VERSION ""

NS_ :

BS_:

BU_: FUSION ZONE_FR ZONE_DR DKC

BO_ 596 GW_ZoneFR3: 32 ZONE_FR
 SG_ EXV_Rsp_Pos : 7|16@0+ (1,0) [0|576] "" FUSION
 SG_ EXV_Rsp_Fault_Stat : 23|4@0+ (1,0) [0|1] "" FUSION
 SG_ EXV_Rsp_CurInit_Stat : 19|2@0+ (1,0) [0|1] "" FUSION
 SG_ EXV_Rsp_OvrTemp_Warn : 17|2@0+ (1,0) [0|1] "" FUSION
 SG_ EXV_Rsp_Volt_Stat : 31|2@0+ (1,0) [0|1] "" FUSION
 SG_ EXV_RsErr_EXV : 29|1@0+ (1,0) [0|1] "" FUSION
 SG_ EXV_Rsp_Run_Stat : 28|1@0+ (1,0) [0|1] "" FUSION
 SG_ EWP1_RsErr_EWP : 26|1@0+ (1,0) [0|1] "" FUSION
 SG_ EWP1_SupVolt_Error : 25|2@0+ (1,0) [0|2] "" FUSION
 SG_ EWP1_RPM_Target_Stat : 39|8@0+ (1,0) [0|254] "" FUSION
 SG_ EWP1_RPM_ActlVal_Stat : 47|8@0+ (1,0) [0|254] "" FUSION
 SG_ EWP1_Curr_Stat : 55|8@0+ (0.1,0) [0|25.4] "A" FUSION
 SG_ EWP1_Block_Error : 63|2@0+ (1,0) [0|2] "" FUSION
 SG_ EWP1_DryRun_Error : 61|2@0+ (1,0) [0|2] "" FUSION
 SG_ EWP1_OverCurr_Error : 59|2@0+ (1,0) [0|2] "" FUSION
 SG_ EWP1_OverTemp_Error : 57|2@0+ (1,0) [0|2] "" FUSION
 SG_ EWP1_Temp_Stat : 71|8@0+ (1,-50) [-50|205] "Deg" FUSION
 SG_ EWP1_Volt_Stat : 79|8@0+ (0.1,0) [0|25.5] "V" FUSION
 SG_ EWP2_Volt_Stat : 87|8@0+ (0.1,0) [0|25.4] "V" FUSION
 SG_ EWP2_Temp_Stat : 95|8@0+ (1,-50) [-50|205] "Deg" FUSION
 SG_ EWP2_RPM_Target_Stat : 103|8@0+ (1,0) [0|254] "" FUSION
 SG_ EWP2_RPM_ActlVal_Stat : 111|8@0+ (1,0) [0|254] "" FUSION
 SG_ EWP2_Curr_Stat : 119|8@0+ (0.1,0) [0|25.4] "A" FUSION
 SG_ EWP2_Block_Error : 127|2@0+ (1,0) [0|2] "" FUSION
 SG_ EWP2_DryRun_Error : 125|2@0+ (1,0) [0|2] "" FUSION
 SG_ EWP2_OverCurr_Error : 123|2@0+ (1,0) [0|2] "" FUSION
 SG_ EWP2_OverTemp_Error : 121|2@0+ (1,0) [0|2] "" FUSION
 SG_ EWP2_SupVolt_Error : 135|2@0+ (1,0) [0|2] "" FUSION
 SG_ EWP2_RsErr_EWP : 133|1@0+ (1,0) [0|1] "" FUSION
 SG_ EWP3_Block_Error : 131|2@0+ (1,0) [0|2] "" FUSION
 SG_ EWP3_DryRun_Error : 129|2@0+ (1,0) [0|2] "" FUSION
 SG_ EWP3_RPM_Target_Stat : 143|8@0+ (1,0) [0|254] "" FUSION
 SG_ EWP3_RPM_ActlVal_Stat : 151|8@0+ (1,0) [0|254] "" FUSION
 SG_ EWP3_Curr_Stat : 159|8@0+ (0.1,0) [0|25.4] "A" FUSION
 SG_ EWP3_OverCurr_Error : 167|2@0+ (1,0) [0|2] "" FUSION
 SG_ EWP3_OverTemp_Error : 165|2@0+ (1,0) [0|2] "" FUSION
 SG_ EWP3_SupVolt_Error : 163|2@0+ (1,0) [0|2] "" FUSION
 SG_ EWP3_RsErr_EWP : 161|1@0+ (1,0) [0|1] "" FUSION
 SG_ EWP3_Temp_Stat : 175|8@0+ (1,-50) [-50|205] "Deg" FUSION
 SG_ EWP3_Volt_Stat : 183|8@0+ (0.1,0) [0|25.4] "V" FUSION
 SG_ EXV2_Rsp_Pos : 191|16@0+ (1,0) [0|576] "" FUSION
 SG_ EXV2_Rsp_Fault_Stat : 207|4@0+ (1,0) [0|1] "" FUSION
 SG_ EXV2_Rsp_CurInit_Stat : 203|2@0+ (1,0) [0|1] "" FUSION
 SG_ EXV2_Rsp_OvrTemp_Warn : 201|2@0+ (1,0) [0|1] "" FUSION
 SG_ EXV2_Rsp_Volt_Stat : 215|2@0+ (1,0) [0|1] "" FUSION
 SG_ EXV2_RsErr_EXV : 213|1@0+ (1,0) [0|1] "" FUSION
 SG_ EXV2_Rsp_Run_Stat : 212|1@0+ (1,0) [0|1] "" FUSION
 SG_ CCV4_Fault_Signal : 211|4@0+ (1,0) [0|1] "" FUSION
 SG_ BDC_1_Rsp_Comm_Err : 223|1@0+ (1,0) [0|1] "" FUSION
 SG_ CCV4_TempWarn : 222|1@0+ (1,0) [0|1] "" FUSION
 SG_ CCV4_Rsp_Comm_Err : 221|1@0+ (1,0) [0|1] "" FUSION
 SG_ CCV4_MotorStatus : 220|1@0+ (1,0) [0|1] "" FUSION
 SG_ CCV4_RespPos : 219|2@0+ (1,0) [0|1] "" FUSION
 SG_ CCV4_voltageErr : 217|2@0+ (1,0) [0|1] "" FUSION
 SG_ BDC_1_Fault_Signal : 231|4@0+ (1,0) [0|1] "" FUSION
 SG_ BDC_1_voltageErr : 227|2@0+ (1,0) [0|1] "" FUSION
 SG_ BDC_1_TempWarn : 225|1@0+ (1,0) [0|1] "" FUSION
 SG_ BDC_1_MotorStatus : 224|1@0+ (1,0) [0|1] "" FUSION
 SG_ BDC_1_RespPos : 239|8@0+ (0.392,0) [0|99.96] "" FUSION

BO_ 602 GW_METER1: 24 FUSION
 SG_ METER_KPH_Calcu : 15|8@0+ (1,0) [0|254] "km/h" ZONE_DR
 SG_ METER_MPH_Calcu : 23|8@0+ (1,0) [0|160] "mph" Vector__XXX
 SG_ METER_KPH_Real : 31|12@0+ (0.125,0) [0|255.875] "km/h" Vector__XXX
 SG_ METER_MPH_Real : 35|12@0+ (0.077675,0) [0|160.0105] "mph" Vector__XXX
 SG_ Averaged_vehspeed : 49|10@0+ (1,0) [0|300] "km/h" Vector__XXX
 SG_ AVGPwrConsumption : 71|16@0+ (0.1,-999.9) [-999.9|999.9] "Wh/km" Vector__XXX
 SG_ APCforDTE : 87|16@0+ (0.1,-999.9) [-999.9|999.9] "Wh/km" Vector__XXX
 SG_ AvailableTrip : 103|16@0+ (0.1,0) [0|999.9] "KM" Vector__XXX
 SG_ Spd_Crl_Mode : 118|3@0+ (1,0) [0|7] "" Vector__XXX
 SG_ Spd_Crl_Sta : 115|1@0+ (1,0) [0|1] "" Vector__XXX
 SG_ LEDlitWarnReq : 114|1@0+ (1,0) [0|1] "" Vector__XXX
 SG_ Charge : 113|1@0+ (1,0) [0|1] "" Vector__XXX
 SG_ ParkBrake : 112|1@0+ (1,0) [0|1] "" Vector__XXX
 SG_ Trip_B : 127|24@0+ (0.1,0) [0|99999.9] "KM" Vector__XXX
 SG_ Trip_A : 151|24@0+ (0.1,0) [0|99999.9] "KM" Vector__XXX
 SG_ ODOMETER : 175|24@0+ (0.1,0) [0|999999.9] "KM" Vector__XXX

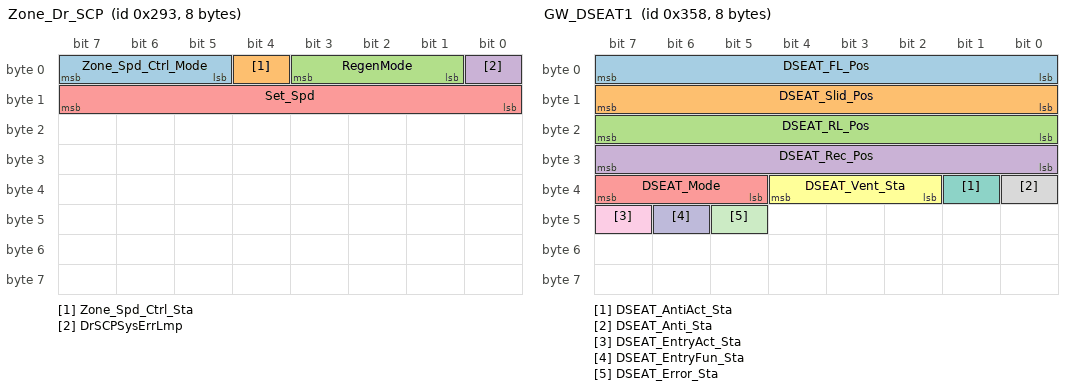
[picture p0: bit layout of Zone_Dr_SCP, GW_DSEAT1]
BO_ 659 Zone_Dr_SCP: 8 ZONE_DR
 SG_ Zone_Spd_Ctrl_Mode : 7|3@0+ (1,0) [0|7] "" FUSION
 SG_ Zone_Spd_Ctrl_Sta : 4|1@0+ (1,0) [0|1] "" FUSION
 SG_ RegenMode : 3|3@0+ (1,0) [0|7] "" FUSION
 SG_ DrSCPSysErrLmp : 0|1@0+ (1,0) [0|1] "" FUSION
 SG_ Set_Spd : 15|8@0+ (1,0) [0|255] "km/h" FUSION

BO_ 778 GW_ZoneFR2: 32 ZONE_FR
 SG_ PTCActuPWMDutyHSC6 : 7|8@0+ (0.5,0) [0|100] "" FUSION
 SG_ PTCIGBTTemHSC6 : 15|9@0+ (0.5,-40) [-40|200] "" FUSION
 SG_ CCM_SpdCmd : 22|15@0+ (0.5,0) [0|8300] "RPM" FUSION
 SG_ EAC_Temp : 39|8@0+ (1,-40) [0|210] "Deg^C" FUSION
 SG_ PTCNTCStsHSC6 : 47|3@0+ (1,0) [0|7] "" FUSION
 SG_ EAC_DrvVoltFalt : 63|1@0+ (1,0) [0|1] "" FUSION
 SG_ EAC_MotorLackFalt : 62|1@0+ (1,0) [0|1] "" FUSION
 SG_ EAC_OvLoadFalt : 61|1@0+ (1,0) [0|1] "" FUSION
 SG_ EAC_TempSnsrFalt : 60|1@0+ (1,0) [0|1] "" FUSION
 SG_ CompProEN : 59|1@0+ (1,0) [0|1] "" FUSION
 SG_ COMP_ComLost : 58|1@0+ (1,0) [0|1] "" FUSION
 SG_ COMP_IPM_HWFLt : 57|1@0+ (1,0) [0|1] "" FUSION
 SG_ COMP_IPM_TempOverFlt : 56|1@0+ (1,0) [0|1] "" FUSION
 SG_ COMP_CurOverProtect : 71|1@0+ (1,0) [0|1] "" FUSION
 SG_ COMP_VoltOverErr : 70|1@0+ (1,0) [0|1] "" FUSION
 SG_ COMP_VoltLessErr : 69|1@0+ (1,0) [0|1] "" FUSION
 SG_ COMP_CtrlCircFlt : 68|1@0+ (1,0) [0|1] "" FUSION
 SG_ COMP_Sta : 67|2@0+ (1,0) [0|3] "" FUSION
 SG_ COMP_Init : 65|1@0+ (1,0) [0|1] "" FUSION
 SG_ COMP_SpdVaild : 64|1@0+ (1,0) [0|1] "" FUSION
 SG_ EAC_MotCrt : 79|8@0+ (0.2,0) [0|51] "A" FUSION
 SG_ COMP_CurVaild : 87|1@0+ (1,0) [0|1] "" FUSION
 SG_ COMP_VoltVaild : 86|1@0+ (1,0) [0|1] "" FUSION
 SG_ COMP_StatorSpd : 85|14@0+ (1,0) [0|8500] "RPM" FUSION
 SG_ COMP_ConCur : 103|16@0+ (0.02,0) [0|1310.7] "A" FUSION
 SG_ COMP_ConVolt : 119|16@0+ (0.02,0) [0|1310.7] "V" FUSION
 SG_ PTCSecRlngCtrHSC6 : 135|4@0+ (1,0) [0|15] "" FUSION
 SG_ PTCOtptTemHSC6 : 128|9@0+ (0.5,-40) [-40|200] "" FUSION
 SG_ PTCRlngCtrHSC6 : 151|4@0+ (1,0) [0|15] "" FUSION
 SG_ PTCOverVolHSC6 : 131|1@0+ (1,0) [0|1] "" FUSION
 SG_ PTCOverCrntHSC6 : 130|1@0+ (1,0) [0|1] "" FUSION
 SG_ PTCOverHeatHSC6 : 129|1@0+ (1,0) [0|1] "" FUSION
 SG_ PTCPCBTemHSC6 : 144|9@0+ (0.5,-40) [-40|200] "" FUSION
 SG_ PTCActuCrntHSC6 : 161|10@0+ (0.1,-20) [-20|82] "" FUSION
 SG_ PTCStsHSC6 : 166|2@0+ (1,0) [0|3] "" FUSION
 SG_ PTCIGBTOverHeatHSC6 : 145|1@0+ (1,0) [0|1] "" FUSION
 SG_ PTCHVLckStsHSC6 : 146|1@0+ (1,0) [0|1] "" FUSION
 SG_ PTCIGBTStsHSC6 : 147|1@0+ (1,0) [0|1] "" FUSION
 SG_ PTCUnderVolHSC6 : 167|1@0+ (1,0) [0|1] "" FUSION
 SG_ PTCFltLvlHSC6 : 199|4@0+ (1,0) [0|15] "" FUSION
 SG_ PTCChksmHSC6 : 183|8@0+ (1,0) [0|255] "" FUSION
 SG_ PTCSecChksmHSC6 : 191|8@0+ (1,0) [0|255] "" FUSION
 SG_ PTCActuVolHSC6 : 193|10@0+ (0.5,100) [100|500] "" FUSION
 SG_ BMSPackVol_h6HSC6 : 211|12@0+ (0.25,0) [0|1023.75] "V" FUSION

BO_ 796 GW_ZoneFR4: 12 ZONE_FR
 SG_ BMSReqRlngCtrHSC6 : 7|4@0+ (1,0) [0|15] "" FUSION
 SG_ BMSReqTapPosHSC6 : 3|4@0+ (1,0) [0|15] "" FUSION
 SG_ BMSReqPwrHSC6 : 15|16@0+ (1,0) [0|65535] "" FUSION
 SG_ BMSReqPWMHSC6 : 31|7@0+ (1,0) [0|100] "" FUSION
 SG_ BMSInptClntTemHSC6 : 24|9@0+ (0.5,-40) [-40|200] "" FUSION
 SG_ BMSReqMdHSC6 : 71|2@0+ (1,0) [0|3] "" FUSION
 SG_ BMSEnbPTCHSC6 : 69|1@0+ (1,0) [0|1] "" FUSION
 SG_ BMSChksmHSC6 : 47|8@0+ (1,0) [0|255] "" FUSION
 SG_ PTCActuPwrHSC6 : 55|16@0+ (1,0) [0|65535] "" FUSION
 SG_ COMP_ActualPwr : 68|13@0+ (1,0) [0|6000] "W" FUSION

BO_ 804 GW_ZoneDR7: 48 ZONE_DR
 SG_ ACT5_Stop_mode_status : 71|2@0+ (1,0) [0|0] "" FUSION
 SG_ ACT5_Rotation_direction_status : 69|2@0+ (1,0) [0|0] "" FUSION
 SG_ ACT5_Emergency_run_position_status : 67|2@0+ (1,0) [0|0] "" FUSION
 SG_ ACT5_Emergency_run_release_status : 65|2@0+ (1,0) [0|0] "" FUSION
 SG_ ACT5_Actuator_address_status : 79|8@0+ (1,0) [0|0] "" FUSION
 SG_ ACT5_Special_functions : 85|2@0+ (1,0) [0|0] "" FUSION
 SG_ ACT5_Self_holding_torque : 83|2@0+ (1,0) [0|0] "" FUSION
 SG_ ACT5_Movement_direction : 81|2@0+ (1,0) [0|0] "" FUSION
 SG_ ACT5_Actual_position_of_actuator : 95|16@0+ (1,0) [0|0] "" FUSION
 SG_ ACT5_Speed_status : 111|4@0+ (1,0) [0|0] "" FUSION
 SG_ ACT5_Position_specification_status : 107|2@0+ (1,0) [0|0] "" FUSION
 SG_ ACT5_Applied_holding_current_status : 105|2@0+ (1,0) [0|0] "" FUSION
 SG_ ACT5_Reset : 119|2@0+ (1,0) [0|0] "" FUSION
 SG_ ACT5_Stall_occurred : 117|2@0+ (1,0) [0|0] "" FUSION
 SG_ ACT5_Stall_detection_release_status : 115|2@0+ (1,0) [0|0] "" FUSION
 SG_ ACT5_Emergency_run_occurred : 113|2@0+ (1,0) [0|0] "" FUSION
 SG_ ACT5_Supply_voltage : 127|2@0+ (1,0) [0|0] "" FUSION
 SG_ ACT5_Electrical_defect : 125|2@0+ (1,0) [0|0] "" FUSION
 SG_ ACT5_Over_temperature : 123|2@0+ (1,0) [0|0] "" FUSION
 SG_ ACT5_Response_Error : 120|1@0+ (1,0) [0|0] "" FUSION
 SG_ ACT4_Stop_mode_status : 135|2@0+ (1,0) [0|0] "" FUSION
 SG_ ACT4_Rotation_direction_status : 133|2@0+ (1,0) [0|0] "" FUSION
 SG_ ACT4_Emergency_run_position_status : 131|2@0+ (1,0) [0|0] "" FUSION
 SG_ ACT4_Emergency_run_release_status : 129|2@0+ (1,0) [0|0] "" FUSION
 SG_ ACT4_Actuator_address_status : 143|8@0+ (1,0) [0|0] "" FUSION
 SG_ ACT4_Special_functions : 149|2@0+ (1,0) [0|0] "" FUSION
 SG_ ACT4_Self_holding_torque : 147|2@0+ (1,0) [0|0] "" FUSION
 SG_ ACT4_Movement_direction : 145|2@0+ (1,0) [0|0] "" FUSION
 SG_ ACT4_Actual_position_of_actuator : 159|16@0+ (1,0) [0|0] "" FUSION
 SG_ ACT4_Speed_status : 175|4@0+ (1,0) [0|0] "" FUSION
 SG_ ACT4_Position_specification_status : 171|2@0+ (1,0) [0|0] "" FUSION
 SG_ ACT4_Applied_holding_current_status : 169|2@0+ (1,0) [0|0] "" FUSION
 SG_ ACT4_Reset : 183|2@0+ (1,0) [0|0] "" FUSION
 SG_ ACT4_Stall_occurred : 181|2@0+ (1,0) [0|0] "" FUSION
 SG_ ACT4_Stall_detection_release_status : 179|2@0+ (1,0) [0|0] "" FUSION
 SG_ ACT4_Emergency_run_occurred : 177|2@0+ (1,0) [0|0] "" FUSION
 SG_ ACT4_Supply_voltage : 191|2@0+ (1,0) [0|0] "" FUSION
 SG_ ACT4_Electrical_defect : 189|2@0+ (1,0) [0|0] "" FUSION
 SG_ ACT4_Over_temperature : 187|2@0+ (1,0) [0|0] "" FUSION
 SG_ ACT4_Response_Error : 184|1@0+ (1,0) [0|0] "" FUSION
 SG_ ACT3_Stop_mode_status : 199|2@0+ (1,0) [0|0] "" FUSION
 SG_ ACT3_Rotation_direction_status : 197|2@0+ (1,0) [0|0] "" FUSION
 SG_ ACT3_Emergency_run_position_status : 195|2@0+ (1,0) [0|0] "" FUSION
 SG_ ACT3_Emergency_run_release_status : 193|2@0+ (1,0) [0|0] "" FUSION
 SG_ ACT3_Actuator_address_status : 207|8@0+ (1,0) [0|0] "" FUSION
 SG_ ACT3_Special_functions : 213|2@0+ (1,0) [0|0] "" FUSION
 SG_ ACT3_Self_holding_torque : 211|2@0+ (1,0) [0|0] "" FUSION
 SG_ ACT3_Movement_direction : 209|2@0+ (1,0) [0|0] "" FUSION
 SG_ ACT3_Actual_position_of_actuator : 223|16@0+ (1,0) [0|0] "" FUSION
 SG_ ACT3_Speed_status : 239|4@0+ (1,0) [0|0] "" FUSION
 SG_ ACT3_Position_specification_status : 235|2@0+ (1,0) [0|0] "" FUSION
 SG_ ACT3_Applied_holding_current_status : 233|2@0+ (1,0) [0|0] "" FUSION
 SG_ ACT3_Reset : 247|2@0+ (1,0) [0|0] "" FUSION
 SG_ ACT3_Stall_occurred : 245|2@0+ (1,0) [0|0] "" FUSION
 SG_ ACT3_Stall_detection_release_status : 243|2@0+ (1,0) [0|0] "" FUSION
 SG_ ACT3_Emergency_run_occurred : 241|2@0+ (1,0) [0|0] "" FUSION
 SG_ ACT3_Supply_voltage : 255|2@0+ (1,0) [0|0] "" FUSION
 SG_ ACT3_Electrical_defect : 253|2@0+ (1,0) [0|0] "" FUSION
 SG_ ACT3_Over_temperature : 251|2@0+ (1,0) [0|0] "" FUSION
 SG_ ACT3_Response_Error : 248|1@0+ (1,0) [0|0] "" FUSION
 SG_ ACT2_Stop_mode_status : 263|2@0+ (1,0) [0|0] "" FUSION
 SG_ ACT2_Rotation_direction_status : 261|2@0+ (1,0) [0|0] "" FUSION
 SG_ ACT2_Emergency_run_position_status : 259|2@0+ (1,0) [0|0] "" FUSION
 SG_ ACT2_Emergency_run_release_status : 257|2@0+ (1,0) [0|0] "" FUSION
 SG_ ACT2_Actuator_address_status : 271|8@0+ (1,0) [0|0] "" FUSION
 SG_ ACT2_Special_functions : 277|2@0+ (1,0) [0|0] "" FUSION
 SG_ ACT2_Self_holding_torque : 275|2@0+ (1,0) [0|0] "" FUSION
 SG_ ACT2_Movement_direction : 273|2@0+ (1,0) [0|0] "" FUSION
 SG_ ACT2_Actual_position_of_actuator : 287|16@0+ (1,0) [0|0] "" FUSION
 SG_ ACT2_Speed_status : 303|4@0+ (1,0) [0|0] "" FUSION
 SG_ ACT2_Position_specification_status : 299|2@0+ (1,0) [0|0] "" FUSION
 SG_ ACT2_Applied_holding_current_status : 297|2@0+ (1,0) [0|0] "" FUSION
 SG_ ACT2_Reset : 311|2@0+ (1,0) [0|0] "" FUSION
 SG_ ACT2_Stall_occurred : 309|2@0+ (1,0) [0|0] "" FUSION
 SG_ ACT2_Stall_detection_release_status : 307|2@0+ (1,0) [0|0] "" FUSION
 SG_ ACT2_Emergency_run_occurred : 305|2@0+ (1,0) [0|0] "" FUSION
 SG_ ACT2_Supply_voltage : 319|2@0+ (1,0) [0|0] "" FUSION
 SG_ ACT2_Electrical_defect : 317|2@0+ (1,0) [0|0] "" FUSION
 SG_ ACT2_Over_temperature : 315|2@0+ (1,0) [0|0] "" FUSION
 SG_ ACT2_Response_Error : 312|1@0+ (1,0) [0|0] "" FUSION
 SG_ ACT1_Stop_mode_status : 327|2@0+ (1,0) [0|0] "" FUSION
 SG_ ACT1_Rotation_direction_status : 325|2@0+ (1,0) [0|0] "" FUSION
 SG_ ACT1_Emergency_run_position_status : 323|2@0+ (1,0) [0|0] "" FUSION
 SG_ ACT1_Emergency_run_release_status : 321|2@0+ (1,0) [0|0] "" FUSION
 SG_ ACT1_Actuator_address_status : 335|8@0+ (1,0) [0|0] "" FUSION
 SG_ ACT1_Special_functions : 341|2@0+ (1,0) [0|0] "" FUSION
 SG_ ACT1_Self_holding_torque : 339|2@0+ (1,0) [0|0] "" FUSION
 SG_ ACT1_Movement_direction : 337|2@0+ (1,0) [0|0] "" FUSION
 SG_ ACT1_Actual_position_of_actuator : 351|16@0+ (1,0) [0|0] "" FUSION
 SG_ ACT1_Speed_status : 367|4@0+ (1,0) [0|0] "" FUSION
 SG_ ACT1_Position_specification_status : 363|2@0+ (1,0) [0|0] "" FUSION
 SG_ ACT1_Applied_holding_current_status : 361|2@0+ (1,0) [0|0] "" FUSION
 SG_ ACT1_Reset : 375|2@0+ (1,0) [0|0] "" FUSION
 SG_ ACT1_Stall_occurred : 373|2@0+ (1,0) [0|0] "" FUSION
 SG_ ACT1_Stall_detection_release_status : 371|2@0+ (1,0) [0|0] "" FUSION
 SG_ ACT1_Emergency_run_occurred : 369|2@0+ (1,0) [0|0] "" FUSION
 SG_ ACT1_Supply_voltage : 383|2@0+ (1,0) [0|0] "" FUSION
 SG_ ACT1_Electrical_defect : 381|2@0+ (1,0) [0|0] "" FUSION
 SG_ ACT1_Over_temperature : 379|2@0+ (1,0) [0|0] "" FUSION
 SG_ ACT1_Response_Error : 376|1@0+ (1,0) [0|0] "" FUSION

BO_ 805 GW_ZoneDR8: 48 ZONE_DR
 SG_ ACT5_Stop_mode : 71|2@0+ (1,0) [0|1] "" FUSION
 SG_ ACT5_Rotation_direction : 69|2@0+ (1,0) [0|0] "" FUSION
 SG_ ACT5_Emergency_run_position : 67|2@0+ (1,0) [0|0] "" FUSION
 SG_ ACT5_Emergency_run_release : 65|2@0+ (1,0) [0|0] "" FUSION
 SG_ ACT5_Actuator_start_position : 79|16@0+ (1,0) [0|0] "" FUSION
 SG_ ACT5_Actuator_set_position : 95|16@0+ (1,0) [0|0] "" FUSION
 SG_ ACT5_Speed_specification : 111|4@0+ (1,0) [0|1] "" FUSION
 SG_ ACT5_Select_position_specification : 107|2@0+ (1,0) [0|1] "" FUSION
 SG_ ACT5_Applied_holding_current : 105|2@0+ (1,0) [0|0] "" FUSION
 SG_ ACT5_Clear_Event_Flags : 119|4@0+ (1,0) [0|1] "" FUSION
 SG_ ACT5_Stall_detection_release : 115|2@0+ (1,0) [0|0] "" FUSION
 SG_ ACT5_Save_programming_data : 113|2@0+ (1,0) [0|0] "" FUSION
 SG_ ACT5_Actuator_address : 127|8@0+ (1,0) [1|126] "" FUSION
 SG_ ACT4_Stop_mode : 135|2@0+ (1,0) [0|1] "" FUSION
 SG_ ACT4_Rotation_direction : 133|2@0+ (1,0) [0|0] "" FUSION
 SG_ ACT4_Emergency_run_position : 131|2@0+ (1,0) [0|0] "" FUSION
 SG_ ACT4_Emergency_run_release : 129|2@0+ (1,0) [0|0] "" FUSION
 SG_ ACT4_Actuator_start_position : 143|16@0+ (1,0) [0|0] "" FUSION
 SG_ ACT4_Actuator_set_position : 159|16@0+ (1,0) [0|0] "" FUSION
 SG_ ACT4_Speed_specification : 175|4@0+ (1,0) [0|1] "" FUSION
 SG_ ACT4_Select_position_specification : 171|2@0+ (1,0) [0|1] "" FUSION
 SG_ ACT4_Applied_holding_current : 169|2@0+ (1,0) [0|0] "" FUSION
 SG_ ACT4_Clear_Event_Flags : 183|4@0+ (1,0) [0|1] "" FUSION
 SG_ ACT4_Stall_detection_release : 179|2@0+ (1,0) [0|0] "" FUSION
 SG_ ACT4_Save_programming_data : 177|2@0+ (1,0) [0|0] "" FUSION
 SG_ ACT4_Actuator_address : 191|8@0+ (1,0) [1|126] "" FUSION
 SG_ ACT3_Stop_mode : 199|2@0+ (1,0) [0|1] "" FUSION
 SG_ ACT3_Rotation_direction : 197|2@0+ (1,0) [0|0] "" FUSION
 SG_ ACT3_Emergency_run_position : 195|2@0+ (1,0) [0|0] "" FUSION
 SG_ ACT3_Emergency_run_release : 193|2@0+ (1,0) [0|0] "" FUSION
 SG_ ACT3_Actuator_start_position : 207|16@0+ (1,0) [0|0] "" FUSION
 SG_ ACT3_Actuator_set_position : 223|16@0+ (1,0) [0|0] "" FUSION
 SG_ ACT3_Speed_specification : 239|4@0+ (1,0) [0|1] "" FUSION
 SG_ ACT3_Select_position_specification : 235|2@0+ (1,0) [0|1] "" FUSION
 SG_ ACT3_Applied_holding_current : 233|2@0+ (1,0) [0|0] "" FUSION
 SG_ ACT3_Clear_Event_Flags : 247|4@0+ (1,0) [0|1] "" FUSION
 SG_ ACT3_Stall_detection_release : 243|2@0+ (1,0) [0|0] "" FUSION
 SG_ ACT3_Save_programming_data : 241|2@0+ (1,0) [0|0] "" FUSION
 SG_ ACT3_Actuator_address : 255|8@0+ (1,0) [1|126] "" FUSION
 SG_ ACT2_Stop_mode : 263|2@0+ (1,0) [0|1] "" FUSION
 SG_ ACT2_Rotation_direction : 261|2@0+ (1,0) [0|0] "" FUSION
 SG_ ACT2_Emergency_run_position : 259|2@0+ (1,0) [0|0] "" FUSION
 SG_ ACT2_Emergency_run_release : 257|2@0+ (1,0) [0|0] "" FUSION
 SG_ ACT2_Actuator_start_position : 271|16@0+ (1,0) [0|0] "" FUSION
 SG_ ACT2_Actuator_set_position : 287|16@0+ (1,0) [0|0] "" FUSION
 SG_ ACT2_Speed_specification : 303|4@0+ (1,0) [0|1] "" FUSION
 SG_ ACT2_Select_position_specification : 299|2@0+ (1,0) [0|1] "" FUSION
 SG_ ACT2_Applied_holding_current : 297|2@0+ (1,0) [0|0] "" FUSION
 SG_ ACT2_Clear_Event_Flags : 311|4@0+ (1,0) [0|1] "" FUSION
 SG_ ACT2_Stall_detection_release : 307|2@0+ (1,0) [0|0] "" FUSION
 SG_ ACT2_Save_programming_data : 305|2@0+ (1,0) [0|0] "" FUSION
 SG_ ACT2_Actuator_address : 319|8@0+ (1,0) [1|126] "" FUSION
 SG_ ACT1_Stop_mode : 327|2@0+ (1,0) [0|1] "" FUSION
 SG_ ACT1_Rotation_direction : 325|2@0+ (1,0) [0|0] "" FUSION
 SG_ ACT1_Emergency_run_position : 323|2@0+ (1,0) [0|0] "" FUSION
 SG_ ACT1_Emergency_run_release : 321|2@0+ (1,0) [0|0] "" FUSION
 SG_ ACT1_Actuator_start_position : 335|16@0+ (1,0) [0|0] "" FUSION
 SG_ ACT1_Actuator_set_position : 351|16@0+ (1,0) [0|0] "" FUSION
 SG_ ACT1_Speed_specification : 367|4@0+ (1,0) [0|1] "" FUSION
 SG_ ACT1_Select_position_specification : 363|2@0+ (1,0) [0|1] "" FUSION
 SG_ ACT1_Applied_holding_current : 361|2@0+ (1,0) [0|0] "" FUSION
 SG_ ACT1_Clear_Event_Flags : 375|4@0+ (1,0) [0|1] "" FUSION
 SG_ ACT1_Stall_detection_release : 371|2@0+ (1,0) [0|0] "" FUSION
 SG_ ACT1_Save_programming_data : 369|2@0+ (1,0) [0|0] "" FUSION
 SG_ ACT1_Actuator_address : 383|8@0+ (1,0) [1|126] "" FUSION

BO_ 826 GW_ZoneDR2: 8 ZONE_DR
 SG_ SWC_A_SW_version : 7|16@0+ (0.01,0) [0|99.99] "" FUSION
 SG_ SWC_A_HW_version : 23|16@0+ (0.01,0) [0|99.99] "" FUSION
 SG_ SWC_Drivemode_Sta : 39|2@0+ (1,0) [0|1] "" FUSION
 SG_ SWC_CANCEL_Sta : 37|1@0+ (1,0) [0|1] "" FUSION
 SG_ SWC_ACC_Sta : 36|1@0+ (1,0) [0|1] "" FUSION
 SG_ SWC_A_Resp_Err : 34|1@0+ (1,0) [0|1] "" FUSION
 SG_ SWC_Distance_Sta : 32|1@0+ (1,0) [0|1] "" FUSION
 SG_ SWC_Down_Sta : 47|1@0+ (1,0) [0|1] "" FUSION
 SG_ SWC_RegenUp : 46|1@0+ (1,0) [0|1] "" FUSION
 SG_ SWC_Left_Sta : 45|1@0+ (1,0) [0|1] "" FUSION
 SG_ SWC_mode_Sta : 43|1@0+ (1,0) [0|1] "" FUSION
 SG_ SWC_resp_error : 55|1@0+ (1,0) [0|1] "" FUSION
 SG_ SWC_Res_Up_Sta : 54|1@0+ (1,0) [0|1] "" FUSION
 SG_ SWC_RegenDown : 53|1@0+ (1,0) [0|1] "" FUSION
 SG_ SWC_Right_Sta : 52|1@0+ (1,0) [0|1] "" FUSION
 SG_ SWC_Set_down_Sta : 51|1@0+ (1,0) [0|1] "" FUSION
 SG_ SWC_Trip_Sta : 50|1@0+ (1,0) [0|1] "" FUSION
 SG_ SWC_Up_Sta : 48|1@0+ (1,0) [0|1] "" FUSION
 SG_ SWC_VR_Sta : 63|1@0+ (1,0) [0|1] "" FUSION
 SG_ SWC_Undefined_Sta : 62|1@0+ (1,0) [0|1] "" FUSION
 SG_ SWC_LKA_Sta : 61|1@0+ (1,0) [0|1] "" FUSION

BO_ 851 GW_ZoneDR4: 8 ZONE_DR
 SG_ L_RRD_Wdw_Obs_InhibitSts : 20|1@0+ (1,0) [0|1] "" FUSION
 SG_ L_RRD_Wdw_OD_Sts : 19|1@0+ (1,0) [0|1] "" FUSION
 SG_ L_RRD_Wdw_Init : 18|1@0+ (1,0) [0|1] "" FUSION
 SG_ L_RRD_OverHeat_Protect : 17|1@0+ (1,0) [0|1] "" FUSION
 SG_ L_RRD_Motor_Relay_Error : 16|1@0+ (1,0) [0|1] "" FUSION
 SG_ L_RRD_Motor_Ripple_Error : 31|1@0+ (1,0) [0|1] "" FUSION
 SG_ L_RRD_Val_Wdw_Opened : 30|7@0+ (1,0) [0|100] "%" FUSION
 SG_ L_RRD_Wdw_PositionSts : 39|2@0+ (1,0) [0|3] "" FUSION
 SG_ L_RRD_Wdw_LocalSwitch : 37|3@0+ (1,0) [0|7] "" FUSION
 SG_ L_RRD_Wdw_Running_Sts : 34|3@0+ (1,0) [0|7] "" FUSION
 SG_ RAPWL_01_LIN_Response_Error : 45|1@0+ (1,0) [0|1] "" FUSION
 SG_ L_RLD_Wdw_Obs_InhibitSts : 44|1@0+ (1,0) [0|1] "" FUSION
 SG_ L_RLD_Wdw_OD_Sts : 43|1@0+ (1,0) [0|1] "" FUSION
 SG_ L_RLD_Wdw_Init : 42|1@0+ (1,0) [0|1] "" FUSION
 SG_ L_RLD_OverHeat_Protect : 41|1@0+ (1,0) [0|1] "" FUSION
 SG_ L_RLD_Motor_Relay_Error : 40|1@0+ (1,0) [0|1] "" FUSION
 SG_ L_RLD_Motor_Ripple_Error : 55|1@0+ (1,0) [0|1] "" FUSION
 SG_ L_RLD_Val_Wdw_Opened : 54|7@0+ (1,0) [0|100] "%" FUSION
 SG_ L_RLD_Wdw_PositionSts : 63|2@0+ (1,0) [0|3] "" FUSION
 SG_ L_RLD_Wdw_LocalSwitch : 61|3@0+ (1,0) [0|7] "" FUSION
 SG_ L_RLD_Wdw_Running_Sts : 58|3@0+ (1,0) [0|7] "" FUSION
 SG_ PTG_Inner_SW_2 : 47|2@0+ (1,0) [0|3] "" FUSION

BO_ 854 GW_ZoneDR3: 8 ZONE_DR
 SG_ L_APM_IntellectClose : 7|1@0+ (1,0) [0|1] "" FUSION
 SG_ L_Drv_Wdw_RRD_Switch : 1|3@0+ (1,0) [0|7] "" FUSION
 SG_ L_Drv_Wdw_RLD_Switch : 14|3@0+ (1,0) [0|7] "" FUSION
 SG_ L_Drv_Wdw_Pas_Switch : 11|3@0+ (1,0) [0|7] "" FUSION
 SG_ L_Pas_Wdw_Obs_InhibitSts : 21|1@0+ (1,0) [0|1] "" FUSION
 SG_ L_Pas_Wdw_OD_Sts : 20|1@0+ (1,0) [0|1] "" FUSION
 SG_ L_Pas_Wdw_Init : 19|1@0+ (1,0) [0|1] "" FUSION
 SG_ L_Pas_OverHeat_Protect : 18|1@0+ (1,0) [0|1] "" FUSION
 SG_ L_Pas_Motor_Relay_Error : 17|1@0+ (1,0) [0|1] "" FUSION
 SG_ L_Pas_Motor_Ripple_Error : 16|1@0+ (1,0) [0|1] "" FUSION
 SG_ L_Pas_Val_Wdw_Opened : 31|7@0+ (1,0) [0|100] "%" FUSION
 SG_ L_Pas_Wdw_PositionSts : 39|2@0+ (1,0) [0|3] "" FUSION
 SG_ L_Pas_Wdw_LocalSwitch : 37|3@0+ (1,0) [0|7] "" FUSION
 SG_ L_Pas_Wdw_Running_Sts : 34|3@0+ (1,0) [0|7] "" FUSION
 SG_ L_Power_Status : 47|2@0+ (1,0) [0|3] "" FUSION
 SG_ FAPWL_01_LIN_Response_Error : 45|1@0+ (1,0) [0|1] "" FUSION
 SG_ L_Drv_Wdw_Obs_InhibitSts : 44|1@0+ (1,0) [0|1] "" FUSION
 SG_ L_Drv_Wdw_OD_Sts : 43|1@0+ (1,0) [0|1] "" FUSION
 SG_ L_Drv_Wdw_Init : 42|1@0+ (1,0) [0|1] "" FUSION
 SG_ L_Drv_OverHeat_Protect : 41|1@0+ (1,0) [0|1] "" FUSION
 SG_ L_Drv_Motor_Relay_Error : 40|1@0+ (1,0) [0|1] "" FUSION
 SG_ L_Drv_Motor_Ripple_Error : 55|1@0+ (1,0) [0|1] "" FUSION
 SG_ L_Drv_Val_Wdw_Opened : 54|7@0+ (1,0) [0|100] "%" FUSION
 SG_ L_Drv_Wdw_PositionSts : 63|2@0+ (1,0) [0|3] "" FUSION
 SG_ L_Drv_Wdw_LocalSwitch : 61|3@0+ (1,0) [0|7] "" FUSION
 SG_ L_Drv_Wdw_Running_Sts : 58|3@0+ (1,0) [0|7] "" FUSION

BO_ 856 GW_DSEAT1: 8 ZONE_DR
 SG_ DSEAT_FL_Pos : 7|8@0+ (1,0) [0|25] "mm" FUSION
 SG_ DSEAT_Slid_Pos : 15|8@0+ (1,0) [0|240] "mm" FUSION
 SG_ DSEAT_RL_Pos : 23|8@0+ (1,0) [0|60] "mm" FUSION
 SG_ DSEAT_Rec_Pos : 31|8@0+ (1,0) [0|80] "deg" FUSION
 SG_ DSEAT_Mode : 39|3@0+ (1,0) [0|7] "" FUSION
 SG_ DSEAT_Vent_Sta : 36|3@0+ (1,0) [0|4] "" FUSION
 SG_ DSEAT_AntiAct_Sta : 33|1@0+ (1,0) [0|1] "" FUSION
 SG_ DSEAT_Anti_Sta : 32|1@0+ (1,0) [0|1] "" FUSION
 SG_ DSEAT_EntryAct_Sta : 47|1@0+ (1,0) [0|1] "" FUSION
 SG_ DSEAT_EntryFun_Sta : 46|1@0+ (1,0) [0|1] "" FUSION
 SG_ DSEAT_Error_Sta : 45|1@0+ (1,0) [0|1] "" FUSION

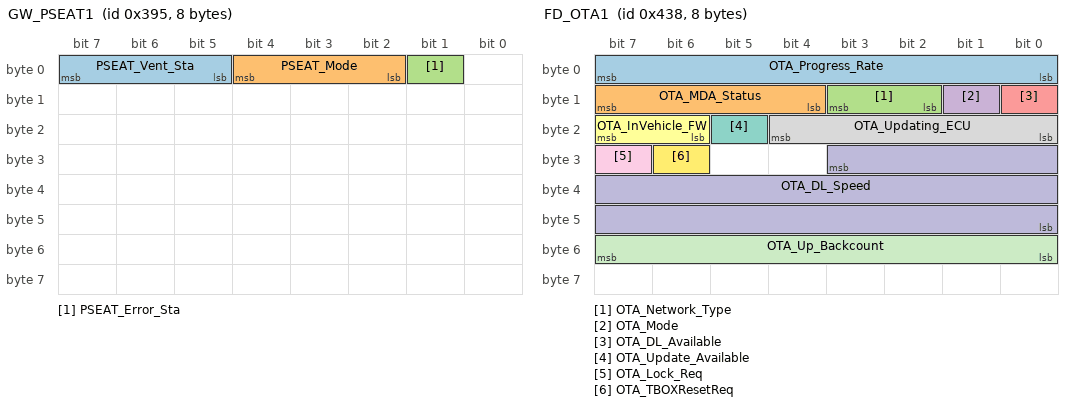
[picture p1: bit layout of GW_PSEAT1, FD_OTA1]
BO_ 917 GW_PSEAT1: 8 ZONE_DR
 SG_ PSEAT_Vent_Sta : 7|3@0+ (1,0) [0|4] "" FUSION
 SG_ PSEAT_Mode : 4|3@0+ (1,0) [0|7] "" FUSION
 SG_ PSEAT_Error_Sta : 1|1@0+ (1,0) [0|1] "" FUSION

BO_ 965 GW_ZoneDR5: 32 ZONE_DR
 SG_ ZONE_DR_SW_Var : 15|8@0+ (1,0) [0|255] "" FUSION
 SG_ ZONE_DR_SW_Country2 : 23|8@0+ (1,0) [0|255] "" FUSION
 SG_ ZONE_DR_SW_Country1 : 31|8@0+ (1,0) [0|255] "" FUSION
 SG_ ZONE_DR_SW_Patch2 : 39|8@0+ (1,0) [0|255] "" FUSION
 SG_ ZONE_DR_SW_Patch1 : 47|8@0+ (1,0) [0|255] "" FUSION
 SG_ ZONE_DR_SW_Minor2 : 55|8@0+ (1,0) [0|255] "" FUSION
 SG_ ZONE_DR_SW_Minor1 : 63|8@0+ (1,0) [0|255] "" FUSION
 SG_ ZONE_DR_SW_Major2 : 71|8@0+ (1,0) [0|255] "" FUSION
 SG_ ZONE_DR_SW_Major1 : 79|8@0+ (1,0) [0|255] "" FUSION
 SG_ ZONE_DR_SW_Controller2 : 87|8@0+ (1,0) [0|255] "" FUSION
 SG_ ZONE_DR_SW_Controller1 : 95|8@0+ (1,0) [0|255] "" FUSION
 SG_ ZONE_DR_SW_CarModel3 : 103|8@0+ (1,0) [0|255] "" FUSION
 SG_ ZONE_DR_SW_CarModel2 : 111|8@0+ (1,0) [0|255] "" FUSION
 SG_ ZONE_DR_SW_CarModel1 : 119|8@0+ (1,0) [0|255] "" FUSION
 SG_ ZONE_DR_HW_Ver3 : 127|8@0+ (1,0) [0|255] "" FUSION
 SG_ ZONE_DR_HW_Ver2 : 135|8@0+ (1,0) [0|255] "" FUSION
 SG_ ZONE_DR_HW_Ver1 : 143|8@0+ (1,0) [0|255] "" FUSION
 SG_ ZONE_DR_SW_dash1 : 151|8@0+ (1,0) [0|255] "" FUSION
 SG_ ZONE_DR_SW_change1 : 159|8@0+ (1,0) [0|255] "" FUSION
 SG_ ZONE_DR_SW_change2 : 167|8@0+ (1,0) [0|255] "" FUSION
 SG_ ZONE_DR_SW_dash2 : 175|8@0+ (1,0) [0|255] "" FUSION
 SG_ ZONE_DR_SW_SHA1 : 183|8@0+ (1,0) [0|255] "" FUSION
 SG_ ZONE_DR_SW_SHA2 : 191|8@0+ (1,0) [0|255] "" FUSION
 SG_ ZONE_DR_SW_SHA3 : 199|8@0+ (1,0) [0|255] "" FUSION
 SG_ ZONE_DR_SW_SHA4 : 207|8@0+ (1,0) [0|255] "" FUSION
 SG_ ZONE_DR_SW_SHA5 : 215|8@0+ (1,0) [0|255] "" FUSION
 SG_ ZONE_DR_SW_SHA6 : 223|8@0+ (1,0) [0|255] "" FUSION
 SG_ ZONE_DR_SW_SHA7 : 231|8@0+ (1,0) [0|255] "" FUSION
 SG_ ZONE_DR_SW_SHA8 : 239|8@0+ (1,0) [0|255] "" FUSION

BO_ 969 GW_ZoneFR5: 32 ZONE_FR
 SG_ ZONE_FR_SW_Var : 15|8@0+ (1,0) [0|255] "" FUSION
 SG_ ZONE_FR_SW_Country2 : 23|8@0+ (1,0) [0|255] "" FUSION
 SG_ ZONE_FR_SW_Country1 : 31|8@0+ (1,0) [0|255] "" FUSION
 SG_ ZONE_FR_SW_Patch2 : 39|8@0+ (1,0) [0|255] "" FUSION
 SG_ ZONE_FR_SW_Patch1 : 47|8@0+ (1,0) [0|255] "" FUSION
 SG_ ZONE_FR_SW_Minor2 : 55|8@0+ (1,0) [0|255] "" FUSION
 SG_ ZONE_FR_SW_Minor1 : 63|8@0+ (1,0) [0|255] "" FUSION
 SG_ ZONE_FR_SW_Major2 : 71|8@0+ (1,0) [0|255] "" FUSION
 SG_ ZONE_FR_SW_Major1 : 79|8@0+ (1,0) [0|255] "" FUSION
 SG_ ZONE_FR_SW_Controller2 : 87|8@0+ (1,0) [0|255] "" FUSION
 SG_ ZONE_FR_SW_Controller1 : 95|8@0+ (1,0) [0|255] "" FUSION
 SG_ ZONE_FR_SW_CarModel3 : 103|8@0+ (1,0) [0|255] "" FUSION
 SG_ ZONE_FR_SW_CarModel2 : 111|8@0+ (1,0) [0|255] "" FUSION
 SG_ ZONE_FR_SW_CarModel1 : 119|8@0+ (1,0) [0|255] "" FUSION
 SG_ ZONE_FR_HW_Ver3 : 127|8@0+ (1,0) [0|255] "" FUSION
 SG_ ZONE_FR_HW_Ver2 : 135|8@0+ (1,0) [0|255] "" FUSION
 SG_ ZONE_FR_HW_Ver1 : 143|8@0+ (1,0) [0|255] "" FUSION
 SG_ ZONE_FR_SW_dash1 : 151|8@0+ (1,0) [0|255] "" FUSION
 SG_ ZONE_FR_SW_change1 : 159|8@0+ (1,0) [0|255] "" FUSION
 SG_ ZONE_FR_SW_change2 : 167|8@0+ (1,0) [0|255] "" FUSION
 SG_ ZONE_FR_SW_dash2 : 175|8@0+ (1,0) [0|255] "" FUSION
 SG_ ZONE_FR_SW_SHA1 : 183|8@0+ (1,0) [0|255] "" FUSION
 SG_ ZONE_FR_SW_SHA2 : 191|8@0+ (1,0) [0|255] "" FUSION
 SG_ ZONE_FR_SW_SHA3 : 199|8@0+ (1,0) [0|255] "" FUSION
 SG_ ZONE_FR_SW_SHA4 : 207|8@0+ (1,0) [0|255] "" FUSION
 SG_ ZONE_FR_SW_SHA5 : 215|8@0+ (1,0) [0|255] "" FUSION
 SG_ ZONE_FR_SW_SHA6 : 223|8@0+ (1,0) [0|255] "" FUSION
 SG_ ZONE_FR_SW_SHA7 : 231|8@0+ (1,0) [0|255] "" FUSION
 SG_ ZONE_FR_SW_SHA8 : 239|8@0+ (1,0) [0|255] "" FUSION

BO_ 997 GW_PSEAT3: 8 ZONE_DR
 SG_ PSEAT_SW_Ver : 7|16@0+ (1,0) [0|65535] "" FUSION
 SG_ PSEAT_HW_Ver : 23|16@0+ (1,0) [0|65535] "" FUSION

BO_ 1016 GW_DSEAT3: 8 ZONE_DR
 SG_ DSEAT_SW_Ver : 7|16@0+ (1,0) [0|65535] "" FUSION
 SG_ DSEAT_HW_Ver : 23|16@0+ (1,0) [0|65535] "" FUSION

BO_ 1080 FD_OTA1: 8 FUSION
 SG_ OTA_Progress_Rate : 7|8@0+ (1,0) [0|102] "" Vector__XXX
 SG_ OTA_MDA_Status : 15|4@0+ (1,0) [0|14] "" Vector__XXX
 SG_ OTA_Network_Type : 11|2@0+ (1,0) [0|3] "" Vector__XXX
 SG_ OTA_Mode : 9|1@0+ (1,0) [0|1] "" ZONE_FR,ZONE_DR,DKC
 SG_ OTA_DL_Available : 8|1@0+ (1,0) [0|1] "" Vector__XXX
 SG_ OTA_InVehicle_FW : 23|2@0+ (1,0) [0|2] "" Vector__XXX
 SG_ OTA_Update_Available : 21|1@0+ (1,0) [0|1] "" Vector__XXX
 SG_ OTA_Updating_ECU : 20|5@0+ (1,0) [0|30] "" Vector__XXX
 SG_ OTA_Lock_Req : 31|1@0+ (1,0) [0|1] "" DKC
 SG_ OTA_DL_Speed : 27|20@0+ (1,0) [0|1048575] "Kb/s" Vector__XXX
 SG_ OTA_Up_Backcount : 55|8@0+ (1,0) [0|122] "" Vector__XXX
 SG_ OTA_TBOXResetReq : 30|1@0+ (1,0) [0|1] "" ZONE_DR

BO_ 1090 GW_TBOX1: 12 FUSION
 SG_ Re_DoorLock : 7|16@0+ (1,0) [0|65535] "" Vector__XXX
 SG_ Antitheft_Zero : 23|4@0+ (1,0) [0|15] "" Vector__XXX
 SG_ TBOX_Re_VehData : 19|2@0+ (1,0) [0|3] "" Vector__XXX
 SG_ TBOX_RemoteOn : 17|2@0+ (1,0) [0|3] "" Vector__XXX
 SG_ Re_PwrReqTbox : 31|3@0+ (1,0) [0|6] "" Vector__XXX
 SG_ TBOX_Remote_PW : 28|5@0+ (1,0) [0|16] "" ZONE_FR,ZONE_DR
 SG_ Uncounting_Req : 39|2@0+ (1,0) [0|3] "" Vector__XXX
 SG_ CbnPreTarT : 37|6@0+ (0.5,17) [17|32] "" Vector__XXX
 SG_ CbnPreACEnaReq : 47|2@0+ (1,0) [0|3] "" Vector__XXX
 SG_ CbnPreReq : 45|2@0+ (1,0) [0|3] "" Vector__XXX
 SG_ ReOutsideMirror : 43|2@0+ (1,0) [0|3] "" Vector__XXX
 SG_ TBOX_Re_DTCData : 41|2@0+ (1,0) [0|3] "" Vector__XXX
 SG_ TBOX_NET_SIG_STR : 55|4@0+ (1,0) [0|8] "" Vector__XXX
 SG_ TBOX_TEST_STATUS : 51|4@0+ (1,0) [0|15] "" Vector__XXX
 SG_ Re_Radio : 60|1@0+ (1,0) [0|1] "" Vector__XXX
 SG_ PowerOff_T_Set : 70|7@0+ (1,1) [1|100] "" Vector__XXX
 SG_ Remote_ACTemp : 77|6@0+ (0.5,17) [17|32] "Deg^C" Vector__XXX
 SG_ Remote_AutoReq : 79|1@0+ (1,0) [0|1] "" Vector__XXX
 SG_ Remote_MidAutoReq : 78|1@0+ (1,0) [0|1] "" Vector__XXX

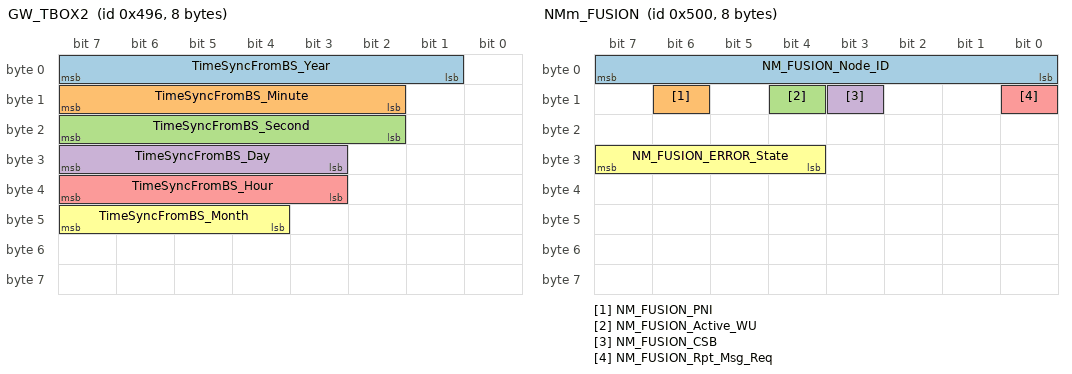
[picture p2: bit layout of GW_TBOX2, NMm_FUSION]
BO_ 1174 GW_TBOX2: 8 FUSION
 SG_ TimeSyncFromBS_Year : 7|7@0+ (1,2000) [2000|2099] "YEAR" ZONE_FR,ZONE_DR
 SG_ TimeSyncFromBS_Minute : 15|6@0+ (1,0) [0|59] "MINUTE" ZONE_FR,ZONE_DR
 SG_ TimeSyncFromBS_Second : 23|6@0+ (1,0) [0|59] "SECOND" ZONE_FR,ZONE_DR
 SG_ TimeSyncFromBS_Day : 31|5@0+ (1,0) [0|31] "DAY" ZONE_FR,ZONE_DR
 SG_ TimeSyncFromBS_Hour : 39|5@0+ (1,0) [0|23] "HOUR" ZONE_FR,ZONE_DR
 SG_ TimeSyncFromBS_Month : 47|4@0+ (1,0) [0|12] "MONTH" ZONE_FR,ZONE_DR

BO_ 1280 NMm_FUSION: 8 FUSION
 SG_ NM_FUSION_Node_ID : 7|8@0+ (1,0) [0|127] "" ZONE_FR,ZONE_DR,DKC
 SG_ NM_FUSION_PNI : 14|1@0+ (1,0) [0|1] "" ZONE_FR,ZONE_DR,DKC
 SG_ NM_FUSION_Active_WU : 12|1@0+ (1,0) [0|1] "" ZONE_FR,ZONE_DR,DKC
 SG_ NM_FUSION_CSB : 11|1@0+ (1,0) [0|1] "" ZONE_FR,ZONE_DR,DKC
 SG_ NM_FUSION_Rpt_Msg_Req : 8|1@0+ (1,0) [0|1] "" ZONE_FR,ZONE_DR,DKC
 SG_ NM_FUSION_ERROR_State : 31|4@0+ (1,0) [0|8] "" ZONE_FR,ZONE_DR,DKC

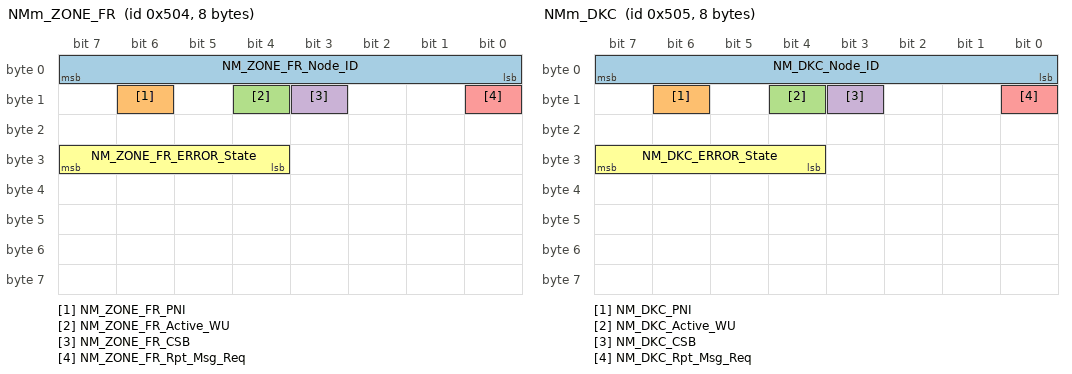
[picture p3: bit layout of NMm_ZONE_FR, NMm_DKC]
BO_ 1284 NMm_ZONE_FR: 8 ZONE_FR
 SG_ NM_ZONE_FR_Node_ID : 7|8@0+ (1,0) [0|127] "" FUSION
 SG_ NM_ZONE_FR_PNI : 14|1@0+ (1,0) [0|1] "" FUSION
 SG_ NM_ZONE_FR_Active_WU : 12|1@0+ (1,0) [0|1] "" FUSION
 SG_ NM_ZONE_FR_CSB : 11|1@0+ (1,0) [0|1] "" FUSION
 SG_ NM_ZONE_FR_Rpt_Msg_Req : 8|1@0+ (1,0) [0|1] "" FUSION
 SG_ NM_ZONE_FR_ERROR_State : 31|4@0+ (1,0) [0|8] "" FUSION

BO_ 1285 NMm_DKC: 8 DKC
 SG_ NM_DKC_Node_ID : 7|8@0+ (1,0) [0|127] "" FUSION
 SG_ NM_DKC_PNI : 14|1@0+ (1,0) [0|1] "" FUSION
 SG_ NM_DKC_Active_WU : 12|1@0+ (1,0) [0|1] "" FUSION
 SG_ NM_DKC_CSB : 11|1@0+ (1,0) [0|1] "" FUSION
 SG_ NM_DKC_Rpt_Msg_Req : 8|1@0+ (1,0) [0|1] "" FUSION
 SG_ NM_DKC_ERROR_State : 31|4@0+ (1,0) [0|8] "" FUSION

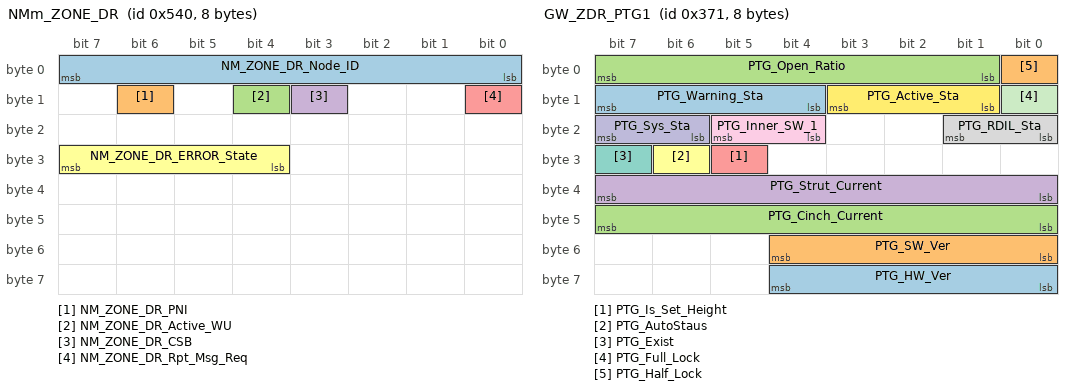
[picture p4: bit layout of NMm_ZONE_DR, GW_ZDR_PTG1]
BO_ 1344 NMm_ZONE_DR: 8 ZONE_DR
 SG_ NM_ZONE_DR_Node_ID : 7|8@0+ (1,0) [0|127] "" FUSION
 SG_ NM_ZONE_DR_PNI : 14|1@0+ (1,0) [0|1] "" FUSION
 SG_ NM_ZONE_DR_Active_WU : 12|1@0+ (1,0) [0|1] "" FUSION
 SG_ NM_ZONE_DR_CSB : 11|1@0+ (1,0) [0|1] "" FUSION
 SG_ NM_ZONE_DR_Rpt_Msg_Req : 8|1@0+ (1,0) [0|1] "" FUSION
 SG_ NM_ZONE_DR_ERROR_State : 31|4@0+ (1,0) [0|8] "" FUSION

BO_ 1540 DiagRespFromZONE_FR: 64 ZONE_FR
 SG_ DiagRespFromZONE_FR : 455|64@0+ (1,0) [0|0] "" FUSION

BO_ 1541 DiagRespFromDKC: 8 DKC
 SG_ DiagRespFromDKC : 7|64@0+ (1,0) [0|0] "" FUSION

BO_ 1556 DiagRespFromDSEAT: 8 ZONE_DR
 SG_ DiagRespFromDSEAT : 7|64@0+ (1,0) [0|0] "" FUSION

BO_ 1572 DiagRespFromPSEAT: 8 ZONE_DR
 SG_ DiagRespFromPSEAT : 7|64@0+ (1,0) [0|0] "" FUSION

BO_ 1588 DiagRespFromPTG: 8 ZONE_DR
 SG_ DiagRespFromPTG : 7|64@0+ (1,0) [0|0] "" FUSION

BO_ 1600 DiagRespFromZONE_DR: 64 ZONE_DR
 SG_ DiagRespFromZONE_DR : 455|64@0+ (1,0) [0|0] "" FUSION

BO_ 1668 DiagPhysReqToZONE_FR: 64 FUSION
 SG_ DiagPhysReqToZONE_FR : 455|64@0+ (1,0) [0|0] "" ZONE_FR

BO_ 1669 DiagPhysReqToDKC: 8 FUSION
 SG_ DiagPhysReqToDKC : 7|64@0+ (1,0) [0|0] "" DKC

BO_ 1684 DiagPhysReqToDSEAT: 8 FUSION
 SG_ DiagPhysReqToDSEAT : 7|64@0+ (1,0) [0|0] "" ZONE_DR

BO_ 1700 DiagPhysReqToPSEAT: 8 FUSION
 SG_ DiagPhysReqToPSEAT : 7|64@0+ (1,0) [0|0] "" ZONE_DR

BO_ 1716 DiagPhysReqToPTG: 8 FUSION
 SG_ DiagPhysReqToPTG : 7|64@0+ (1,0) [0|0] "" ZONE_DR

BO_ 1728 DiagPhysReqToZONE_DR: 64 FUSION
 SG_ DiagPhysReqToZONE_DR : 455|64@0+ (1,0) [0|0] "" ZONE_DR

BO_ 2000 DiagFuncReqFT: 8 FUSION
 SG_ DiagFuncReqFT : 7|64@0+ (1,0) [0|0] "" ZONE_FR,ZONE_DR,DKC

BO_ 1573 DiagRespFromAirPTC: 8 ZONE_DR
 SG_ DiagRespFromAirPTC : 7|64@0+ (1,0) [0|0] "" FUSION

BO_ 1701 DiagPhysReqToAirPTC: 8 FUSION
 SG_ DiagPhysReqToAirPTC : 7|64@0+ (1,0) [0|0] "" ZONE_DR

BO_ 1733 DiagPhysReqToCompressor: 8 FUSION
 SG_ DiagPhysReqToCompressor : 7|64@0+ (1,0) [0|0] "" ZONE_FR

BO_ 1605 DiagRespFromCompressor: 8 ZONE_FR
 SG_ DiagRespFromCompressor : 7|64@0+ (1,0) [0|0] "" FUSION

BO_ 881 GW_ZDR_PTG1: 8 ZONE_DR
 SG_ PTG_HW_Ver : 60|5@0+ (1,0) [0|31] "" FUSION
 SG_ PTG_SW_Ver : 52|5@0+ (1,0) [0|31] "" FUSION
 SG_ PTG_Cinch_Current : 47|8@0+ (0.1,0) [0|25.5] "A" FUSION
 SG_ PTG_Strut_Current : 39|8@0+ (0.1,0) [0|25.5] "A" FUSION
 SG_ PTG_Is_Set_Height : 29|1@0+ (1,0) [0|1] "" FUSION
 SG_ PTG_AutoStaus : 30|1@0+ (1,0) [0|1] "" FUSION
 SG_ PTG_Exist : 31|1@0+ (1,0) [0|1] "" FUSION
 SG_ PTG_RDIL_Sta : 17|2@0+ (1,0) [0|3] "" FUSION
 SG_ PTG_Inner_SW_1 : 21|2@0+ (1,0) [0|3] "" FUSION
 SG_ PTG_Sys_Sta : 23|2@0+ (1,0) [0|3] "" FUSION
 SG_ PTG_Full_Lock : 8|1@0+ (1,0) [0|1] "" FUSION
 SG_ PTG_Active_Sta : 11|3@0+ (1,0) [0|7] "" FUSION
 SG_ PTG_Warning_Sta : 15|4@0+ (1,0) [0|15] "" FUSION
 SG_ PTG_Half_Lock : 0|1@0+ (1,0) [0|1] "" FUSION
 SG_ PTG_Open_Ratio : 7|7@0+ (1,0) [0|127] "" FUSION

BO_ 928 FD4_CE100_2: 32 FUSION
 SG_ FDC_VCU_ReqHWReset_Cmd : 20|5@0+ (1,0) [0|31] "" ZONE_FR,ZONE_DR
 SG_ FD4_CE100_2_CS : 7|8@0+ (1,0) [0|255] "" ZONE_FR,ZONE_DR
 SG_ FD4_CE100_2_RC : 11|4@0+ (1,0) [0|14] "" ZONE_FR,ZONE_DR

CM_ SG_ 602 METER_KPH_Calcu "METER Calculated Speed(KPH)";
CM_ SG_ 602 METER_MPH_Calcu "METER Calculated Speed(MPH)";
CM_ SG_ 602 METER_KPH_Real "METER Real Speed(KPH)";
CM_ SG_ 602 METER_MPH_Real "METER Real Speed(MPH)";
CM_ SG_ 602 Averaged_vehspeed "Averaged_vehspeed";
CM_ SG_ 602 AVGPwrConsumption "average power consumption";
CM_ SG_ 602 AvailableTrip "Distance to Empty";
CM_ SG_ 602 Spd_Crl_Mode "Speed Control Function Mode";
CM_ SG_ 602 Spd_Crl_Sta "Speed Control Function Status";
CM_ SG_ 602 LEDlitWarnReq "LED lit Warning Request";
CM_ SG_ 602 Charge "Charge";
CM_ SG_ 602 ParkBrake "Park Brake";
CM_ SG_ 602 Trip_B "TripB";
CM_ SG_ 602 Trip_A "TripA";
CM_ SG_ 602 ODOMETER "Odometer";
CM_ SG_ 659 Zone_Spd_Ctrl_Mode "Speed Control Function Mode";
CM_ SG_ 659 Zone_Spd_Ctrl_Sta "Speed Control Function Status";
CM_ SG_ 659 RegenMode "Regen Mode";
CM_ SG_ 659 DrSCPSysErrLmp "SCP system error lamp  request ";
CM_ SG_ 659 Set_Spd "speed setting under speed control function";
CM_ SG_ 778 CCM_SpdCmd "Target Speed of Compressor";
CM_ SG_ 778 EAC_Temp "Compressor Controller Temperature";
CM_ SG_ 778 EAC_DrvVoltFalt "15V Drive Voltage Failure";
CM_ SG_ 778 EAC_MotorLackFalt "Compressor Phase Loss Fault";
CM_ SG_ 778 EAC_OvLoadFalt "Compressor Overload Fault";
CM_ SG_ 778 EAC_TempSnsrFalt "Controller Temperature Sensor Failure";
CM_ SG_ 778 CompProEN "Compressor protect enable";
CM_ SG_ 778 COMP_ComLost "Lost Communication on Compressor";
CM_ SG_ 778 COMP_IPM_HWFLt "Fault Detection on Compressor of IPM Hardware";
CM_ SG_ 778 COMP_IPM_TempOverFlt "Fault Detection on Compressor of IPM Temperature Too High";
CM_ SG_ 778 COMP_CurOverProtect "Fault Detection on Compressor OverCurrent Protection";
CM_ SG_ 778 COMP_VoltOverErr "OverVoltage Fault Detection on  High-Voltage DC bus";
CM_ SG_ 778 COMP_VoltLessErr "LessVoltage Fault Detection on  High-Voltage DC bus";
CM_ SG_ 778 COMP_CtrlCircFlt "Compressor Controller Fault Detection status";
CM_ SG_ 778 COMP_Sta "Current State of Compressor";
CM_ SG_ 778 COMP_Init "Compressor Initialization Status";
CM_ SG_ 778 COMP_SpdVaild "Validity of Reported Speed of Compressor";
CM_ SG_ 778 EAC_MotCrt "Phase Current Value";
CM_ SG_ 778 COMP_CurVaild "Validity of Compressor Reporting HVDC Bus Current";
CM_ SG_ 778 COMP_VoltVaild "Validity of Compressor Reporting HVDC Bus Voltage";
CM_ SG_ 778 COMP_StatorSpd "Compressor Report Speed";
CM_ SG_ 778 COMP_ConCur "Compressor Reports HVDC Bus Current";
CM_ SG_ 778 COMP_ConVolt "Compressor Reports HVDC Bus Voltage";
CM_ SG_ 778 PTCStsHSC6 "Positive Temperature Coefficient Status";
CM_ SG_ 778 PTCFltLvlHSC6 "Positive Temperature Coefficient Fault level";
CM_ SG_ 796 COMP_ActualPwr "COMP actual power";
CM_ SG_ 826 SWC_CANCEL_Sta "CANCEL Button Status";
CM_ SG_ 826 SWC_ACC_Sta "ACC Button Status";
CM_ SG_ 826 SWC_Distance_Sta "Distance Button Status";
CM_ SG_ 826 SWC_Down_Sta "DOWN Button Status";
CM_ SG_ 826 SWC_RegenUp "Regen Up";
CM_ SG_ 826 SWC_Left_Sta "Seek Backward track/radio";
CM_ SG_ 826 SWC_mode_Sta "Mode Button Status";
CM_ SG_ 826 SWC_Res_Up_Sta "Res up Button Status";
CM_ SG_ 826 SWC_RegenDown "Regen Down";
CM_ SG_ 826 SWC_Right_Sta "Seek Forward track/radio";
CM_ SG_ 826 SWC_Set_down_Sta "SET down Button Status";
CM_ SG_ 826 SWC_Trip_Sta "Trip Button Status";
CM_ SG_ 826 SWC_Up_Sta "UP Button Status";
CM_ SG_ 826 SWC_VR_Sta "VR Button Status";
CM_ SG_ 826 SWC_Undefined_Sta "Undefined button Status";
CM_ SG_ 826 SWC_LKA_Sta "LKA Button Status";
CM_ SG_ 851 L_RRD_Wdw_Obs_InhibitSts "Obstacle inhibit status";
CM_ SG_ 851 L_RRD_Wdw_OD_Sts "Obstacle detection status";
CM_ SG_ 851 L_RRD_Wdw_Init "ECU Initialization";
CM_ SG_ 851 L_RRD_OverHeat_Protect "OverHeat Protect";
CM_ SG_ 851 L_RRD_Motor_Relay_Error "Motor relay Error";
CM_ SG_ 851 L_RRD_Motor_Ripple_Error "Motor ripple Error";
CM_ SG_ 851 L_RRD_Val_Wdw_Opened "Window Opened Value";
CM_ SG_ 851 L_RRD_Wdw_PositionSts "Position status of Rear Right window";
CM_ SG_ 851 L_RRD_Wdw_LocalSwitch "Local switch status of Rear Right window";
CM_ SG_ 851 L_RRD_Wdw_Running_Sts "Running status of Rear Right window";
CM_ SG_ 851 RAPWL_01_LIN_Response_Error "LIN Communication ERROR";
CM_ SG_ 851 L_RLD_Wdw_Obs_InhibitSts "Obstacle inhibit status";
CM_ SG_ 851 L_RLD_Wdw_OD_Sts "Obstacle detection status";
CM_ SG_ 851 L_RLD_Wdw_Init "ECU Initialization";
CM_ SG_ 851 L_RLD_OverHeat_Protect "OverHeat Protect";
CM_ SG_ 851 L_RLD_Motor_Relay_Error "Motor relay Error";
CM_ SG_ 851 L_RLD_Motor_Ripple_Error "Motor ripple Error";
CM_ SG_ 851 L_RLD_Val_Wdw_Opened "Window Opened Value";
CM_ SG_ 851 L_RLD_Wdw_PositionSts "Position status of Rear Left window";
CM_ SG_ 851 L_RLD_Wdw_LocalSwitch "Local switch status of Rear Left window";
CM_ SG_ 851 L_RLD_Wdw_Running_Sts "Running status of Rear Left window";
CM_ SG_ 851 PTG_Inner_SW_2 "Power Tail Gate Inner SW#2 State";
CM_ SG_ 854 L_APM_IntellectClose "Rainfall intelligent window raising";
CM_ SG_ 854 L_Drv_Wdw_RRD_Switch "Passager switch status of Rear Right window";
CM_ SG_ 854 L_Drv_Wdw_RLD_Switch "Passager switch status of Rear Left window";
CM_ SG_ 854 L_Drv_Wdw_Pas_Switch "Passager switch status of driver window";
CM_ SG_ 854 L_Pas_Wdw_Obs_InhibitSts "Obstacle inhibit status";
CM_ SG_ 854 L_Pas_Wdw_OD_Sts "Obstacle detection status";
CM_ SG_ 854 L_Pas_Wdw_Init "ECU Initialization";
CM_ SG_ 854 L_Pas_OverHeat_Protect "OverHeat Protect";
CM_ SG_ 854 L_Pas_Motor_Relay_Error "Motor relay Error";
CM_ SG_ 854 L_Pas_Motor_Ripple_Error "Motor ripple Error";
CM_ SG_ 854 L_Pas_Val_Wdw_Opened "Window Opened Value";
CM_ SG_ 854 L_Pas_Wdw_PositionSts "Position status of passager window";
CM_ SG_ 854 L_Pas_Wdw_LocalSwitch "Local switch status of passager window";
CM_ SG_ 854 L_Pas_Wdw_Running_Sts "Running status of passager window";
CM_ SG_ 854 L_Power_Status "Power_Status";
CM_ SG_ 854 FAPWL_01_LIN_Response_Error "LIN Communication ERROR";
CM_ SG_ 854 L_Drv_Wdw_Obs_InhibitSts "Obstacle inhibit status";
CM_ SG_ 854 L_Drv_Wdw_OD_Sts "Obstacle detection status";
CM_ SG_ 854 L_Drv_Wdw_Init "ECU Initialization";
CM_ SG_ 854 L_Drv_OverHeat_Protect "OverHeat Protect";
CM_ SG_ 854 L_Drv_Motor_Relay_Error "Motor relay Error";
CM_ SG_ 854 L_Drv_Motor_Ripple_Error "Motor ripple Error";
CM_ SG_ 854 L_Drv_Val_Wdw_Opened "Window Opened Value";
CM_ SG_ 854 L_Drv_Wdw_PositionSts "Position status of driver window";
CM_ SG_ 854 L_Drv_Wdw_LocalSwitch "Local switch status of driver window";
CM_ SG_ 854 L_Drv_Wdw_Running_Sts "Running status of driver window";
CM_ SG_ 856 DSEAT_FL_Pos "Driver Seat Front Lifter Position
Min=0, Max=25, Engineering Unit=mm,  Offset=0 mm, Resolution=1 mm per bit, Invaild=255, Undefined=26 - 254";
CM_ SG_ 856 DSEAT_Slid_Pos "Driver Seat Slider Position
Min=0, Max=240, Engineering Unit=mm, Offset=0 mm, Resolution=1 mm per bit, Invaild=255, Undefined=241 - 254";
CM_ SG_ 856 DSEAT_RL_Pos "Driver Seat Rear Lifter Position
Min=0, 
Max=60, Engineering Unit=mm, Offset=0 mm, Resolution=1 mm per bit, Invaild=255, Undefined=61 - 254";
CM_ SG_ 856 DSEAT_Rec_Pos "Driver Seat Recliner Position
Min=0, 
Max=80, Engineering Unit=deg, Offset=0 deg, Resolution=1 deg per bit, Invaild=255, Undefined=81 - 254";
CM_ SG_ 856 DSEAT_Mode "Driver Seat Mode
0=manual, 1=power, 2=power & heater, 
3=power & ventilate, 
4=power & heater & ventilate, 
5=manual & heater, 
6=manual & ventilate, 
7=manual & heater & ventilate";
CM_ SG_ 856 DSEAT_Vent_Sta "Driver Seat Ventilate Staus";
CM_ SG_ 856 DSEAT_AntiAct_Sta "Driver Seat Antitheft Activate Status";
CM_ SG_ 856 DSEAT_Anti_Sta "Driver Seat Antitheft Status";
CM_ SG_ 856 DSEAT_EntryAct_Sta "Driver Seat Entry Function Activate Status";
CM_ SG_ 856 DSEAT_EntryFun_Sta "Driver Seat Entry Function Status";
CM_ SG_ 856 DSEAT_Error_Sta "Driver Seat Error Status";
CM_ SG_ 917 PSEAT_Vent_Sta "Passenger Seat Ventilate Staus";
CM_ SG_ 917 PSEAT_Mode "Passenger Seat Mode";
CM_ SG_ 917 PSEAT_Error_Sta "Passenger Seat Error Status";
CM_ SG_ 965 ZONE_DR_SW_Var "software version car model variation";
CM_ SG_ 965 ZONE_DR_SW_Country2 "software version country of target market character 2";
CM_ SG_ 965 ZONE_DR_SW_Country1 "software version country of target market character 1";
CM_ SG_ 965 ZONE_DR_SW_Patch2 "software version patch character 2";
CM_ SG_ 965 ZONE_DR_SW_Patch1 "software version patch character 1";
CM_ SG_ 965 ZONE_DR_SW_Minor2 "software version minor character 2";
CM_ SG_ 965 ZONE_DR_SW_Minor1 "software version minor character 1";
CM_ SG_ 965 ZONE_DR_SW_Major2 "software version major character 2";
CM_ SG_ 965 ZONE_DR_SW_Major1 "software version major character 1";
CM_ SG_ 965 ZONE_DR_SW_Controller2 "software version controller character 2";
CM_ SG_ 965 ZONE_DR_SW_Controller1 "software version controller character 1";
CM_ SG_ 965 ZONE_DR_SW_CarModel3 "software version car model character 3";
CM_ SG_ 965 ZONE_DR_SW_CarModel2 "software version car model character 2";
CM_ SG_ 965 ZONE_DR_SW_CarModel1 "software version car model character 1";
CM_ SG_ 965 ZONE_DR_HW_Ver3 "ZONE_DR hardware version character 3";
CM_ SG_ 965 ZONE_DR_HW_Ver2 "ZONE_DR hardware version character 2";
CM_ SG_ 965 ZONE_DR_HW_Ver1 "ZONE_DR hardware version character 1";
CM_ SG_ 965 ZONE_DR_SW_dash1 "software version dash character 1";
CM_ SG_ 965 ZONE_DR_SW_change1 "software version number of change 1";
CM_ SG_ 965 ZONE_DR_SW_change2 "software version number of change 2";
CM_ SG_ 965 ZONE_DR_SW_dash2 "software version dash character 2";
CM_ SG_ 965 ZONE_DR_SW_SHA1 "software version SHA character 1";
CM_ SG_ 965 ZONE_DR_SW_SHA2 "software version SHA character 2";
CM_ SG_ 965 ZONE_DR_SW_SHA3 "software version SHA character 3";
CM_ SG_ 965 ZONE_DR_SW_SHA4 "software version SHA character 4";
CM_ SG_ 965 ZONE_DR_SW_SHA5 "software version SHA character 5";
CM_ SG_ 965 ZONE_DR_SW_SHA6 "software version SHA character 6";
CM_ SG_ 965 ZONE_DR_SW_SHA7 "software version SHA character 7";
CM_ SG_ 965 ZONE_DR_SW_SHA8 "software version SHA character 8";
CM_ SG_ 969 ZONE_FR_SW_Var "software version car model variation";
CM_ SG_ 969 ZONE_FR_SW_Country2 "software version country of target market character 2";
CM_ SG_ 969 ZONE_FR_SW_Country1 "software version country of target market character 1";
CM_ SG_ 969 ZONE_FR_SW_Patch2 "software version patch character 2";
CM_ SG_ 969 ZONE_FR_SW_Patch1 "software version patch character 1";
CM_ SG_ 969 ZONE_FR_SW_Minor2 "software version minor character 2";
CM_ SG_ 969 ZONE_FR_SW_Minor1 "software version minor character 1";
CM_ SG_ 969 ZONE_FR_SW_Major2 "software version major character 2";
CM_ SG_ 969 ZONE_FR_SW_Major1 "software version major character 1";
CM_ SG_ 969 ZONE_FR_SW_Controller2 "software version controller character 2";
CM_ SG_ 969 ZONE_FR_SW_Controller1 "software version controller character 1";
CM_ SG_ 969 ZONE_FR_SW_CarModel3 "software version car model character 3";
CM_ SG_ 969 ZONE_FR_SW_CarModel2 "software version car model character 2";
CM_ SG_ 969 ZONE_FR_SW_CarModel1 "software version car model character 1";
CM_ SG_ 969 ZONE_FR_HW_Ver3 "ZONE_FR hardware version character 3";
CM_ SG_ 969 ZONE_FR_HW_Ver2 "ZONE_FR hardware version character 2";
CM_ SG_ 969 ZONE_FR_HW_Ver1 "ZONE_FR hardware version character 1";
CM_ SG_ 969 ZONE_FR_SW_dash1 "software version dash character 1";
CM_ SG_ 969 ZONE_FR_SW_change1 "software version number of change 1";
CM_ SG_ 969 ZONE_FR_SW_change2 "software version number of change 2";
CM_ SG_ 969 ZONE_FR_SW_dash2 "software version dash character 2";
CM_ SG_ 969 ZONE_FR_SW_SHA1 "software version SHA character 1";
CM_ SG_ 969 ZONE_FR_SW_SHA2 "software version SHA character 2";
CM_ SG_ 969 ZONE_FR_SW_SHA3 "software version SHA character 3";
CM_ SG_ 969 ZONE_FR_SW_SHA4 "software version SHA character 4";
CM_ SG_ 969 ZONE_FR_SW_SHA5 "software version SHA character 5";
CM_ SG_ 969 ZONE_FR_SW_SHA6 "software version SHA character 6";
CM_ SG_ 969 ZONE_FR_SW_SHA7 "software version SHA character 7";
CM_ SG_ 969 ZONE_FR_SW_SHA8 "software version SHA character 8";
CM_ SG_ 997 PSEAT_SW_Ver "Passenger Seat Software Version Number";
CM_ SG_ 997 PSEAT_HW_Ver "Passenger Seat Hardware Version Number";
CM_ SG_ 1016 DSEAT_SW_Ver "Driver Seat Software Version Number";
CM_ SG_ 1016 DSEAT_HW_Ver "Driver Seat Hardware Version Number";
CM_ SG_ 1080 OTA_Progress_Rate "MDA download or update progress rate";
CM_ SG_ 1080 OTA_MDA_Status "Fusion Master OTA agent status";
CM_ SG_ 1080 OTA_Network_Type "Vehicle Network Type";
CM_ SG_ 1080 OTA_Mode "Vehicel OTA mode Status";
CM_ SG_ 1080 OTA_DL_Available "Fusion MDA available for download";
CM_ SG_ 1080 OTA_InVehicle_FW "In Vehicle Firmware Version Status";
CM_ SG_ 1080 OTA_Update_Available "Fusion MDA available for update";
CM_ SG_ 1080 OTA_Updating_ECU "Fusion MDA is updating ECU";
CM_ SG_ 1080 OTA_Lock_Req "OTA Lock request to DKC";
CM_ SG_ 1080 OTA_DL_Speed "Firmware Package download speed";
CM_ SG_ 1080 OTA_Up_Backcount "Start Update Backcount";
CM_ SG_ 1080 OTA_TBOXResetReq "TBOX Reset Request";
CM_ SG_ 1090 Re_DoorLock "TBOX Remote DoorLock Control.";
CM_ SG_ 1090 Antitheft_Zero "AntitheftBehaviour Zero";
CM_ SG_ 1090 TBOX_Re_VehData "remote vehicle data";
CM_ SG_ 1090 TBOX_RemoteOn "Remote command processing to restrict function operation";
CM_ SG_ 1090 Re_PwrReqTbox "Remote Vehicle Power Status";
CM_ SG_ 1090 TBOX_Remote_PW "TBOX_Remote_PW";
CM_ SG_ 1090 Uncounting_Req "TBOX Uncounting Request";
CM_ SG_ 1090 CbnPreTarT "Cabin Preconditioning Target Temperature";
CM_ SG_ 1090 CbnPreACEnaReq "Cabin Preconditioning Air condition open enable";
CM_ SG_ 1090 CbnPreReq "Cabin Preconditioning Request";
CM_ SG_ 1090 ReOutsideMirror "Remote outside mirror control";
CM_ SG_ 1090 TBOX_Re_DTCData "Request vehicle data";
CM_ SG_ 1090 TBOX_NET_SIG_STR "TBOX Network Signal Strength";
CM_ SG_ 1090 TBOX_TEST_STATUS "TBOX Self Test Status";
CM_ SG_ 1090 Re_Radio "Remote Radio on/off";
CM_ SG_ 1090 PowerOff_T_Set "Auto Power off time setting";
CM_ SG_ 1090 Remote_ACTemp "TBOX Remote_ACTemp";
CM_ SG_ 1090 Remote_AutoReq "TBOX Remote_AutoReq ON_OFF";
CM_ SG_ 1090 Remote_MidAutoReq "TBOX Remote_MidAutoReq ON_OFF";
CM_ SG_ 1174 TimeSyncFromBS_Year "Time Sync. From Base Station of Year";
CM_ SG_ 1174 TimeSyncFromBS_Minute "Time Sync. From Base Station of Minute";
CM_ SG_ 1174 TimeSyncFromBS_Second "Time Sync. From Base Station of Second";
CM_ SG_ 1174 TimeSyncFromBS_Day "Time Sync. from Base Station - DAY";
CM_ SG_ 1174 TimeSyncFromBS_Hour "Time Sync. From Base Station of Hour";
CM_ SG_ 1174 TimeSyncFromBS_Month "Time Sync. From Base Station of  Month";
CM_ SG_ 1280 NM_FUSION_Node_ID "Source Node Identifier";
CM_ SG_ 1280 NM_FUSION_PNI "Partial Network Information Bit (PNI)";
CM_ SG_ 1280 NM_FUSION_Active_WU "Active Wakeup Bit";
CM_ SG_ 1280 NM_FUSION_CSB "NM Coordinator Sleep Bit";
CM_ SG_ 1280 NM_FUSION_Rpt_Msg_Req "Repeat Message Request";
CM_ SG_ 1280 NM_FUSION_ERROR_State "Defined Error states of the CAN Controller";
CM_ SG_ 1284 NM_ZONE_FR_Node_ID "Source Node Identifier";
CM_ SG_ 1284 NM_ZONE_FR_PNI "Partial Network Information Bit (PNI)";
CM_ SG_ 1284 NM_ZONE_FR_Active_WU "Active Wakeup Bit";
CM_ SG_ 1284 NM_ZONE_FR_CSB "NM Coordinator Sleep Bit";
CM_ SG_ 1284 NM_ZONE_FR_Rpt_Msg_Req "Repeat Message Request";
CM_ SG_ 1284 NM_ZONE_FR_ERROR_State "Defined Error states of the CAN Controller";
CM_ SG_ 1285 NM_DKC_Node_ID "Source Node Identifier";
CM_ SG_ 1285 NM_DKC_PNI "Partial Network Information Bit (PNI)";
CM_ SG_ 1285 NM_DKC_Active_WU "Active Wakeup Bit";
CM_ SG_ 1285 NM_DKC_CSB "NM Coordinator Sleep Bit";
CM_ SG_ 1285 NM_DKC_Rpt_Msg_Req "Repeat Message Request";
CM_ SG_ 1285 NM_DKC_ERROR_State "Defined Error states of the CAN Controller";
CM_ SG_ 1344 NM_ZONE_DR_Node_ID "Source Node Identifier";
CM_ SG_ 1344 NM_ZONE_DR_PNI "Partial Network Information Bit (PNI)";
CM_ SG_ 1344 NM_ZONE_DR_Active_WU "Active Wakeup Bit";
CM_ SG_ 1344 NM_ZONE_DR_CSB "NM Coordinator Sleep Bit";
CM_ SG_ 1344 NM_ZONE_DR_Rpt_Msg_Req "Repeat Message Request";
CM_ SG_ 1344 NM_ZONE_DR_ERROR_State "Defined Error states of the CAN Controller";
CM_ SG_ 1540 DiagRespFromZONE_FR "Diagnostic Response from ZONE_FR";
CM_ SG_ 1541 DiagRespFromDKC "Diagnostic Response from DKC";
CM_ SG_ 1556 DiagRespFromDSEAT "Diagnostic Response from DSEAT";
CM_ SG_ 1572 DiagRespFromPSEAT "Diagnostic Response from PSEAT";
CM_ SG_ 1588 DiagRespFromPTG "Diagnostic Response from PTG";
CM_ SG_ 1600 DiagRespFromZONE_DR "Diagnostic Response from ZONE_DR";
CM_ SG_ 1668 DiagPhysReqToZONE_FR "Diagnostic Physical Request to ZONE_FR";
CM_ SG_ 1669 DiagPhysReqToDKC "Diagnostic Physical Request to DKC";
CM_ SG_ 1684 DiagPhysReqToDSEAT "Diagnostic Physical Request to DSEAT";
CM_ SG_ 1700 DiagPhysReqToPSEAT "Diagnostic Physical Request to PSEAT";
CM_ SG_ 1716 DiagPhysReqToPTG "Diagnostic Physical Request to PTG";
CM_ SG_ 1728 DiagPhysReqToZONE_DR "Diagnostic Physical Request to ZONE_DR";
CM_ SG_ 2000 DiagFuncReqFT "Diagnostic Functional Request from Tester";
CM_ SG_ 1573 DiagRespFromAirPTC "Diagnostic Response from AirPTC";
CM_ SG_ 1701 DiagPhysReqToAirPTC "Diagnostic Physical Request to AirPTC";
CM_ SG_ 1733 DiagPhysReqToCompressor "Diagnostic Physical Request to Compressor";
CM_ SG_ 1605 DiagRespFromCompressor "Diagnostic Response from Compressor";
CM_ SG_ 881 PTG_HW_Ver "Power Tail Gate ECU Hardware Version";
CM_ SG_ 881 PTG_SW_Ver "Power Tail Gate ECU Software Version";
CM_ SG_ 881 PTG_Cinch_Current "Power Tail Gate Cinch Motor Current";
CM_ SG_ 881 PTG_Strut_Current "Power Tail Gate Lift Strut Motor Current";
CM_ SG_ 881 PTG_Is_Set_Height "PTG 'Set Open Height' Action Listener";
CM_ SG_ 881 PTG_AutoStaus "Power Tail Gate Auto Status";
CM_ SG_ 881 PTG_Exist "Power Tail Gate Exist";
CM_ SG_ 881 PTG_RDIL_Sta "Power Tail Gate Rear Direction Indicator Lamp State";
CM_ SG_ 881 PTG_Inner_SW_1 "Power Tail Gate Inner SW#1 State";
CM_ SG_ 881 PTG_Sys_Sta "Power Tail Gate System Status";
CM_ SG_ 881 PTG_Full_Lock "Power Tail Gate Latch Full Lock";
CM_ SG_ 881 PTG_Active_Sta "Power Tail Gate Function Activation State";
CM_ SG_ 881 PTG_Warning_Sta "Power Tail Gate Warning";
CM_ SG_ 881 PTG_Half_Lock "Power Tail Gate Latch Half Lock";
CM_ SG_ 881 PTG_Open_Ratio "Power Tail Gate Open Ratio";
CM_ SG_ 928 FDC_VCU_ReqHWReset_Cmd "OTA request hardware reset";
CM_ SG_ 928 FD4_CE100_2_CS "Checksum of FD4_CE100_2 (AUTOSAR E2E profile 1)

Polynomial 0x1D (x^8+x^4+x^3+x^2+1) Both start value and XOR value are 0x00.";
CM_ SG_ 928 FD4_CE100_2_RC "4-bit rolling counter for FD4_CE100_2
It starts counting from 0, ends at 14 and returns to zero (0~14).";
BA_DEF_ BO_ "GenMsgSendType" ENUM "Cycle","NoMsgSendType","IfActive","Event","CA","CE";
BA_DEF_ BO_ "GenMsgNrOfRepetition" INT 0 0;
BA_DEF_ BO_ "GenMsgILSupport" ENUM "No","Yes";
BA_DEF_ BO_ "GenMsgDelayTime" INT 0 0;
BA_DEF_ BO_ "GenMsgCycleTimeFast" INT 0 0;
BA_DEF_ BO_ "GenMsgCycleTime" INT 0 0;
BA_DEF_ BO_ "DiagResponse" ENUM "No","Yes";
BA_DEF_ BO_ "DiagRequest" ENUM "No","Yes";
BA_DEF_ BO_ "NmMessage" ENUM "No","Yes";
BA_DEF_ BO_ "VFrameFormat" ENUM "StandardCAN","ExtendedCAN","reserved","reserved","reserved","reserved","reserved","reserved","reserved","reserved","reserved","reserved","reserved","reserved","StandardCAN_FD","ExtendedCAN_FD";
BA_DEF_ BO_ "GenMsgRequestable" INT 0 1;
BA_DEF_ BO_ "DataID_Hex" HEX 0 65535;
BA_DEF_ BO_ "DoIPLogicalAddress" STRING ;
BA_DEF_ BO_ "DataID" STRING ;
BA_DEF_ BO_ "CANFD_BRS" ENUM "0","1";
BA_DEF_ SG_ "GenSigInvalidValue" HEX 0 0;
BA_DEF_ SG_ "GenSigStartValue" HEX 0 0;
BA_DEF_ SG_ "GenSigInactiveValue" HEX 0 0;
BA_DEF_ SG_ "GenSigRoutingTimeoutValue" HEX 0 0;
BA_DEF_ SG_ "GenSigSendType" ENUM "Cycle","OnWrite","OnWriteWithRepetition","OnChange","OnChangeWithRepetition","IfActive","IfActiveWithRepetition","NoSigSendType","vector_leerstring";
BA_DEF_ SG_ "SigType" ENUM "Default","Range","RangeSigned","ASCII","Discrete","Control","ReferencePGN","DTC","StringDelimiter","StringLength","StringLengthControl","MessageCounter","MessageChecksum";
BA_DEF_ SG_ "GenSigILSupport" ENUM "No","Yes";
BA_DEF_DEF_ "GenMsgSendType" "Cycle";
BA_DEF_DEF_ "GenMsgNrOfRepetition" 0;
BA_DEF_DEF_ "GenMsgILSupport" "Yes";
BA_DEF_DEF_ "GenMsgDelayTime" 0;
BA_DEF_DEF_ "GenMsgCycleTimeFast" 0;
BA_DEF_DEF_ "GenMsgCycleTime" 100;
BA_DEF_DEF_ "DiagResponse" "No";
BA_DEF_DEF_ "DiagRequest" "No";
BA_DEF_DEF_ "NmMessage" "No";
BA_DEF_DEF_ "VFrameFormat" "StandardCAN";
BA_DEF_DEF_ "GenMsgRequestable" 1;
BA_DEF_DEF_ "DataID_Hex" 0;
BA_DEF_DEF_ "DoIPLogicalAddress" "";
BA_DEF_DEF_ "DataID" "";
BA_DEF_DEF_ "CANFD_BRS" "1";
BA_DEF_DEF_ "GenSigInvalidValue" 0;
BA_DEF_DEF_ "GenSigStartValue" 0;
BA_DEF_DEF_ "GenSigInactiveValue" 0;
BA_DEF_DEF_ "GenSigRoutingTimeoutValue" 0;
BA_DEF_DEF_ "GenSigSendType" "Cycle";
BA_DEF_DEF_ "SigType" "Default";
BA_DEF_DEF_ "GenSigILSupport" "Yes";
BA_ "VFrameFormat" BO_ 596 14;
BA_ "GenMsgNrOfRepetition" BO_ 602 1;
BA_ "GenMsgCycleTimeFast" BO_ 602 10;
BA_ "GenMsgSendType" BO_ 602 5;
BA_ "VFrameFormat" BO_ 602 14;
BA_ "GenMsgNrOfRepetition" BO_ 659 1;
BA_ "GenMsgCycleTimeFast" BO_ 659 10;
BA_ "GenMsgSendType" BO_ 659 5;
BA_ "VFrameFormat" BO_ 659 14;
BA_ "VFrameFormat" BO_ 778 14;
BA_ "VFrameFormat" BO_ 796 14;
BA_ "GenMsgNrOfRepetition" BO_ 804 1;
BA_ "GenMsgCycleTimeFast" BO_ 804 50;
BA_ "VFrameFormat" BO_ 804 14;
BA_ "GenMsgNrOfRepetition" BO_ 805 1;
BA_ "GenMsgCycleTimeFast" BO_ 805 50;
BA_ "VFrameFormat" BO_ 805 14;
BA_ "GenMsgNrOfRepetition" BO_ 826 1;
BA_ "GenMsgCycleTime" BO_ 826 200;
BA_ "GenMsgCycleTimeFast" BO_ 826 10;
BA_ "GenMsgSendType" BO_ 826 5;
BA_ "VFrameFormat" BO_ 826 14;
BA_ "GenMsgNrOfRepetition" BO_ 851 1;
BA_ "GenMsgSendType" BO_ 851 5;
BA_ "VFrameFormat" BO_ 851 14;
BA_ "VFrameFormat" BO_ 854 14;
BA_ "GenMsgNrOfRepetition" BO_ 856 1;
BA_ "GenMsgCycleTime" BO_ 856 200;
BA_ "GenMsgDelayTime" BO_ 856 5;
BA_ "GenMsgCycleTimeFast" BO_ 856 20;
BA_ "GenMsgSendType" BO_ 856 5;
BA_ "VFrameFormat" BO_ 856 14;
BA_ "GenMsgCycleTime" BO_ 917 200;
BA_ "VFrameFormat" BO_ 917 14;
BA_ "GenMsgCycleTime" BO_ 965 5000;
BA_ "VFrameFormat" BO_ 965 14;
BA_ "GenMsgCycleTime" BO_ 969 5000;
BA_ "VFrameFormat" BO_ 969 14;
BA_ "GenMsgCycleTime" BO_ 997 1000;
BA_ "VFrameFormat" BO_ 997 14;
BA_ "GenMsgCycleTime" BO_ 1016 1000;
BA_ "VFrameFormat" BO_ 1016 14;
BA_ "GenMsgNrOfRepetition" BO_ 1080 1;
BA_ "GenMsgCycleTime" BO_ 1080 200;
BA_ "GenMsgCycleTimeFast" BO_ 1080 20;
BA_ "GenMsgSendType" BO_ 1080 5;
BA_ "VFrameFormat" BO_ 1080 14;
BA_ "GenMsgCycleTime" BO_ 1090 200;
BA_ "VFrameFormat" BO_ 1090 14;
BA_ "GenMsgCycleTime" BO_ 1174 300000;
BA_ "VFrameFormat" BO_ 1174 14;
BA_ "GenMsgCycleTime" BO_ 1280 0;
BA_ "NmMessage" BO_ 1280 1;
BA_ "GenMsgSendType" BO_ 1280 3;
BA_ "GenMsgCycleTime" BO_ 1284 0;
BA_ "NmMessage" BO_ 1284 1;
BA_ "GenMsgSendType" BO_ 1284 3;
BA_ "GenMsgCycleTime" BO_ 1285 0;
BA_ "GenMsgSendType" BO_ 1285 3;
BA_ "GenMsgCycleTime" BO_ 1344 0;
BA_ "NmMessage" BO_ 1344 1;
BA_ "GenMsgSendType" BO_ 1344 3;
BA_ "GenMsgCycleTime" BO_ 1540 0;
BA_ "DiagResponse" BO_ 1540 1;
BA_ "GenMsgSendType" BO_ 1540 3;
BA_ "VFrameFormat" BO_ 1540 14;
BA_ "DoIPLogicalAddress" BO_ 1540 "0x0684";
BA_ "GenMsgCycleTime" BO_ 1541 0;
BA_ "DiagResponse" BO_ 1541 1;
BA_ "GenMsgSendType" BO_ 1541 3;
BA_ "VFrameFormat" BO_ 1541 14;
BA_ "DoIPLogicalAddress" BO_ 1541 "0x0685";
BA_ "GenMsgCycleTime" BO_ 1556 0;
BA_ "DiagResponse" BO_ 1556 1;
BA_ "GenMsgSendType" BO_ 1556 3;
BA_ "VFrameFormat" BO_ 1556 14;
BA_ "DoIPLogicalAddress" BO_ 1556 "0x0694";
BA_ "GenMsgCycleTime" BO_ 1572 0;
BA_ "DiagResponse" BO_ 1572 1;
BA_ "GenMsgSendType" BO_ 1572 3;
BA_ "VFrameFormat" BO_ 1572 14;
BA_ "DoIPLogicalAddress" BO_ 1572 "0x06A4";
BA_ "GenMsgCycleTime" BO_ 1588 0;
BA_ "DiagResponse" BO_ 1588 1;
BA_ "GenMsgSendType" BO_ 1588 3;
BA_ "VFrameFormat" BO_ 1588 14;
BA_ "DoIPLogicalAddress" BO_ 1588 "0x06B4";
BA_ "GenMsgCycleTime" BO_ 1600 0;
BA_ "DiagResponse" BO_ 1600 1;
BA_ "GenMsgSendType" BO_ 1600 3;
BA_ "VFrameFormat" BO_ 1600 14;
BA_ "DoIPLogicalAddress" BO_ 1600 "0x06C0";
BA_ "GenMsgCycleTime" BO_ 1668 0;
BA_ "DiagRequest" BO_ 1668 1;
BA_ "GenMsgSendType" BO_ 1668 3;
BA_ "VFrameFormat" BO_ 1668 14;
BA_ "DoIPLogicalAddress" BO_ 1668 "0x0684";
BA_ "GenMsgCycleTime" BO_ 1669 0;
BA_ "DiagRequest" BO_ 1669 1;
BA_ "GenMsgSendType" BO_ 1669 3;
BA_ "VFrameFormat" BO_ 1669 14;
BA_ "DoIPLogicalAddress" BO_ 1669 "0x0685";
BA_ "GenMsgCycleTime" BO_ 1684 0;
BA_ "DiagRequest" BO_ 1684 1;
BA_ "GenMsgSendType" BO_ 1684 3;
BA_ "VFrameFormat" BO_ 1684 14;
BA_ "DoIPLogicalAddress" BO_ 1684 "0x0694";
BA_ "GenMsgCycleTime" BO_ 1700 0;
BA_ "DiagRequest" BO_ 1700 1;
BA_ "GenMsgSendType" BO_ 1700 3;
BA_ "VFrameFormat" BO_ 1700 14;
BA_ "DoIPLogicalAddress" BO_ 1700 "0x06A4";
BA_ "GenMsgCycleTime" BO_ 1716 0;
BA_ "DiagRequest" BO_ 1716 1;
BA_ "GenMsgSendType" BO_ 1716 3;
BA_ "VFrameFormat" BO_ 1716 14;
BA_ "DoIPLogicalAddress" BO_ 1716 "0x06B4";
BA_ "GenMsgCycleTime" BO_ 1728 0;
BA_ "DiagRequest" BO_ 1728 1;
BA_ "GenMsgSendType" BO_ 1728 3;
BA_ "VFrameFormat" BO_ 1728 14;
BA_ "DoIPLogicalAddress" BO_ 1728 "0x06C0";
BA_ "GenMsgCycleTime" BO_ 2000 0;
BA_ "DiagRequest" BO_ 2000 1;
BA_ "GenMsgSendType" BO_ 2000 3;
BA_ "VFrameFormat" BO_ 2000 14;
BA_ "DoIPLogicalAddress" BO_ 2000 "0xEFFF";
BA_ "GenMsgCycleTime" BO_ 1573 0;
BA_ "DiagResponse" BO_ 1573 1;
BA_ "GenMsgSendType" BO_ 1573 3;
BA_ "VFrameFormat" BO_ 1573 14;
BA_ "DoIPLogicalAddress" BO_ 1573 "0x06A5";
BA_ "GenMsgCycleTime" BO_ 1701 0;
BA_ "DiagRequest" BO_ 1701 1;
BA_ "GenMsgSendType" BO_ 1701 3;
BA_ "VFrameFormat" BO_ 1701 14;
BA_ "DoIPLogicalAddress" BO_ 1701 "0x06A5";
BA_ "GenMsgCycleTime" BO_ 1733 0;
BA_ "DiagRequest" BO_ 1733 1;
BA_ "GenMsgSendType" BO_ 1733 3;
BA_ "VFrameFormat" BO_ 1733 14;
BA_ "DoIPLogicalAddress" BO_ 1733 "0x06C5";
BA_ "GenMsgCycleTime" BO_ 1605 0;
BA_ "DiagResponse" BO_ 1605 1;
BA_ "GenMsgSendType" BO_ 1605 3;
BA_ "VFrameFormat" BO_ 1605 14;
BA_ "DoIPLogicalAddress" BO_ 1605 "0x06C5";
BA_ "VFrameFormat" BO_ 881 14;
BA_ "GenMsgNrOfRepetition" BO_ 928 1;
BA_ "DataID_Hex" BO_ 928 14849;
BA_ "DataID" BO_ 928 "0x3A01";
BA_ "GenMsgSendType" BO_ 928 5;
BA_ "VFrameFormat" BO_ 928 14;
BA_ "GenSigInvalidValue" SG_ 596 EWP1_RPM_Target_Stat 255;
BA_ "GenSigInvalidValue" SG_ 596 EWP1_Curr_Stat 255;
BA_ "GenSigInvalidValue" SG_ 596 EWP1_Block_Error 3;
BA_ "GenSigInvalidValue" SG_ 596 EWP1_DryRun_Error 3;
BA_ "GenSigInvalidValue" SG_ 596 EWP1_OverCurr_Error 3;
BA_ "GenSigInvalidValue" SG_ 596 EWP2_Curr_Stat 255;
BA_ "GenSigInvalidValue" SG_ 596 EWP2_Block_Error 3;
BA_ "GenSigInvalidValue" SG_ 596 EWP2_DryRun_Error 3;
BA_ "GenSigInvalidValue" SG_ 596 EWP2_OverCurr_Error 3;
BA_ "GenSigInvalidValue" SG_ 596 EWP3_Block_Error 3;
BA_ "GenSigInvalidValue" SG_ 596 EWP3_DryRun_Error 3;
BA_ "GenSigInvalidValue" SG_ 596 EWP3_Curr_Stat 255;
BA_ "GenSigInvalidValue" SG_ 596 EWP3_OverCurr_Error 3;
BA_ "GenSigInvalidValue" SG_ 602 METER_KPH_Calcu 255;
BA_ "GenSigInvalidValue" SG_ 602 METER_MPH_Calcu 255;
BA_ "GenSigInvalidValue" SG_ 602 METER_KPH_Real 4095;
BA_ "GenSigInvalidValue" SG_ 602 METER_MPH_Real 4095;
BA_ "GenSigInvalidValue" SG_ 602 Averaged_vehspeed 1023;
BA_ "GenSigInvalidValue" SG_ 602 AVGPwrConsumption 65535;
BA_ "GenSigStartValue" SG_ 602 AVGPwrConsumption 9999;
BA_ "GenSigInvalidValue" SG_ 602 APCforDTE 65535;
BA_ "GenSigStartValue" SG_ 602 APCforDTE 9999;
BA_ "GenSigInvalidValue" SG_ 602 AvailableTrip 65535;
BA_ "GenSigInvalidValue" SG_ 602 Spd_Crl_Mode 5;
BA_ "GenSigSendType" SG_ 602 LEDlitWarnReq 3;
BA_ "GenSigSendType" SG_ 602 Charge 3;
BA_ "GenSigSendType" SG_ 602 ParkBrake 3;
BA_ "GenSigSendType" SG_ 602 Trip_B 3;
BA_ "GenSigSendType" SG_ 602 Trip_A 3;
BA_ "GenSigSendType" SG_ 602 ODOMETER 3;
BA_ "GenSigInvalidValue" SG_ 659 Zone_Spd_Ctrl_Mode 5;
BA_ "GenSigSendType" SG_ 659 Zone_Spd_Ctrl_Mode 3;
BA_ "GenSigSendType" SG_ 659 Zone_Spd_Ctrl_Sta 3;
BA_ "GenSigInvalidValue" SG_ 659 RegenMode 7;
BA_ "GenSigSendType" SG_ 659 RegenMode 3;
BA_ "GenSigSendType" SG_ 659 DrSCPSysErrLmp 3;
BA_ "GenSigSendType" SG_ 659 Set_Spd 3;
BA_ "GenSigInvalidValue" SG_ 778 CCM_SpdCmd 32767;
BA_ "GenSigStartValue" SG_ 778 EAC_Temp 101;
BA_ "GenSigInvalidValue" SG_ 778 COMP_StatorSpd 16383;
BA_ "GenSigStartValue" SG_ 778 BMSPackVol_h6HSC6 4095;
BA_ "GenSigInvalidValue" SG_ 796 COMP_ActualPwr 8191;
BA_ "GenSigSendType" SG_ 826 SWC_CANCEL_Sta 3;
BA_ "GenSigSendType" SG_ 826 SWC_ACC_Sta 3;
BA_ "GenSigSendType" SG_ 826 SWC_Distance_Sta 3;
BA_ "GenSigSendType" SG_ 826 SWC_Down_Sta 3;
BA_ "GenSigSendType" SG_ 826 SWC_RegenUp 3;
BA_ "GenSigSendType" SG_ 826 SWC_Left_Sta 3;
BA_ "GenSigSendType" SG_ 826 SWC_mode_Sta 3;
BA_ "GenSigSendType" SG_ 826 SWC_Res_Up_Sta 3;
BA_ "GenSigSendType" SG_ 826 SWC_RegenDown 3;
BA_ "GenSigSendType" SG_ 826 SWC_Right_Sta 3;
BA_ "GenSigSendType" SG_ 826 SWC_Set_down_Sta 3;
BA_ "GenSigSendType" SG_ 826 SWC_Trip_Sta 3;
BA_ "GenSigSendType" SG_ 826 SWC_Up_Sta 3;
BA_ "GenSigSendType" SG_ 826 SWC_VR_Sta 3;
BA_ "GenSigSendType" SG_ 826 SWC_Undefined_Sta 3;
BA_ "GenSigSendType" SG_ 826 SWC_LKA_Sta 3;
BA_ "GenSigRoutingTimeoutValue" SG_ 851 L_RRD_Val_Wdw_Opened 127;
BA_ "GenSigRoutingTimeoutValue" SG_ 851 L_RRD_Wdw_PositionSts 3;
BA_ "GenSigRoutingTimeoutValue" SG_ 851 L_RLD_Val_Wdw_Opened 127;
BA_ "GenSigRoutingTimeoutValue" SG_ 851 L_RLD_Wdw_PositionSts 3;
BA_ "GenSigSendType" SG_ 851 PTG_Inner_SW_2 3;
BA_ "GenSigRoutingTimeoutValue" SG_ 854 L_Pas_Val_Wdw_Opened 127;
BA_ "GenSigRoutingTimeoutValue" SG_ 854 L_Pas_Wdw_PositionSts 3;
BA_ "GenSigRoutingTimeoutValue" SG_ 854 L_Drv_Val_Wdw_Opened 127;
BA_ "GenSigRoutingTimeoutValue" SG_ 854 L_Drv_Wdw_PositionSts 3;
BA_ "GenSigSendType" SG_ 856 DSEAT_Vent_Sta 3;
BA_ "GenSigSendType" SG_ 856 DSEAT_AntiAct_Sta 3;
BA_ "GenSigSendType" SG_ 856 DSEAT_Anti_Sta 3;
BA_ "GenSigSendType" SG_ 856 DSEAT_EntryAct_Sta 3;
BA_ "GenSigSendType" SG_ 856 DSEAT_EntryFun_Sta 3;
BA_ "GenSigSendType" SG_ 856 DSEAT_Error_Sta 3;
BA_ "GenSigInvalidValue" SG_ 1080 OTA_Progress_Rate 102;
BA_ "GenSigSendType" SG_ 1080 OTA_Progress_Rate 3;
BA_ "GenSigSendType" SG_ 1080 OTA_MDA_Status 3;
BA_ "GenSigSendType" SG_ 1080 OTA_Network_Type 3;
BA_ "GenSigSendType" SG_ 1080 OTA_Mode 3;
BA_ "GenSigSendType" SG_ 1080 OTA_DL_Available 3;
BA_ "GenSigSendType" SG_ 1080 OTA_InVehicle_FW 3;
BA_ "GenSigSendType" SG_ 1080 OTA_Update_Available 3;
BA_ "GenSigInvalidValue" SG_ 1080 OTA_Updating_ECU 30;
BA_ "GenSigSendType" SG_ 1080 OTA_Updating_ECU 3;
BA_ "GenSigSendType" SG_ 1080 OTA_Lock_Req 3;
BA_ "GenSigSendType" SG_ 1080 OTA_DL_Speed 3;
BA_ "GenSigInvalidValue" SG_ 1080 OTA_Up_Backcount 122;
BA_ "GenSigSendType" SG_ 1080 OTA_Up_Backcount 3;
BA_ "GenSigSendType" SG_ 1280 NM_FUSION_Node_ID 7;
BA_ "GenSigSendType" SG_ 1280 NM_FUSION_PNI 7;
BA_ "GenSigSendType" SG_ 1280 NM_FUSION_Active_WU 7;
BA_ "GenSigSendType" SG_ 1280 NM_FUSION_CSB 7;
BA_ "GenSigSendType" SG_ 1280 NM_FUSION_Rpt_Msg_Req 7;
BA_ "GenSigSendType" SG_ 1280 NM_FUSION_ERROR_State 7;
BA_ "GenSigSendType" SG_ 1284 NM_ZONE_FR_Node_ID 7;
BA_ "GenSigSendType" SG_ 1284 NM_ZONE_FR_PNI 7;
BA_ "GenSigSendType" SG_ 1284 NM_ZONE_FR_Active_WU 7;
BA_ "GenSigSendType" SG_ 1284 NM_ZONE_FR_CSB 7;
BA_ "GenSigSendType" SG_ 1284 NM_ZONE_FR_Rpt_Msg_Req 7;
BA_ "GenSigSendType" SG_ 1284 NM_ZONE_FR_ERROR_State 7;
BA_ "GenSigSendType" SG_ 1344 NM_ZONE_DR_Node_ID 7;
BA_ "GenSigSendType" SG_ 1344 NM_ZONE_DR_PNI 7;
BA_ "GenSigSendType" SG_ 1344 NM_ZONE_DR_Active_WU 7;
BA_ "GenSigSendType" SG_ 1344 NM_ZONE_DR_CSB 7;
BA_ "GenSigSendType" SG_ 1344 NM_ZONE_DR_Rpt_Msg_Req 7;
BA_ "GenSigSendType" SG_ 1344 NM_ZONE_DR_ERROR_State 7;
BA_ "GenSigSendType" SG_ 1540 DiagRespFromZONE_FR 3;
BA_ "GenSigSendType" SG_ 1541 DiagRespFromDKC 3;
BA_ "GenSigSendType" SG_ 1556 DiagRespFromDSEAT 3;
BA_ "GenSigSendType" SG_ 1572 DiagRespFromPSEAT 3;
BA_ "GenSigSendType" SG_ 1588 DiagRespFromPTG 3;
BA_ "GenSigSendType" SG_ 1600 DiagRespFromZONE_DR 3;
BA_ "GenSigSendType" SG_ 1668 DiagPhysReqToZONE_FR 3;
BA_ "GenSigSendType" SG_ 1669 DiagPhysReqToDKC 3;
BA_ "GenSigSendType" SG_ 1684 DiagPhysReqToDSEAT 3;
BA_ "GenSigSendType" SG_ 1700 DiagPhysReqToPSEAT 3;
BA_ "GenSigSendType" SG_ 1716 DiagPhysReqToPTG 3;
BA_ "GenSigSendType" SG_ 1728 DiagPhysReqToZONE_DR 3;
BA_ "GenSigSendType" SG_ 2000 DiagFuncReqFT 3;
BA_ "GenSigSendType" SG_ 1573 DiagRespFromAirPTC 3;
BA_ "GenSigSendType" SG_ 1701 DiagPhysReqToAirPTC 3;
BA_ "GenSigSendType" SG_ 1733 DiagPhysReqToCompressor 3;
BA_ "GenSigSendType" SG_ 1605 DiagRespFromCompressor 3;
BA_ "GenSigSendType" SG_ 928 FDC_VCU_ReqHWReset_Cmd 3;
BA_ "GenSigSendType" SG_ 928 FD4_CE100_2_CS 3;
BA_ "GenSigSendType" SG_ 928 FD4_CE100_2_RC 3;
VAL_ 596 EXV_Rsp_Fault_Stat 15 "not defined" 14 "not defined" 13 "not defined" 12 "not defined" 11 "not defined" 10 "not defined" 9 "not defined" 8 "not defined" 7 "not defined" 6 "not defined" 5 "not defined" 4 "not defined" 3 "Over temperature shutdown" 2 "Motor-Coil open load" 1 "Motor-Coil shorted" 0 "Actuator Not Faulted";
VAL_ 596 EXV_Rsp_CurInit_Stat 3 "Unused and Undefined" 2 "Initialized" 1 "Initialization in Process" 0 "Not Initialized";
VAL_ 596 EXV_Rsp_OvrTemp_Warn 3 "not defined" 2 "not defined" 1 "High Temperature Warning" 0 "Ok";
VAL_ 596 EXV_Rsp_Volt_Stat 3 "not defined" 2 "Under voltage" 1 "Overvoltage" 0 "Voltage Range ok";
VAL_ 596 EXV_RsErr_EXV 1 "Comm Error detected" 0 "No Comm Error";
VAL_ 596 EXV_Rsp_Run_Stat 1 "Actuator is moving" 0 "Actuator is not moving";
VAL_ 596 EWP1_RsErr_EWP 1 "ERROR" 0 "NO ERROR";
VAL_ 596 EWP1_SupVolt_Error 2 "SNA" 1 "ERROR" 0 "NO ERROR";
VAL_ 596 EWP1_RPM_Target_Stat 255 "Invalid" 254 "max speed rpm" 253 "max speed rpm" 252 "max speed rpm" 251 "max speed rpm" 250 "linearly changed from min speed to max speed" 249 "linearly changed from min speed to max speed" 248 "linearly changed from min speed to max speed" 247 "linearly changed from min speed to max speed" 246 "linearly changed from min speed to max speed" 245 "linearly changed from min speed to max speed" 244 "linearly changed from min speed to max speed" 243 "linearly changed from min speed to max speed" 242 "linearly changed from min speed to max speed" 241 "linearly changed from min speed to max speed" 240 "linearly changed from min speed to max speed" 239 "linearly changed from min speed to max speed" 238 "linearly changed from min speed to max speed" 237 "linearly changed from min speed to max speed" 236 "linearly changed from min speed to max speed" 235 "linearly changed from min speed to max speed" 234 "linearly changed from min speed to max speed" 233 "linearly changed from min speed to max speed" 232 "linearly changed from min speed to max speed" 231 "linearly changed from min speed to max speed" 230 "linearly changed from min speed to max speed" 229 "linearly changed from min speed to max speed" 228 "linearly changed from min speed to max speed" 227 "linearly changed from min speed to max speed" 226 "linearly changed from min speed to max speed" 225 "linearly changed from min speed to max speed" 224 "linearly changed from min speed to max speed" 223 "linearly changed from min speed to max speed" 222 "linearly changed from min speed to max speed" 221 "linearly changed from min speed to max speed" 220 "linearly changed from min speed to max speed" 219 "linearly changed from min speed to max speed" 218 "linearly changed from min speed to max speed" 217 "linearly changed from min speed to max speed" 216 "linearly changed from min speed to max speed" 215 "linearly changed from min speed to max speed" 214 "linearly changed from min speed to max speed" 213 "linearly changed from min speed to max speed" 212 "linearly changed from min speed to max speed" 211 "linearly changed from min speed to max speed" 210 "linearly changed from min speed to max speed" 209 "linearly changed from min speed to max speed" 208 "linearly changed from min speed to max speed" 207 "linearly changed from min speed to max speed" 206 "linearly changed from min speed to max speed" 205 "linearly changed from min speed to max speed" 204 "linearly changed from min speed to max speed" 203 "linearly changed from min speed to max speed" 202 "linearly changed from min speed to max speed" 201 "linearly changed from min speed to max speed" 200 "linearly changed from min speed to max speed" 199 "linearly changed from min speed to max speed" 198 "linearly changed from min speed to max speed" 197 "linearly changed from min speed to max speed" 196 "linearly changed from min speed to max speed" 195 "linearly changed from min speed to max speed" 194 "linearly changed from min speed to max speed" 193 "linearly changed from min speed to max speed" 192 "linearly changed from min speed to max speed" 191 "linearly changed from min speed to max speed" 190 "linearly changed from min speed to max speed" 189 "linearly changed from min speed to max speed" 188 "linearly changed from min speed to max speed" 187 "linearly changed from min speed to max speed" 186 "linearly changed from min speed to max speed" 185 "linearly changed from min speed to max speed" 184 "linearly changed from min speed to max speed" 183 "linearly changed from min speed to max speed" 182 "linearly changed from min speed to max speed" 181 "linearly changed from min speed to max speed" 180 "linearly changed from min speed to max speed" 179 "linearly changed from min speed to max speed" 178 "linearly changed from min speed to max speed" 177 "linearly changed from min speed to max speed" 176 "linearly changed from min speed to max speed" 175 "linearly changed from min speed to max speed" 174 "linearly changed from min speed to max speed" 173 "linearly changed from min speed to max speed" 172 "linearly changed from min speed to max speed" 171 "linearly changed from min speed to max speed" 170 "linearly changed from min speed to max speed" 169 "linearly changed from min speed to max speed" 168 "linearly changed from min speed to max speed" 167 "linearly changed from min speed to max speed" 166 "linearly changed from min speed to max speed" 165 "linearly changed from min speed to max speed" 164 "linearly changed from min speed to max speed" 163 "linearly changed from min speed to max speed" 162 "linearly changed from min speed to max speed" 161 "linearly changed from min speed to max speed" 160 "linearly changed from min speed to max speed" 159 "linearly changed from min speed to max speed" 158 "linearly changed from min speed to max speed" 157 "linearly changed from min speed to max speed" 156 "linearly changed from min speed to max speed" 155 "linearly changed from min speed to max speed" 154 "linearly changed from min speed to max speed" 153 "linearly changed from min speed to max speed" 152 "linearly changed from min speed to max speed" 151 "linearly changed from min speed to max speed" 150 "linearly changed from min speed to max speed" 149 "linearly changed from min speed to max speed" 148 "linearly changed from min speed to max speed" 147 "linearly changed from min speed to max speed" 146 "linearly changed from min speed to max speed" 145 "linearly changed from min speed to max speed" 144 "linearly changed from min speed to max speed" 143 "linearly changed from min speed to max speed" 142 "linearly changed from min speed to max speed" 141 "linearly changed from min speed to max speed" 140 "linearly changed from min speed to max speed" 139 "linearly changed from min speed to max speed" 138 "linearly changed from min speed to max speed" 137 "linearly changed from min speed to max speed" 136 "linearly changed from min speed to max speed" 135 "linearly changed from min speed to max speed" 134 "linearly changed from min speed to max speed" 133 "linearly changed from min speed to max speed" 132 "linearly changed from min speed to max speed" 131 "linearly changed from min speed to max speed" 130 "linearly changed from min speed to max speed" 129 "linearly changed from min speed to max speed" 128 "linearly changed from min speed to max speed" 127 "linearly changed from min speed to max speed" 126 "linearly changed from min speed to max speed" 125 "linearly changed from min speed to max speed" 124 "linearly changed from min speed to max speed" 123 "linearly changed from min speed to max speed" 122 "linearly changed from min speed to max speed" 121 "linearly changed from min speed to max speed" 120 "linearly changed from min speed to max speed" 119 "linearly changed from min speed to max speed" 118 "linearly changed from min speed to max speed" 117 "linearly changed from min speed to max speed" 116 "linearly changed from min speed to max speed" 115 "linearly changed from min speed to max speed" 114 "linearly changed from min speed to max speed" 113 "linearly changed from min speed to max speed" 112 "linearly changed from min speed to max speed" 111 "linearly changed from min speed to max speed" 110 "linearly changed from min speed to max speed" 109 "linearly changed from min speed to max speed" 108 "linearly changed from min speed to max speed" 107 "linearly changed from min speed to max speed" 106 "linearly changed from min speed to max speed" 105 "linearly changed from min speed to max speed" 104 "linearly changed from min speed to max speed" 103 "linearly changed from min speed to max speed" 102 "linearly changed from min speed to max speed" 101 "linearly changed from min speed to max speed" 100 "linearly changed from min speed to max speed" 99 "linearly changed from min speed to max speed" 98 "linearly changed from min speed to max speed" 97 "linearly changed from min speed to max speed" 96 "linearly changed from min speed to max speed" 95 "linearly changed from min speed to max speed" 94 "linearly changed from min speed to max speed" 93 "linearly changed from min speed to max speed" 92 "linearly changed from min speed to max speed" 91 "linearly changed from min speed to max speed" 90 "linearly changed from min speed to max speed" 89 "linearly changed from min speed to max speed" 88 "linearly changed from min speed to max speed" 87 "linearly changed from min speed to max speed" 86 "linearly changed from min speed to max speed" 85 "linearly changed from min speed to max speed" 84 "linearly changed from min speed to max speed" 83 "linearly changed from min speed to max speed" 82 "linearly changed from min speed to max speed" 81 "linearly changed from min speed to max speed" 80 "linearly changed from min speed to max speed" 79 "linearly changed from min speed to max speed" 78 "linearly changed from min speed to max speed" 77 "linearly changed from min speed to max speed" 76 "linearly changed from min speed to max speed" 75 "linearly changed from min speed to max speed" 74 "linearly changed from min speed to max speed" 73 "linearly changed from min speed to max speed" 72 "linearly changed from min speed to max speed" 71 "linearly changed from min speed to max speed" 70 "linearly changed from min speed to max speed" 69 "linearly changed from min speed to max speed" 68 "linearly changed from min speed to max speed" 67 "linearly changed from min speed to max speed" 66 "linearly changed from min speed to max speed" 65 "linearly changed from min speed to max speed" 64 "linearly changed from min speed to max speed" 63 "linearly changed from min speed to max speed" 62 "linearly changed from min speed to max speed" 61 "linearly changed from min speed to max speed" 60 "linearly changed from min speed to max speed" 59 "linearly changed from min speed to max speed" 58 "linearly changed from min speed to max speed" 57 "linearly changed from min speed to max speed" 56 "linearly changed from min speed to max speed" 55 "linearly changed from min speed to max speed" 54 "linearly changed from min speed to max speed" 53 "linearly changed from min speed to max speed" 52 "linearly changed from min speed to max speed" 51 "linearly changed from min speed to max speed" 50 "linearly changed from min speed to max speed" 49 "min speed rpm" 48 "min speed rpm" 47 "min speed rpm" 46 "min speed rpm" 45 "min speed rpm" 44 "min speed rpm" 43 "min speed rpm" 42 "min speed rpm" 41 "min speed rpm" 40 "min speed rpm" 39 "min speed rpm" 38 "min speed rpm" 37 "min speed rpm" 36 "min speed rpm" 35 "min speed rpm" 34 "min speed rpm" 33 "min speed rpm" 32 "min speed rpm" 31 "min speed rpm" 30 "min speed rpm" 29 "min speed rpm" 28 "min speed rpm" 27 "min speed rpm" 26 "min speed rpm" 25 "min speed rpm" 24 "min speed rpm" 23 "min speed rpm" 22 "min speed rpm" 21 "min speed rpm" 20 "min speed rpm" 19 "min speed rpm" 18 "min speed rpm" 17 "min speed rpm" 16 "min speed rpm" 15 "min speed rpm" 14 "min speed rpm" 13 "min speed rpm" 12 "min speed rpm" 11 "min speed rpm" 10 "min speed rpm" 9 "min speed rpm" 8 "min speed rpm" 7 "min speed rpm" 6 "min speed rpm" 5 "min speed rpm" 4 "min speed rpm" 3 "0 rpm" 2 "0 rpm" 1 "0 rpm" 0 "0 rpm";
VAL_ 596 EWP1_RPM_ActlVal_Stat 255 "Invalid" 254 "max speed rpm" 253 "max speed rpm" 252 "max speed rpm" 251 "max speed rpm" 250 "linearly changed from min speed to max speed" 249 "linearly changed from min speed to max speed" 248 "linearly changed from min speed to max speed" 247 "linearly changed from min speed to max speed" 246 "linearly changed from min speed to max speed" 245 "linearly changed from min speed to max speed" 244 "linearly changed from min speed to max speed" 243 "linearly changed from min speed to max speed" 242 "linearly changed from min speed to max speed" 241 "linearly changed from min speed to max speed" 240 "linearly changed from min speed to max speed" 239 "linearly changed from min speed to max speed" 238 "linearly changed from min speed to max speed" 237 "linearly changed from min speed to max speed" 236 "linearly changed from min speed to max speed" 235 "linearly changed from min speed to max speed" 234 "linearly changed from min speed to max speed" 233 "linearly changed from min speed to max speed" 232 "linearly changed from min speed to max speed" 231 "linearly changed from min speed to max speed" 230 "linearly changed from min speed to max speed" 229 "linearly changed from min speed to max speed" 228 "linearly changed from min speed to max speed" 227 "linearly changed from min speed to max speed" 226 "linearly changed from min speed to max speed" 225 "linearly changed from min speed to max speed" 224 "linearly changed from min speed to max speed" 223 "linearly changed from min speed to max speed" 222 "linearly changed from min speed to max speed" 221 "linearly changed from min speed to max speed" 220 "linearly changed from min speed to max speed" 219 "linearly changed from min speed to max speed" 218 "linearly changed from min speed to max speed" 217 "linearly changed from min speed to max speed" 216 "linearly changed from min speed to max speed" 215 "linearly changed from min speed to max speed" 214 "linearly changed from min speed to max speed" 213 "linearly changed from min speed to max speed" 212 "linearly changed from min speed to max speed" 211 "linearly changed from min speed to max speed" 210 "linearly changed from min speed to max speed" 209 "linearly changed from min speed to max speed" 208 "linearly changed from min speed to max speed" 207 "linearly changed from min speed to max speed" 206 "linearly changed from min speed to max speed" 205 "linearly changed from min speed to max speed" 204 "linearly changed from min speed to max speed" 203 "linearly changed from min speed to max speed" 202 "linearly changed from min speed to max speed" 201 "linearly changed from min speed to max speed" 200 "linearly changed from min speed to max speed" 199 "linearly changed from min speed to max speed" 198 "linearly changed from min speed to max speed" 197 "linearly changed from min speed to max speed" 196 "linearly changed from min speed to max speed" 195 "linearly changed from min speed to max speed" 194 "linearly changed from min speed to max speed" 193 "linearly changed from min speed to max speed" 192 "linearly changed from min speed to max speed" 191 "linearly changed from min speed to max speed" 190 "linearly changed from min speed to max speed" 189 "linearly changed from min speed to max speed" 188 "linearly changed from min speed to max speed" 187 "linearly changed from min speed to max speed" 186 "linearly changed from min speed to max speed" 185 "linearly changed from min speed to max speed" 184 "linearly changed from min speed to max speed" 183 "linearly changed from min speed to max speed" 182 "linearly changed from min speed to max speed" 181 "linearly changed from min speed to max speed" 180 "linearly changed from min speed to max speed" 179 "linearly changed from min speed to max speed" 178 "linearly changed from min speed to max speed" 177 "linearly changed from min speed to max speed" 176 "linearly changed from min speed to max speed" 175 "linearly changed from min speed to max speed" 174 "linearly changed from min speed to max speed" 173 "linearly changed from min speed to max speed" 172 "linearly changed from min speed to max speed" 171 "linearly changed from min speed to max speed" 170 "linearly changed from min speed to max speed" 169 "linearly changed from min speed to max speed" 168 "linearly changed from min speed to max speed" 167 "linearly changed from min speed to max speed" 166 "linearly changed from min speed to max speed" 165 "linearly changed from min speed to max speed" 164 "linearly changed from min speed to max speed" 163 "linearly changed from min speed to max speed" 162 "linearly changed from min speed to max speed" 161 "linearly changed from min speed to max speed" 160 "linearly changed from min speed to max speed" 159 "linearly changed from min speed to max speed" 158 "linearly changed from min speed to max speed" 157 "linearly changed from min speed to max speed" 156 "linearly changed from min speed to max speed" 155 "linearly changed from min speed to max speed" 154 "linearly changed from min speed to max speed" 153 "linearly changed from min speed to max speed" 152 "linearly changed from min speed to max speed" 151 "linearly changed from min speed to max speed" 150 "linearly changed from min speed to max speed" 149 "linearly changed from min speed to max speed" 148 "linearly changed from min speed to max speed" 147 "linearly changed from min speed to max speed" 146 "linearly changed from min speed to max speed" 145 "linearly changed from min speed to max speed" 144 "linearly changed from min speed to max speed" 143 "linearly changed from min speed to max speed" 142 "linearly changed from min speed to max speed" 141 "linearly changed from min speed to max speed" 140 "linearly changed from min speed to max speed" 139 "linearly changed from min speed to max speed" 138 "linearly changed from min speed to max speed" 137 "linearly changed from min speed to max speed" 136 "linearly changed from min speed to max speed" 135 "linearly changed from min speed to max speed" 134 "linearly changed from min speed to max speed" 133 "linearly changed from min speed to max speed" 132 "linearly changed from min speed to max speed" 131 "linearly changed from min speed to max speed" 130 "linearly changed from min speed to max speed" 129 "linearly changed from min speed to max speed" 128 "linearly changed from min speed to max speed" 127 "linearly changed from min speed to max speed" 126 "linearly changed from min speed to max speed" 125 "linearly changed from min speed to max speed" 124 "linearly changed from min speed to max speed" 123 "linearly changed from min speed to max speed" 122 "linearly changed from min speed to max speed" 121 "linearly changed from min speed to max speed" 120 "linearly changed from min speed to max speed" 119 "linearly changed from min speed to max speed" 118 "linearly changed from min speed to max speed" 117 "linearly changed from min speed to max speed" 116 "linearly changed from min speed to max speed" 115 "linearly changed from min speed to max speed" 114 "linearly changed from min speed to max speed" 113 "linearly changed from min speed to max speed" 112 "linearly changed from min speed to max speed" 111 "linearly changed from min speed to max speed" 110 "linearly changed from min speed to max speed" 109 "linearly changed from min speed to max speed" 108 "linearly changed from min speed to max speed" 107 "linearly changed from min speed to max speed" 106 "linearly changed from min speed to max speed" 105 "linearly changed from min speed to max speed" 104 "linearly changed from min speed to max speed" 103 "linearly changed from min speed to max speed" 102 "linearly changed from min speed to max speed" 101 "linearly changed from min speed to max speed" 100 "linearly changed from min speed to max speed" 99 "linearly changed from min speed to max speed" 98 "linearly changed from min speed to max speed" 97 "linearly changed from min speed to max speed" 96 "linearly changed from min speed to max speed" 95 "linearly changed from min speed to max speed" 94 "linearly changed from min speed to max speed" 93 "linearly changed from min speed to max speed" 92 "linearly changed from min speed to max speed" 91 "linearly changed from min speed to max speed" 90 "linearly changed from min speed to max speed" 89 "linearly changed from min speed to max speed" 88 "linearly changed from min speed to max speed" 87 "linearly changed from min speed to max speed" 86 "linearly changed from min speed to max speed" 85 "linearly changed from min speed to max speed" 84 "linearly changed from min speed to max speed" 83 "linearly changed from min speed to max speed" 82 "linearly changed from min speed to max speed" 81 "linearly changed from min speed to max speed" 80 "linearly changed from min speed to max speed" 79 "linearly changed from min speed to max speed" 78 "linearly changed from min speed to max speed" 77 "linearly changed from min speed to max speed" 76 "linearly changed from min speed to max speed" 75 "linearly changed from min speed to max speed" 74 "linearly changed from min speed to max speed" 73 "linearly changed from min speed to max speed" 72 "linearly changed from min speed to max speed" 71 "linearly changed from min speed to max speed" 70 "linearly changed from min speed to max speed" 69 "linearly changed from min speed to max speed" 68 "linearly changed from min speed to max speed" 67 "linearly changed from min speed to max speed" 66 "linearly changed from min speed to max speed" 65 "linearly changed from min speed to max speed" 64 "linearly changed from min speed to max speed" 63 "linearly changed from min speed to max speed" 62 "linearly changed from min speed to max speed" 61 "linearly changed from min speed to max speed" 60 "linearly changed from min speed to max speed" 59 "linearly changed from min speed to max speed" 58 "linearly changed from min speed to max speed" 57 "linearly changed from min speed to max speed" 56 "linearly changed from min speed to max speed" 55 "linearly changed from min speed to max speed" 54 "linearly changed from min speed to max speed" 53 "linearly changed from min speed to max speed" 52 "linearly changed from min speed to max speed" 51 "linearly changed from min speed to max speed" 50 "linearly changed from min speed to max speed" 49 "min speed rpm" 48 "min speed rpm" 47 "min speed rpm" 46 "min speed rpm" 45 "min speed rpm" 44 "min speed rpm" 43 "min speed rpm" 42 "min speed rpm" 41 "min speed rpm" 40 "min speed rpm" 39 "min speed rpm" 38 "min speed rpm" 37 "min speed rpm" 36 "min speed rpm" 35 "min speed rpm" 34 "min speed rpm" 33 "min speed rpm" 32 "min speed rpm" 31 "min speed rpm" 30 "min speed rpm" 29 "min speed rpm" 28 "min speed rpm" 27 "min speed rpm" 26 "min speed rpm" 25 "min speed rpm" 24 "min speed rpm" 23 "min speed rpm" 22 "min speed rpm" 21 "min speed rpm" 20 "min speed rpm" 19 "min speed rpm" 18 "min speed rpm" 17 "min speed rpm" 16 "min speed rpm" 15 "min speed rpm" 14 "min speed rpm" 13 "min speed rpm" 12 "min speed rpm" 11 "min speed rpm" 10 "min speed rpm" 9 "min speed rpm" 8 "min speed rpm" 7 "min speed rpm" 6 "min speed rpm" 5 "min speed rpm" 4 "min speed rpm" 3 "0 rpm" 2 "0 rpm" 1 "0 rpm" 0 "0 rpm";
VAL_ 596 EWP1_Curr_Stat 255 "invalid";
VAL_ 596 EWP1_Block_Error 2 "SNA" 1 "ERROR" 0 "NO ERROR";
VAL_ 596 EWP1_DryRun_Error 2 "SNA" 1 "ERROR" 0 "NO ERROR";
VAL_ 596 EWP1_OverTemp_Error 2 "OverTempDegrade" 1 "ERROR" 0 "NO ERROR";
VAL_ 596 EWP1_Temp_Stat 255 "Invalid";
VAL_ 596 EWP1_Volt_Stat 255 "Invalid";
VAL_ 596 EWP2_Volt_Stat 255 "Invalid";
VAL_ 596 EWP2_Temp_Stat 255 "Invalid";
VAL_ 596 EWP2_RPM_Target_Stat 255 "Invalid" 254 "max speed rpm" 253 "max speed rpm" 252 "max speed rpm" 251 "max speed rpm" 250 "linearly changed from min speed to max speed" 249 "linearly changed from min speed to max speed" 248 "linearly changed from min speed to max speed" 247 "linearly changed from min speed to max speed" 246 "linearly changed from min speed to max speed" 245 "linearly changed from min speed to max speed" 244 "linearly changed from min speed to max speed" 243 "linearly changed from min speed to max speed" 242 "linearly changed from min speed to max speed" 241 "linearly changed from min speed to max speed" 240 "linearly changed from min speed to max speed" 239 "linearly changed from min speed to max speed" 238 "linearly changed from min speed to max speed" 237 "linearly changed from min speed to max speed" 236 "linearly changed from min speed to max speed" 235 "linearly changed from min speed to max speed" 234 "linearly changed from min speed to max speed" 233 "linearly changed from min speed to max speed" 232 "linearly changed from min speed to max speed" 231 "linearly changed from min speed to max speed" 230 "linearly changed from min speed to max speed" 229 "linearly changed from min speed to max speed" 228 "linearly changed from min speed to max speed" 227 "linearly changed from min speed to max speed" 226 "linearly changed from min speed to max speed" 225 "linearly changed from min speed to max speed" 224 "linearly changed from min speed to max speed" 223 "linearly changed from min speed to max speed" 222 "linearly changed from min speed to max speed" 221 "linearly changed from min speed to max speed" 220 "linearly changed from min speed to max speed" 219 "linearly changed from min speed to max speed" 218 "linearly changed from min speed to max speed" 217 "linearly changed from min speed to max speed" 216 "linearly changed from min speed to max speed" 215 "linearly changed from min speed to max speed" 214 "linearly changed from min speed to max speed" 213 "linearly changed from min speed to max speed" 212 "linearly changed from min speed to max speed" 211 "linearly changed from min speed to max speed" 210 "linearly changed from min speed to max speed" 209 "linearly changed from min speed to max speed" 208 "linearly changed from min speed to max speed" 207 "linearly changed from min speed to max speed" 206 "linearly changed from min speed to max speed" 205 "linearly changed from min speed to max speed" 204 "linearly changed from min speed to max speed" 203 "linearly changed from min speed to max speed" 202 "linearly changed from min speed to max speed" 201 "linearly changed from min speed to max speed" 200 "linearly changed from min speed to max speed" 199 "linearly changed from min speed to max speed" 198 "linearly changed from min speed to max speed" 197 "linearly changed from min speed to max speed" 196 "linearly changed from min speed to max speed" 195 "linearly changed from min speed to max speed" 194 "linearly changed from min speed to max speed" 193 "linearly changed from min speed to max speed" 192 "linearly changed from min speed to max speed" 191 "linearly changed from min speed to max speed" 190 "linearly changed from min speed to max speed" 189 "linearly changed from min speed to max speed" 188 "linearly changed from min speed to max speed" 187 "linearly changed from min speed to max speed" 186 "linearly changed from min speed to max speed" 185 "linearly changed from min speed to max speed" 184 "linearly changed from min speed to max speed" 183 "linearly changed from min speed to max speed" 182 "linearly changed from min speed to max speed" 181 "linearly changed from min speed to max speed" 180 "linearly changed from min speed to max speed" 179 "linearly changed from min speed to max speed" 178 "linearly changed from min speed to max speed" 177 "linearly changed from min speed to max speed" 176 "linearly changed from min speed to max speed" 175 "linearly changed from min speed to max speed" 174 "linearly changed from min speed to max speed" 173 "linearly changed from min speed to max speed" 172 "linearly changed from min speed to max speed" 171 "linearly changed from min speed to max speed" 170 "linearly changed from min speed to max speed" 169 "linearly changed from min speed to max speed" 168 "linearly changed from min speed to max speed" 167 "linearly changed from min speed to max speed" 166 "linearly changed from min speed to max speed" 165 "linearly changed from min speed to max speed" 164 "linearly changed from min speed to max speed" 163 "linearly changed from min speed to max speed" 162 "linearly changed from min speed to max speed" 161 "linearly changed from min speed to max speed" 160 "linearly changed from min speed to max speed" 159 "linearly changed from min speed to max speed" 158 "linearly changed from min speed to max speed" 157 "linearly changed from min speed to max speed" 156 "linearly changed from min speed to max speed" 155 "linearly changed from min speed to max speed" 154 "linearly changed from min speed to max speed" 153 "linearly changed from min speed to max speed" 152 "linearly changed from min speed to max speed" 151 "linearly changed from min speed to max speed" 150 "linearly changed from min speed to max speed" 149 "linearly changed from min speed to max speed" 148 "linearly changed from min speed to max speed" 147 "linearly changed from min speed to max speed" 146 "linearly changed from min speed to max speed" 145 "linearly changed from min speed to max speed" 144 "linearly changed from min speed to max speed" 143 "linearly changed from min speed to max speed" 142 "linearly changed from min speed to max speed" 141 "linearly changed from min speed to max speed" 140 "linearly changed from min speed to max speed" 139 "linearly changed from min speed to max speed" 138 "linearly changed from min speed to max speed" 137 "linearly changed from min speed to max speed" 136 "linearly changed from min speed to max speed" 135 "linearly changed from min speed to max speed" 134 "linearly changed from min speed to max speed" 133 "linearly changed from min speed to max speed" 132 "linearly changed from min speed to max speed" 131 "linearly changed from min speed to max speed" 130 "linearly changed from min speed to max speed" 129 "linearly changed from min speed to max speed" 128 "linearly changed from min speed to max speed" 127 "linearly changed from min speed to max speed" 126 "linearly changed from min speed to max speed" 125 "linearly changed from min speed to max speed" 124 "linearly changed from min speed to max speed" 123 "linearly changed from min speed to max speed" 122 "linearly changed from min speed to max speed" 121 "linearly changed from min speed to max speed" 120 "linearly changed from min speed to max speed" 119 "linearly changed from min speed to max speed" 118 "linearly changed from min speed to max speed" 117 "linearly changed from min speed to max speed" 116 "linearly changed from min speed to max speed" 115 "linearly changed from min speed to max speed" 114 "linearly changed from min speed to max speed" 113 "linearly changed from min speed to max speed" 112 "linearly changed from min speed to max speed" 111 "linearly changed from min speed to max speed" 110 "linearly changed from min speed to max speed" 109 "linearly changed from min speed to max speed" 108 "linearly changed from min speed to max speed" 107 "linearly changed from min speed to max speed" 106 "linearly changed from min speed to max speed" 105 "linearly changed from min speed to max speed" 104 "linearly changed from min speed to max speed" 103 "linearly changed from min speed to max speed" 102 "linearly changed from min speed to max speed" 101 "linearly changed from min speed to max speed" 100 "linearly changed from min speed to max speed" 99 "linearly changed from min speed to max speed" 98 "linearly changed from min speed to max speed" 97 "linearly changed from min speed to max speed" 96 "linearly changed from min speed to max speed" 95 "linearly changed from min speed to max speed" 94 "linearly changed from min speed to max speed" 93 "linearly changed from min speed to max speed" 92 "linearly changed from min speed to max speed" 91 "linearly changed from min speed to max speed" 90 "linearly changed from min speed to max speed" 89 "linearly changed from min speed to max speed" 88 "linearly changed from min speed to max speed" 87 "linearly changed from min speed to max speed" 86 "linearly changed from min speed to max speed" 85 "linearly changed from min speed to max speed" 84 "linearly changed from min speed to max speed" 83 "linearly changed from min speed to max speed" 82 "linearly changed from min speed to max speed" 81 "linearly changed from min speed to max speed" 80 "linearly changed from min speed to max speed" 79 "linearly changed from min speed to max speed" 78 "linearly changed from min speed to max speed" 77 "linearly changed from min speed to max speed" 76 "linearly changed from min speed to max speed" 75 "linearly changed from min speed to max speed" 74 "linearly changed from min speed to max speed" 73 "linearly changed from min speed to max speed" 72 "linearly changed from min speed to max speed" 71 "linearly changed from min speed to max speed" 70 "linearly changed from min speed to max speed" 69 "linearly changed from min speed to max speed" 68 "linearly changed from min speed to max speed" 67 "linearly changed from min speed to max speed" 66 "linearly changed from min speed to max speed" 65 "linearly changed from min speed to max speed" 64 "linearly changed from min speed to max speed" 63 "linearly changed from min speed to max speed" 62 "linearly changed from min speed to max speed" 61 "linearly changed from min speed to max speed" 60 "linearly changed from min speed to max speed" 59 "linearly changed from min speed to max speed" 58 "linearly changed from min speed to max speed" 57 "linearly changed from min speed to max speed" 56 "linearly changed from min speed to max speed" 55 "linearly changed from min speed to max speed" 54 "linearly changed from min speed to max speed" 53 "linearly changed from min speed to max speed" 52 "linearly changed from min speed to max speed" 51 "linearly changed from min speed to max speed" 50 "linearly changed from min speed to max speed" 49 "min speed rpm" 48 "min speed rpm" 47 "min speed rpm" 46 "min speed rpm" 45 "min speed rpm" 44 "min speed rpm" 43 "min speed rpm" 42 "min speed rpm" 41 "min speed rpm" 40 "min speed rpm" 39 "min speed rpm" 38 "min speed rpm" 37 "min speed rpm" 36 "min speed rpm" 35 "min speed rpm" 34 "min speed rpm" 33 "min speed rpm" 32 "min speed rpm" 31 "min speed rpm" 30 "min speed rpm" 29 "min speed rpm" 28 "min speed rpm" 27 "min speed rpm" 26 "min speed rpm" 25 "min speed rpm" 24 "min speed rpm" 23 "min speed rpm" 22 "min speed rpm" 21 "min speed rpm" 20 "min speed rpm" 19 "min speed rpm" 18 "min speed rpm" 17 "min speed rpm" 16 "min speed rpm" 15 "min speed rpm" 14 "min speed rpm" 13 "min speed rpm" 12 "min speed rpm" 11 "min speed rpm" 10 "min speed rpm" 9 "min speed rpm" 8 "min speed rpm" 7 "min speed rpm" 6 "min speed rpm" 5 "min speed rpm" 4 "min speed rpm" 3 "0 rpm" 2 "0 rpm" 1 "0 rpm" 0 "0 rpm";
VAL_ 596 EWP2_RPM_ActlVal_Stat 255 "Invalid" 254 "max speed rpm" 253 "max speed rpm" 252 "max speed rpm" 251 "max speed rpm" 250 "linearly changed from min speed to max speed" 249 "linearly changed from min speed to max speed" 248 "linearly changed from min speed to max speed" 247 "linearly changed from min speed to max speed" 246 "linearly changed from min speed to max speed" 245 "linearly changed from min speed to max speed" 244 "linearly changed from min speed to max speed" 243 "linearly changed from min speed to max speed" 242 "linearly changed from min speed to max speed" 241 "linearly changed from min speed to max speed" 240 "linearly changed from min speed to max speed" 239 "linearly changed from min speed to max speed" 238 "linearly changed from min speed to max speed" 237 "linearly changed from min speed to max speed" 236 "linearly changed from min speed to max speed" 235 "linearly changed from min speed to max speed" 234 "linearly changed from min speed to max speed" 233 "linearly changed from min speed to max speed" 232 "linearly changed from min speed to max speed" 231 "linearly changed from min speed to max speed" 230 "linearly changed from min speed to max speed" 229 "linearly changed from min speed to max speed" 228 "linearly changed from min speed to max speed" 227 "linearly changed from min speed to max speed" 226 "linearly changed from min speed to max speed" 225 "linearly changed from min speed to max speed" 224 "linearly changed from min speed to max speed" 223 "linearly changed from min speed to max speed" 222 "linearly changed from min speed to max speed" 221 "linearly changed from min speed to max speed" 220 "linearly changed from min speed to max speed" 219 "linearly changed from min speed to max speed" 218 "linearly changed from min speed to max speed" 217 "linearly changed from min speed to max speed" 216 "linearly changed from min speed to max speed" 215 "linearly changed from min speed to max speed" 214 "linearly changed from min speed to max speed" 213 "linearly changed from min speed to max speed" 212 "linearly changed from min speed to max speed" 211 "linearly changed from min speed to max speed" 210 "linearly changed from min speed to max speed" 209 "linearly changed from min speed to max speed" 208 "linearly changed from min speed to max speed" 207 "linearly changed from min speed to max speed" 206 "linearly changed from min speed to max speed" 205 "linearly changed from min speed to max speed" 204 "linearly changed from min speed to max speed" 203 "linearly changed from min speed to max speed" 202 "linearly changed from min speed to max speed" 201 "linearly changed from min speed to max speed" 200 "linearly changed from min speed to max speed" 199 "linearly changed from min speed to max speed" 198 "linearly changed from min speed to max speed" 197 "linearly changed from min speed to max speed" 196 "linearly changed from min speed to max speed" 195 "linearly changed from min speed to max speed" 194 "linearly changed from min speed to max speed" 193 "linearly changed from min speed to max speed" 192 "linearly changed from min speed to max speed" 191 "linearly changed from min speed to max speed" 190 "linearly changed from min speed to max speed" 189 "linearly changed from min speed to max speed" 188 "linearly changed from min speed to max speed" 187 "linearly changed from min speed to max speed" 186 "linearly changed from min speed to max speed" 185 "linearly changed from min speed to max speed" 184 "linearly changed from min speed to max speed" 183 "linearly changed from min speed to max speed" 182 "linearly changed from min speed to max speed" 181 "linearly changed from min speed to max speed" 180 "linearly changed from min speed to max speed" 179 "linearly changed from min speed to max speed" 178 "linearly changed from min speed to max speed" 177 "linearly changed from min speed to max speed" 176 "linearly changed from min speed to max speed" 175 "linearly changed from min speed to max speed" 174 "linearly changed from min speed to max speed" 173 "linearly changed from min speed to max speed" 172 "linearly changed from min speed to max speed" 171 "linearly changed from min speed to max speed" 170 "linearly changed from min speed to max speed" 169 "linearly changed from min speed to max speed" 168 "linearly changed from min speed to max speed" 167 "linearly changed from min speed to max speed" 166 "linearly changed from min speed to max speed" 165 "linearly changed from min speed to max speed" 164 "linearly changed from min speed to max speed" 163 "linearly changed from min speed to max speed" 162 "linearly changed from min speed to max speed" 161 "linearly changed from min speed to max speed" 160 "linearly changed from min speed to max speed" 159 "linearly changed from min speed to max speed" 158 "linearly changed from min speed to max speed" 157 "linearly changed from min speed to max speed" 156 "linearly changed from min speed to max speed" 155 "linearly changed from min speed to max speed" 154 "linearly changed from min speed to max speed" 153 "linearly changed from min speed to max speed" 152 "linearly changed from min speed to max speed" 151 "linearly changed from min speed to max speed" 150 "linearly changed from min speed to max speed" 149 "linearly changed from min speed to max speed" 148 "linearly changed from min speed to max speed" 147 "linearly changed from min speed to max speed" 146 "linearly changed from min speed to max speed" 145 "linearly changed from min speed to max speed" 144 "linearly changed from min speed to max speed" 143 "linearly changed from min speed to max speed" 142 "linearly changed from min speed to max speed" 141 "linearly changed from min speed to max speed" 140 "linearly changed from min speed to max speed" 139 "linearly changed from min speed to max speed" 138 "linearly changed from min speed to max speed" 137 "linearly changed from min speed to max speed" 136 "linearly changed from min speed to max speed" 135 "linearly changed from min speed to max speed" 134 "linearly changed from min speed to max speed" 133 "linearly changed from min speed to max speed" 132 "linearly changed from min speed to max speed" 131 "linearly changed from min speed to max speed" 130 "linearly changed from min speed to max speed" 129 "linearly changed from min speed to max speed" 128 "linearly changed from min speed to max speed" 127 "linearly changed from min speed to max speed" 126 "linearly changed from min speed to max speed" 125 "linearly changed from min speed to max speed" 124 "linearly changed from min speed to max speed" 123 "linearly changed from min speed to max speed" 122 "linearly changed from min speed to max speed" 121 "linearly changed from min speed to max speed" 120 "linearly changed from min speed to max speed" 119 "linearly changed from min speed to max speed" 118 "linearly changed from min speed to max speed" 117 "linearly changed from min speed to max speed" 116 "linearly changed from min speed to max speed" 115 "linearly changed from min speed to max speed" 114 "linearly changed from min speed to max speed" 113 "linearly changed from min speed to max speed" 112 "linearly changed from min speed to max speed" 111 "linearly changed from min speed to max speed" 110 "linearly changed from min speed to max speed" 109 "linearly changed from min speed to max speed" 108 "linearly changed from min speed to max speed" 107 "linearly changed from min speed to max speed" 106 "linearly changed from min speed to max speed" 105 "linearly changed from min speed to max speed" 104 "linearly changed from min speed to max speed" 103 "linearly changed from min speed to max speed" 102 "linearly changed from min speed to max speed" 101 "linearly changed from min speed to max speed" 100 "linearly changed from min speed to max speed" 99 "linearly changed from min speed to max speed" 98 "linearly changed from min speed to max speed" 97 "linearly changed from min speed to max speed" 96 "linearly changed from min speed to max speed" 95 "linearly changed from min speed to max speed" 94 "linearly changed from min speed to max speed" 93 "linearly changed from min speed to max speed" 92 "linearly changed from min speed to max speed" 91 "linearly changed from min speed to max speed" 90 "linearly changed from min speed to max speed" 89 "linearly changed from min speed to max speed" 88 "linearly changed from min speed to max speed" 87 "linearly changed from min speed to max speed" 86 "linearly changed from min speed to max speed" 85 "linearly changed from min speed to max speed" 84 "linearly changed from min speed to max speed" 83 "linearly changed from min speed to max speed" 82 "linearly changed from min speed to max speed" 81 "linearly changed from min speed to max speed" 80 "linearly changed from min speed to max speed" 79 "linearly changed from min speed to max speed" 78 "linearly changed from min speed to max speed" 77 "linearly changed from min speed to max speed" 76 "linearly changed from min speed to max speed" 75 "linearly changed from min speed to max speed" 74 "linearly changed from min speed to max speed" 73 "linearly changed from min speed to max speed" 72 "linearly changed from min speed to max speed" 71 "linearly changed from min speed to max speed" 70 "linearly changed from min speed to max speed" 69 "linearly changed from min speed to max speed" 68 "linearly changed from min speed to max speed" 67 "linearly changed from min speed to max speed" 66 "linearly changed from min speed to max speed" 65 "linearly changed from min speed to max speed" 64 "linearly changed from min speed to max speed" 63 "linearly changed from min speed to max speed" 62 "linearly changed from min speed to max speed" 61 "linearly changed from min speed to max speed" 60 "linearly changed from min speed to max speed" 59 "linearly changed from min speed to max speed" 58 "linearly changed from min speed to max speed" 57 "linearly changed from min speed to max speed" 56 "linearly changed from min speed to max speed" 55 "linearly changed from min speed to max speed" 54 "linearly changed from min speed to max speed" 53 "linearly changed from min speed to max speed" 52 "linearly changed from min speed to max speed" 51 "linearly changed from min speed to max speed" 50 "linearly changed from min speed to max speed" 49 "min speed rpm" 48 "min speed rpm" 47 "min speed rpm" 46 "min speed rpm" 45 "min speed rpm" 44 "min speed rpm" 43 "min speed rpm" 42 "min speed rpm" 41 "min speed rpm" 40 "min speed rpm" 39 "min speed rpm" 38 "min speed rpm" 37 "min speed rpm" 36 "min speed rpm" 35 "min speed rpm" 34 "min speed rpm" 33 "min speed rpm" 32 "min speed rpm" 31 "min speed rpm" 30 "min speed rpm" 29 "min speed rpm" 28 "min speed rpm" 27 "min speed rpm" 26 "min speed rpm" 25 "min speed rpm" 24 "min speed rpm" 23 "min speed rpm" 22 "min speed rpm" 21 "min speed rpm" 20 "min speed rpm" 19 "min speed rpm" 18 "min speed rpm" 17 "min speed rpm" 16 "min speed rpm" 15 "min speed rpm" 14 "min speed rpm" 13 "min speed rpm" 12 "min speed rpm" 11 "min speed rpm" 10 "min speed rpm" 9 "min speed rpm" 8 "min speed rpm" 7 "min speed rpm" 6 "min speed rpm" 5 "min speed rpm" 4 "min speed rpm" 3 "0 rpm" 2 "0 rpm" 1 "0 rpm" 0 "0 rpm";
VAL_ 596 EWP2_Curr_Stat 255 "Invalid";
VAL_ 596 EWP2_Block_Error 2 "SNA" 1 "ERROR" 0 "NO ERROR";
VAL_ 596 EWP2_DryRun_Error 2 "SNA" 1 "ERROR" 0 "NO ERROR";
VAL_ 596 EWP2_OverCurr_Error 2 "SNA" 1 "ERROR" 0 "NO ERROR";
VAL_ 596 EWP2_SupVolt_Error 2 "SNA" 1 "ERROR" 0 "NO ERROR";
VAL_ 596 EWP2_RsErr_EWP 1 "ERROR" 0 "NO ERROR";
VAL_ 596 EWP3_Block_Error 2 "SNA" 1 "ERROR" 0 "NO ERROR";
VAL_ 596 EWP3_DryRun_Error 2 "SNA" 1 "ERROR" 0 "NO ERROR";
VAL_ 596 EWP3_RPM_Target_Stat 255 "Invalid" 254 "max speed rpm" 253 "max speed rpm" 252 "max speed rpm" 251 "max speed rpm" 250 "linearly changed from min speed to max speed" 249 "linearly changed from min speed to max speed" 248 "linearly changed from min speed to max speed" 247 "linearly changed from min speed to max speed" 246 "linearly changed from min speed to max speed" 245 "linearly changed from min speed to max speed" 244 "linearly changed from min speed to max speed" 243 "linearly changed from min speed to max speed" 242 "linearly changed from min speed to max speed" 241 "linearly changed from min speed to max speed" 240 "linearly changed from min speed to max speed" 239 "linearly changed from min speed to max speed" 238 "linearly changed from min speed to max speed" 237 "linearly changed from min speed to max speed" 236 "linearly changed from min speed to max speed" 235 "linearly changed from min speed to max speed" 234 "linearly changed from min speed to max speed" 233 "linearly changed from min speed to max speed" 232 "linearly changed from min speed to max speed" 231 "linearly changed from min speed to max speed" 230 "linearly changed from min speed to max speed" 229 "linearly changed from min speed to max speed" 228 "linearly changed from min speed to max speed" 227 "linearly changed from min speed to max speed" 226 "linearly changed from min speed to max speed" 225 "linearly changed from min speed to max speed" 224 "linearly changed from min speed to max speed" 223 "linearly changed from min speed to max speed" 222 "linearly changed from min speed to max speed" 221 "linearly changed from min speed to max speed" 220 "linearly changed from min speed to max speed" 219 "linearly changed from min speed to max speed" 218 "linearly changed from min speed to max speed" 217 "linearly changed from min speed to max speed" 216 "linearly changed from min speed to max speed" 215 "linearly changed from min speed to max speed" 214 "linearly changed from min speed to max speed" 213 "linearly changed from min speed to max speed" 212 "linearly changed from min speed to max speed" 211 "linearly changed from min speed to max speed" 210 "linearly changed from min speed to max speed" 209 "linearly changed from min speed to max speed" 208 "linearly changed from min speed to max speed" 207 "linearly changed from min speed to max speed" 206 "linearly changed from min speed to max speed" 205 "linearly changed from min speed to max speed" 204 "linearly changed from min speed to max speed" 203 "linearly changed from min speed to max speed" 202 "linearly changed from min speed to max speed" 201 "linearly changed from min speed to max speed" 200 "linearly changed from min speed to max speed" 199 "linearly changed from min speed to max speed" 198 "linearly changed from min speed to max speed" 197 "linearly changed from min speed to max speed" 196 "linearly changed from min speed to max speed" 195 "linearly changed from min speed to max speed" 194 "linearly changed from min speed to max speed" 193 "linearly changed from min speed to max speed" 192 "linearly changed from min speed to max speed" 191 "linearly changed from min speed to max speed" 190 "linearly changed from min speed to max speed" 189 "linearly changed from min speed to max speed" 188 "linearly changed from min speed to max speed" 187 "linearly changed from min speed to max speed" 186 "linearly changed from min speed to max speed" 185 "linearly changed from min speed to max speed" 184 "linearly changed from min speed to max speed" 183 "linearly changed from min speed to max speed" 182 "linearly changed from min speed to max speed" 181 "linearly changed from min speed to max speed" 180 "linearly changed from min speed to max speed" 179 "linearly changed from min speed to max speed" 178 "linearly changed from min speed to max speed" 177 "linearly changed from min speed to max speed" 176 "linearly changed from min speed to max speed" 175 "linearly changed from min speed to max speed" 174 "linearly changed from min speed to max speed" 173 "linearly changed from min speed to max speed" 172 "linearly changed from min speed to max speed" 171 "linearly changed from min speed to max speed" 170 "linearly changed from min speed to max speed" 169 "linearly changed from min speed to max speed" 168 "linearly changed from min speed to max speed" 167 "linearly changed from min speed to max speed" 166 "linearly changed from min speed to max speed" 165 "linearly changed from min speed to max speed" 164 "linearly changed from min speed to max speed" 163 "linearly changed from min speed to max speed" 162 "linearly changed from min speed to max speed" 161 "linearly changed from min speed to max speed" 160 "linearly changed from min speed to max speed" 159 "linearly changed from min speed to max speed" 158 "linearly changed from min speed to max speed" 157 "linearly changed from min speed to max speed" 156 "linearly changed from min speed to max speed" 155 "linearly changed from min speed to max speed" 154 "linearly changed from min speed to max speed" 153 "linearly changed from min speed to max speed" 152 "linearly changed from min speed to max speed" 151 "linearly changed from min speed to max speed" 150 "linearly changed from min speed to max speed" 149 "linearly changed from min speed to max speed" 148 "linearly changed from min speed to max speed" 147 "linearly changed from min speed to max speed" 146 "linearly changed from min speed to max speed" 145 "linearly changed from min speed to max speed" 144 "linearly changed from min speed to max speed" 143 "linearly changed from min speed to max speed" 142 "linearly changed from min speed to max speed" 141 "linearly changed from min speed to max speed" 140 "linearly changed from min speed to max speed" 139 "linearly changed from min speed to max speed" 138 "linearly changed from min speed to max speed" 137 "linearly changed from min speed to max speed" 136 "linearly changed from min speed to max speed" 135 "linearly changed from min speed to max speed" 134 "linearly changed from min speed to max speed" 133 "linearly changed from min speed to max speed" 132 "linearly changed from min speed to max speed" 131 "linearly changed from min speed to max speed" 130 "linearly changed from min speed to max speed" 129 "linearly changed from min speed to max speed" 128 "linearly changed from min speed to max speed" 127 "linearly changed from min speed to max speed" 126 "linearly changed from min speed to max speed" 125 "linearly changed from min speed to max speed" 124 "linearly changed from min speed to max speed" 123 "linearly changed from min speed to max speed" 122 "linearly changed from min speed to max speed" 121 "linearly changed from min speed to max speed" 120 "linearly changed from min speed to max speed" 119 "linearly changed from min speed to max speed" 118 "linearly changed from min speed to max speed" 117 "linearly changed from min speed to max speed" 116 "linearly changed from min speed to max speed" 115 "linearly changed from min speed to max speed" 114 "linearly changed from min speed to max speed" 113 "linearly changed from min speed to max speed" 112 "linearly changed from min speed to max speed" 111 "linearly changed from min speed to max speed" 110 "linearly changed from min speed to max speed" 109 "linearly changed from min speed to max speed" 108 "linearly changed from min speed to max speed" 107 "linearly changed from min speed to max speed" 106 "linearly changed from min speed to max speed" 105 "linearly changed from min speed to max speed" 104 "linearly changed from min speed to max speed" 103 "linearly changed from min speed to max speed" 102 "linearly changed from min speed to max speed" 101 "linearly changed from min speed to max speed" 100 "linearly changed from min speed to max speed" 99 "linearly changed from min speed to max speed" 98 "linearly changed from min speed to max speed" 97 "linearly changed from min speed to max speed" 96 "linearly changed from min speed to max speed" 95 "linearly changed from min speed to max speed" 94 "linearly changed from min speed to max speed" 93 "linearly changed from min speed to max speed" 92 "linearly changed from min speed to max speed" 91 "linearly changed from min speed to max speed" 90 "linearly changed from min speed to max speed" 89 "linearly changed from min speed to max speed" 88 "linearly changed from min speed to max speed" 87 "linearly changed from min speed to max speed" 86 "linearly changed from min speed to max speed" 85 "linearly changed from min speed to max speed" 84 "linearly changed from min speed to max speed" 83 "linearly changed from min speed to max speed" 82 "linearly changed from min speed to max speed" 81 "linearly changed from min speed to max speed" 80 "linearly changed from min speed to max speed" 79 "linearly changed from min speed to max speed" 78 "linearly changed from min speed to max speed" 77 "linearly changed from min speed to max speed" 76 "linearly changed from min speed to max speed" 75 "linearly changed from min speed to max speed" 74 "linearly changed from min speed to max speed" 73 "linearly changed from min speed to max speed" 72 "linearly changed from min speed to max speed" 71 "linearly changed from min speed to max speed" 70 "linearly changed from min speed to max speed" 69 "linearly changed from min speed to max speed" 68 "linearly changed from min speed to max speed" 67 "linearly changed from min speed to max speed" 66 "linearly changed from min speed to max speed" 65 "linearly changed from min speed to max speed" 64 "linearly changed from min speed to max speed" 63 "linearly changed from min speed to max speed" 62 "linearly changed from min speed to max speed" 61 "linearly changed from min speed to max speed" 60 "linearly changed from min speed to max speed" 59 "linearly changed from min speed to max speed" 58 "linearly changed from min speed to max speed" 57 "linearly changed from min speed to max speed" 56 "linearly changed from min speed to max speed" 55 "linearly changed from min speed to max speed" 54 "linearly changed from min speed to max speed" 53 "linearly changed from min speed to max speed" 52 "linearly changed from min speed to max speed" 51 "linearly changed from min speed to max speed" 50 "linearly changed from min speed to max speed" 49 "min speed rpm" 48 "min speed rpm" 47 "min speed rpm" 46 "min speed rpm" 45 "min speed rpm" 44 "min speed rpm" 43 "min speed rpm" 42 "min speed rpm" 41 "min speed rpm" 40 "min speed rpm" 39 "min speed rpm" 38 "min speed rpm" 37 "min speed rpm" 36 "min speed rpm" 35 "min speed rpm" 34 "min speed rpm" 33 "min speed rpm" 32 "min speed rpm" 31 "min speed rpm" 30 "min speed rpm" 29 "min speed rpm" 28 "min speed rpm" 27 "min speed rpm" 26 "min speed rpm" 25 "min speed rpm" 24 "min speed rpm" 23 "min speed rpm" 22 "min speed rpm" 21 "min speed rpm" 20 "min speed rpm" 19 "min speed rpm" 18 "min speed rpm" 17 "min speed rpm" 16 "min speed rpm" 15 "min speed rpm" 14 "min speed rpm" 13 "min speed rpm" 12 "min speed rpm" 11 "min speed rpm" 10 "min speed rpm" 9 "min speed rpm" 8 "min speed rpm" 7 "min speed rpm" 6 "min speed rpm" 5 "min speed rpm" 4 "min speed rpm" 3 "0 rpm" 2 "0 rpm" 1 "0 rpm" 0 "0 rpm";
VAL_ 596 EWP3_RPM_ActlVal_Stat 255 "Invalid" 254 "max speed rpm" 253 "max speed rpm" 252 "max speed rpm" 251 "max speed rpm" 250 "linearly changed from min speed to max speed" 249 "linearly changed from min speed to max speed" 248 "linearly changed from min speed to max speed" 247 "linearly changed from min speed to max speed" 246 "linearly changed from min speed to max speed" 245 "linearly changed from min speed to max speed" 244 "linearly changed from min speed to max speed" 243 "linearly changed from min speed to max speed" 242 "linearly changed from min speed to max speed" 241 "linearly changed from min speed to max speed" 240 "linearly changed from min speed to max speed" 239 "linearly changed from min speed to max speed" 238 "linearly changed from min speed to max speed" 237 "linearly changed from min speed to max speed" 236 "linearly changed from min speed to max speed" 235 "linearly changed from min speed to max speed" 234 "linearly changed from min speed to max speed" 233 "linearly changed from min speed to max speed" 232 "linearly changed from min speed to max speed" 231 "linearly changed from min speed to max speed" 230 "linearly changed from min speed to max speed" 229 "linearly changed from min speed to max speed" 228 "linearly changed from min speed to max speed" 227 "linearly changed from min speed to max speed" 226 "linearly changed from min speed to max speed" 225 "linearly changed from min speed to max speed" 224 "linearly changed from min speed to max speed" 223 "linearly changed from min speed to max speed" 222 "linearly changed from min speed to max speed" 221 "linearly changed from min speed to max speed" 220 "linearly changed from min speed to max speed" 219 "linearly changed from min speed to max speed" 218 "linearly changed from min speed to max speed" 217 "linearly changed from min speed to max speed" 216 "linearly changed from min speed to max speed" 215 "linearly changed from min speed to max speed" 214 "linearly changed from min speed to max speed" 213 "linearly changed from min speed to max speed" 212 "linearly changed from min speed to max speed" 211 "linearly changed from min speed to max speed" 210 "linearly changed from min speed to max speed" 209 "linearly changed from min speed to max speed" 208 "linearly changed from min speed to max speed" 207 "linearly changed from min speed to max speed" 206 "linearly changed from min speed to max speed" 205 "linearly changed from min speed to max speed" 204 "linearly changed from min speed to max speed" 203 "linearly changed from min speed to max speed" 202 "linearly changed from min speed to max speed" 201 "linearly changed from min speed to max speed" 200 "linearly changed from min speed to max speed" 199 "linearly changed from min speed to max speed" 198 "linearly changed from min speed to max speed" 197 "linearly changed from min speed to max speed" 196 "linearly changed from min speed to max speed" 195 "linearly changed from min speed to max speed" 194 "linearly changed from min speed to max speed" 193 "linearly changed from min speed to max speed" 192 "linearly changed from min speed to max speed" 191 "linearly changed from min speed to max speed" 190 "linearly changed from min speed to max speed" 189 "linearly changed from min speed to max speed" 188 "linearly changed from min speed to max speed" 187 "linearly changed from min speed to max speed" 186 "linearly changed from min speed to max speed" 185 "linearly changed from min speed to max speed" 184 "linearly changed from min speed to max speed" 183 "linearly changed from min speed to max speed" 182 "linearly changed from min speed to max speed" 181 "linearly changed from min speed to max speed" 180 "linearly changed from min speed to max speed" 179 "linearly changed from min speed to max speed" 178 "linearly changed from min speed to max speed" 177 "linearly changed from min speed to max speed" 176 "linearly changed from min speed to max speed" 175 "linearly changed from min speed to max speed" 174 "linearly changed from min speed to max speed" 173 "linearly changed from min speed to max speed" 172 "linearly changed from min speed to max speed" 171 "linearly changed from min speed to max speed" 170 "linearly changed from min speed to max speed" 169 "linearly changed from min speed to max speed" 168 "linearly changed from min speed to max speed" 167 "linearly changed from min speed to max speed" 166 "linearly changed from min speed to max speed" 165 "linearly changed from min speed to max speed" 164 "linearly changed from min speed to max speed" 163 "linearly changed from min speed to max speed" 162 "linearly changed from min speed to max speed" 161 "linearly changed from min speed to max speed" 160 "linearly changed from min speed to max speed" 159 "linearly changed from min speed to max speed" 158 "linearly changed from min speed to max speed" 157 "linearly changed from min speed to max speed" 156 "linearly changed from min speed to max speed" 155 "linearly changed from min speed to max speed" 154 "linearly changed from min speed to max speed" 153 "linearly changed from min speed to max speed" 152 "linearly changed from min speed to max speed" 151 "linearly changed from min speed to max speed" 150 "linearly changed from min speed to max speed" 149 "linearly changed from min speed to max speed" 148 "linearly changed from min speed to max speed" 147 "linearly changed from min speed to max speed" 146 "linearly changed from min speed to max speed" 145 "linearly changed from min speed to max speed" 144 "linearly changed from min speed to max speed" 143 "linearly changed from min speed to max speed" 142 "linearly changed from min speed to max speed" 141 "linearly changed from min speed to max speed" 140 "linearly changed from min speed to max speed" 139 "linearly changed from min speed to max speed" 138 "linearly changed from min speed to max speed" 137 "linearly changed from min speed to max speed" 136 "linearly changed from min speed to max speed" 135 "linearly changed from min speed to max speed" 134 "linearly changed from min speed to max speed" 133 "linearly changed from min speed to max speed" 132 "linearly changed from min speed to max speed" 131 "linearly changed from min speed to max speed" 130 "linearly changed from min speed to max speed" 129 "linearly changed from min speed to max speed" 128 "linearly changed from min speed to max speed" 127 "linearly changed from min speed to max speed" 126 "linearly changed from min speed to max speed" 125 "linearly changed from min speed to max speed" 124 "linearly changed from min speed to max speed" 123 "linearly changed from min speed to max speed" 122 "linearly changed from min speed to max speed" 121 "linearly changed from min speed to max speed" 120 "linearly changed from min speed to max speed" 119 "linearly changed from min speed to max speed" 118 "linearly changed from min speed to max speed" 117 "linearly changed from min speed to max speed" 116 "linearly changed from min speed to max speed" 115 "linearly changed from min speed to max speed" 114 "linearly changed from min speed to max speed" 113 "linearly changed from min speed to max speed" 112 "linearly changed from min speed to max speed" 111 "linearly changed from min speed to max speed" 110 "linearly changed from min speed to max speed" 109 "linearly changed from min speed to max speed" 108 "linearly changed from min speed to max speed" 107 "linearly changed from min speed to max speed" 106 "linearly changed from min speed to max speed" 105 "linearly changed from min speed to max speed" 104 "linearly changed from min speed to max speed" 103 "linearly changed from min speed to max speed" 102 "linearly changed from min speed to max speed" 101 "linearly changed from min speed to max speed" 100 "linearly changed from min speed to max speed" 99 "linearly changed from min speed to max speed" 98 "linearly changed from min speed to max speed" 97 "linearly changed from min speed to max speed" 96 "linearly changed from min speed to max speed" 95 "linearly changed from min speed to max speed" 94 "linearly changed from min speed to max speed" 93 "linearly changed from min speed to max speed" 92 "linearly changed from min speed to max speed" 91 "linearly changed from min speed to max speed" 90 "linearly changed from min speed to max speed" 89 "linearly changed from min speed to max speed" 88 "linearly changed from min speed to max speed" 87 "linearly changed from min speed to max speed" 86 "linearly changed from min speed to max speed" 85 "linearly changed from min speed to max speed" 84 "linearly changed from min speed to max speed" 83 "linearly changed from min speed to max speed" 82 "linearly changed from min speed to max speed" 81 "linearly changed from min speed to max speed" 80 "linearly changed from min speed to max speed" 79 "linearly changed from min speed to max speed" 78 "linearly changed from min speed to max speed" 77 "linearly changed from min speed to max speed" 76 "linearly changed from min speed to max speed" 75 "linearly changed from min speed to max speed" 74 "linearly changed from min speed to max speed" 73 "linearly changed from min speed to max speed" 72 "linearly changed from min speed to max speed" 71 "linearly changed from min speed to max speed" 70 "linearly changed from min speed to max speed" 69 "linearly changed from min speed to max speed" 68 "linearly changed from min speed to max speed" 67 "linearly changed from min speed to max speed" 66 "linearly changed from min speed to max speed" 65 "linearly changed from min speed to max speed" 64 "linearly changed from min speed to max speed" 63 "linearly changed from min speed to max speed" 62 "linearly changed from min speed to max speed" 61 "linearly changed from min speed to max speed" 60 "linearly changed from min speed to max speed" 59 "linearly changed from min speed to max speed" 58 "linearly changed from min speed to max speed" 57 "linearly changed from min speed to max speed" 56 "linearly changed from min speed to max speed" 55 "linearly changed from min speed to max speed" 54 "linearly changed from min speed to max speed" 53 "linearly changed from min speed to max speed" 52 "linearly changed from min speed to max speed" 51 "linearly changed from min speed to max speed" 50 "linearly changed from min speed to max speed" 49 "min speed rpm" 48 "min speed rpm" 47 "min speed rpm" 46 "min speed rpm" 45 "min speed rpm" 44 "min speed rpm" 43 "min speed rpm" 42 "min speed rpm" 41 "min speed rpm" 40 "min speed rpm" 39 "min speed rpm" 38 "min speed rpm" 37 "min speed rpm" 36 "min speed rpm" 35 "min speed rpm" 34 "min speed rpm" 33 "min speed rpm" 32 "min speed rpm" 31 "min speed rpm" 30 "min speed rpm" 29 "min speed rpm" 28 "min speed rpm" 27 "min speed rpm" 26 "min speed rpm" 25 "min speed rpm" 24 "min speed rpm" 23 "min speed rpm" 22 "min speed rpm" 21 "min speed rpm" 20 "min speed rpm" 19 "min speed rpm" 18 "min speed rpm" 17 "min speed rpm" 16 "min speed rpm" 15 "min speed rpm" 14 "min speed rpm" 13 "min speed rpm" 12 "min speed rpm" 11 "min speed rpm" 10 "min speed rpm" 9 "min speed rpm" 8 "min speed rpm" 7 "min speed rpm" 6 "min speed rpm" 5 "min speed rpm" 4 "min speed rpm" 3 "0 rpm" 2 "0 rpm" 1 "0 rpm" 0 "0 rpm";
VAL_ 596 EWP3_Curr_Stat 255 "invalid";
VAL_ 596 EWP3_SupVolt_Error 2 "SNA" 1 "ERROR" 0 "NO ERROR";
VAL_ 596 EWP3_RsErr_EWP 1 "ERROR" 0 "NO ERROR";
VAL_ 596 EWP3_Temp_Stat 255 "Invalid";
VAL_ 596 EWP3_Volt_Stat 255 "Invalid";
VAL_ 596 EXV2_Rsp_Fault_Stat 15 "not defined" 14 "not defined" 13 "not defined" 12 "not defined" 11 "not defined" 10 "not defined" 9 "not defined" 8 "not defined" 7 "not defined" 6 "not defined" 5 "not defined" 4 "not defined" 3 "Over temperature shutdown" 2 "Motor-Coil open load" 1 "Motor-Coil shorted" 0 "Actuator Not Faulted";
VAL_ 596 EXV2_Rsp_CurInit_Stat 3 "Unused and Undefined" 2 "Initialized" 1 "Initialization in Process" 0 "Not Initialized";
VAL_ 596 EXV2_Rsp_OvrTemp_Warn 3 "not defined" 2 "not defined" 1 "High Temperature Warning" 0 "Ok";
VAL_ 596 EXV2_Rsp_Volt_Stat 3 "not defined" 2 "Under voltage" 1 "Overvoltage" 0 "Voltage Range ok";
VAL_ 596 EXV2_RsErr_EXV 1 "Comm Error detected" 0 "No Comm Error";
VAL_ 596 EXV2_Rsp_Run_Stat 1 "Actuator is moving" 0 "Actuator is not moving";
VAL_ 596 CCV4_Fault_Signal 4 "Coil Short Detected" 3 "OverTemp Shutdown" 2 "Stall Detected" 1 "Coil_Open Detected" 0 "No Fault";
VAL_ 596 BDC_1_Rsp_Comm_Err 1 "LIN Communication Error" 0 "No Error";
VAL_ 596 CCV4_TempWarn 1 "Temperature Warning" 0 "No Error";
VAL_ 596 CCV4_Rsp_Comm_Err 1 "LIN Communication Error" 0 "No Error";
VAL_ 596 CCV4_MotorStatus 1 "Motor Running" 0 "Motor Stop";
VAL_ 596 CCV4_RespPos 3 "Valve is opening" 2 "Valve is closing" 1 "Open Port 1 to Port 4, Port 2 to port 3" 0 "Open Port 1 to Port 2, Port 3 to port 4";
VAL_ 596 CCV4_voltageErr 2 "lackvoltage" 1 "overvoltage" 0 "No Error";
VAL_ 596 BDC_1_Fault_Signal 4 "Coil Short Detected" 3 "OverTemp Shutdown" 2 "Stall Detected" 1 "Coil_Open Detected" 0 "No Fault";
VAL_ 596 BDC_1_voltageErr 2 "lackvoltage" 1 "overvoltage" 0 "No Error";
VAL_ 596 BDC_1_TempWarn 1 "Temperature Warning" 0 "No Error";
VAL_ 596 BDC_1_MotorStatus 1 "Motor Running" 0 "Motor Stop";
VAL_ 602 Spd_Crl_Mode 5 "invalid" 4 "ISA" 3 "LIM" 2 "CC" 1 "ACC" 0 "OFF";
VAL_ 602 Spd_Crl_Sta 1 "ON" 0 "OFF";
VAL_ 602 LEDlitWarnReq 1 "Warning request" 0 "No warning request";
VAL_ 602 Charge 1 "Disable (LED ON)" 0 "Enable (LED OFF)";
VAL_ 602 ParkBrake 1 "On" 0 "Off";
VAL_ 659 Zone_Spd_Ctrl_Mode 5 "invalid" 4 "ISA" 3 "LIM" 2 "CC" 1 "ACC" 0 "OFF";
VAL_ 659 Zone_Spd_Ctrl_Sta 1 "ON" 0 "OFF";
VAL_ 659 RegenMode 7 "Invalid" 6 "One-Pedal" 5 "Level 5" 4 "Level 4" 3 "Level 3" 2 "Level 2" 1 "Level 1" 0 "Off";
VAL_ 659 DrSCPSysErrLmp 1 "Error" 0 "Normal";
VAL_ 778 EAC_Temp 1 "Fault" 0 "Normal";
VAL_ 778 PTCNTCStsHSC6 7 "all sensor bad" 6 "igbt sensor good , ptc in sensor bad  , ptc out sensor bad" 5 "igbt sensor bad , ptc in sensor good , ptc out sensor bad" 4 "igbt sensor good , ptc in sensor good , ptc out sensor bad" 3 "igbt sensor bad , ptc in sensor bad , ptc_out_sensor good" 2 "igbt sensor good , ptc in sensor bad , ptc_out_sensor good" 1 "igbt sensor bad , ptc in sensor good , ptc out sensor good" 0 "all sensor is good";
VAL_ 778 EAC_DrvVoltFalt 1 "Fault" 0 "Normal";
VAL_ 778 EAC_MotorLackFalt 1 "Fault" 0 "Normal";
VAL_ 778 EAC_OvLoadFalt 1 "Fault" 0 "Normal";
VAL_ 778 EAC_TempSnsrFalt 1 "Fault" 0 "Normal";
VAL_ 778 CompProEN 1 "Enable" 0 "Disable";
VAL_ 778 COMP_ComLost 1 "Fault" 0 "Normal";
VAL_ 778 COMP_IPM_HWFLt 1 "Fault" 0 "Normal";
VAL_ 778 COMP_IPM_TempOverFlt 1 "Fault" 0 "Normal";
VAL_ 778 COMP_CurOverProtect 1 "Fault" 0 "Normal";
VAL_ 778 COMP_VoltOverErr 1 "Fault" 0 "Normal";
VAL_ 778 COMP_VoltLessErr 1 "Fault" 0 "Normal";
VAL_ 778 COMP_CtrlCircFlt 1 "Fault" 0 "Normal";
VAL_ 778 COMP_Sta 3 "Limit state" 2 "Fault" 1 "Working" 0 "Standby";
VAL_ 778 COMP_Init 1 "Init Complete" 0 "Initializing";
VAL_ 778 COMP_SpdVaild 1 "invaild" 0 "valid";
VAL_ 778 COMP_CurVaild 1 "invaild" 0 "valid";
VAL_ 778 COMP_VoltVaild 1 "invaild" 0 "valid";
VAL_ 778 PTCOverVolHSC6 1 "Actived" 0 "Inactived";
VAL_ 778 PTCOverCrntHSC6 1 "Actived" 0 "Inactived";
VAL_ 778 PTCOverHeatHSC6 1 "Actived" 0 "Inactived";
VAL_ 778 PTCStsHSC6 3 "Prepare to Start" 2 "Emergency Stop" 1 "Working" 0 "Not Working";
VAL_ 778 PTCIGBTOverHeatHSC6 1 "over heat" 0 "igbt good";
VAL_ 778 PTCHVLckStsHSC6 1 "Fault" 0 "OK";
VAL_ 778 PTCIGBTStsHSC6 1 "Fault" 0 "Normal";
VAL_ 778 PTCUnderVolHSC6 1 "Actived" 0 "Inactived";
VAL_ 778 PTCFltLvlHSC6 3 "LEVEL 3" 2 "LEVEL 2" 1 "LEVEL 1" 0 "LEVEL 0";
VAL_ 796 BMSReqTapPosHSC6 7 "7 Tap" 6 "6 Tap" 5 "5 Tap" 4 "4 Tap" 3 "3 Tap" 2 "2 Tap" 1 "1 Tap" 0 "0 Tap";
VAL_ 796 BMSReqMdHSC6 3 "PWM Control" 2 "Tap Position Control" 1 "Power Control" 0 "No Request";
VAL_ 796 BMSEnbPTCHSC6 1 "On" 0 "Off";
VAL_ 805 ACT5_Stop_mode 1 "Stop" 0 "Normal";
VAL_ 805 ACT5_Speed_specification 5 "AutoSpeed" 4 "Speed_4" 3 "Speed_3" 2 "Speed_2" 1 "Speed_1";
VAL_ 805 ACT5_Select_position_specification 1 "Start_Position" 0 "Set_Position";
VAL_ 805 ACT5_Clear_Event_Flags 14 "AllEventClear" 0 "NotClear";
VAL_ 805 ACT4_Stop_mode 1 "Stop" 0 "Normal";
VAL_ 805 ACT4_Speed_specification 5 "AutoSpeed" 4 "Speed_4" 3 "Speed_3" 2 "Speed_2" 1 "Speed_1";
VAL_ 805 ACT4_Select_position_specification 1 "Start_Position" 0 "Set_Position";
VAL_ 805 ACT4_Clear_Event_Flags 14 "AllEventClear" 0 "NotClear";
VAL_ 805 ACT3_Stop_mode 1 "Stop" 0 "Normal";
VAL_ 805 ACT3_Speed_specification 5 "AutoSpeed" 4 "Speed_4" 3 "Speed_3" 2 "Speed_2" 1 "Speed_1";
VAL_ 805 ACT3_Select_position_specification 1 "Start_Position" 0 "Set_Position";
VAL_ 805 ACT3_Clear_Event_Flags 14 "AllEventClear" 0 "NotClear";
VAL_ 805 ACT2_Stop_mode 1 "Stop" 0 "Normal";
VAL_ 805 ACT2_Speed_specification 5 "AutoSpeed" 4 "Speed_4" 3 "Speed_3" 2 "Speed_2" 1 "Speed_1";
VAL_ 805 ACT2_Select_position_specification 1 "Start_Position" 0 "Set_Position";
VAL_ 805 ACT2_Clear_Event_Flags 14 "AllEventClear" 0 "NotClear";
VAL_ 805 ACT1_Stop_mode 1 "Stop" 0 "Normal";
VAL_ 805 ACT1_Speed_specification 5 "AutoSpeed" 4 "Speed_4" 3 "Speed_3" 2 "Speed_2" 1 "Speed_1";
VAL_ 805 ACT1_Select_position_specification 1 "Start_Position" 0 "Set_Position";
VAL_ 805 ACT1_Clear_Event_Flags 14 "AllEventClear" 0 "NotClear";
VAL_ 826 SWC_Drivemode_Sta 1 "Press" 0 "Release";
VAL_ 826 SWC_CANCEL_Sta 1 "Press" 0 "Release";
VAL_ 826 SWC_ACC_Sta 1 "Press" 0 "Release";
VAL_ 826 SWC_A_Resp_Err 1 "Error" 0 "Normal";
VAL_ 826 SWC_Distance_Sta 1 "Press" 0 "Release";
VAL_ 826 SWC_Down_Sta 1 "Press" 0 "Release";
VAL_ 826 SWC_RegenUp 1 "Press" 0 "Release";
VAL_ 826 SWC_Left_Sta 1 "Press" 0 "Release";
VAL_ 826 SWC_mode_Sta 1 "Press" 0 "Release";
VAL_ 826 SWC_resp_error 1 "Error" 0 "Normal";
VAL_ 826 SWC_Res_Up_Sta 1 "Press" 0 "Release";
VAL_ 826 SWC_RegenDown 1 "Press" 0 "Release";
VAL_ 826 SWC_Right_Sta 1 "Press" 0 "Release";
VAL_ 826 SWC_Set_down_Sta 1 "Press" 0 "Release";
VAL_ 826 SWC_Trip_Sta 1 "Press" 0 "Release";
VAL_ 826 SWC_Up_Sta 1 "Press" 0 "Release";
VAL_ 826 SWC_VR_Sta 1 "Press" 0 "Release";
VAL_ 826 SWC_Undefined_Sta 1 "Press" 0 "Release";
VAL_ 826 SWC_LKA_Sta 1 "Press" 0 "Release";
VAL_ 851 L_RRD_Wdw_Obs_InhibitSts 1 "Obs Inhibit status" 0 "Not Obs Inhibit status";
VAL_ 851 L_RRD_Wdw_OD_Sts 1 "In Anti-pinch status" 0 "Non anti-pinch status";
VAL_ 851 L_RRD_Wdw_Init 1 "Window init complete" 0 "Window init incomplete";
VAL_ 851 L_RRD_OverHeat_Protect 1 "Active" 0 "Inactive";
VAL_ 851 L_RRD_Motor_Relay_Error 1 "Error" 0 "Normal";
VAL_ 851 L_RRD_Motor_Ripple_Error 1 "Error" 0 "Normal";
VAL_ 851 L_RRD_Val_Wdw_Opened 127 "Invalid";
VAL_ 851 L_RRD_Wdw_PositionSts 3 "Invalid" 2 "Complete Close" 1 "Complete Open" 0 "Middle position";
VAL_ 851 L_RRD_Wdw_LocalSwitch 7 "Error" 6 "Reserved" 5 "Reserved" 4 "Auto Down" 3 "Auto Up" 2 "Manual Down" 1 "Manual Up" 0 "Inactive";
VAL_ 851 L_RRD_Wdw_Running_Sts 7 "Reserved" 5 "Reserved" 4 "Auto Down" 3 "Auto Up" 2 "Manual Down" 1 "Manual Up" 0 "Window stop";
VAL_ 851 RAPWL_01_LIN_Response_Error 1 "Error" 0 "Normal";
VAL_ 851 L_RLD_Wdw_Obs_InhibitSts 1 "Obs Inhibit status" 0 "Not Obs Inhibit status";
VAL_ 851 L_RLD_Wdw_OD_Sts 1 "In Anti-pinch status" 0 "Non anti-pinch status";
VAL_ 851 L_RLD_Wdw_Init 1 "Window init complete" 0 "Window init incomplete";
VAL_ 851 L_RLD_OverHeat_Protect 1 "Active" 0 "Inactive";
VAL_ 851 L_RLD_Motor_Relay_Error 1 "Error" 0 "Normal";
VAL_ 851 L_RLD_Motor_Ripple_Error 1 "Error" 0 "Normal";
VAL_ 851 L_RLD_Val_Wdw_Opened 127 "Invalid";
VAL_ 851 L_RLD_Wdw_PositionSts 3 "Invalid" 2 "Complete Close" 1 "Complete Open" 0 "Middle position";
VAL_ 851 L_RLD_Wdw_LocalSwitch 7 "Error" 6 "Reserved" 5 "Reserved" 4 "Auto Down" 3 "Auto Up" 2 "Manual Down" 1 "Manual Up" 0 "Inactive";
VAL_ 851 L_RLD_Wdw_Running_Sts 7 "Reserved" 5 "Reserved" 4 "Auto Down" 3 "Auto Up" 2 "Manual Down" 1 "Manual Up" 0 "Window stop";
VAL_ 851 PTG_Inner_SW_2 3 "Stuck" 2 "Press&Hold" 1 "Push" 0 "Off";
VAL_ 854 L_APM_IntellectClose 1 "Intelligent Close" 0 "No action";
VAL_ 854 L_Drv_Wdw_RRD_Switch 7 "Error" 6 "Reserved" 5 "Reserved" 4 "Auto Down" 3 "Auto Up" 2 "Manual Down" 1 "Manual Up" 0 "Inactive";
VAL_ 854 L_Drv_Wdw_RLD_Switch 7 "Error" 6 "Reserved" 5 "Reserved" 4 "Auto Down" 3 "Auto Up" 2 "Manual Down" 1 "Manual Up" 0 "Inactive";
VAL_ 854 L_Drv_Wdw_Pas_Switch 7 "Error" 6 "Reserved" 5 "Reserved" 4 "Auto Down" 3 "Auto Up" 2 "Manual Down" 1 "Manual Up" 0 "Inactive";
VAL_ 854 L_Pas_Wdw_Obs_InhibitSts 1 "Obs Inhibit status" 0 "Not Obs Inhibit status";
VAL_ 854 L_Pas_Wdw_OD_Sts 1 "In Anti-pinch status" 0 "Non anti-pinch status";
VAL_ 854 L_Pas_Wdw_Init 1 "Window init complete" 0 "Window init incomplete";
VAL_ 854 L_Pas_OverHeat_Protect 1 "Active" 0 "Inactive";
VAL_ 854 L_Pas_Motor_Relay_Error 1 "Error" 0 "Normal";
VAL_ 854 L_Pas_Motor_Ripple_Error 1 "Error" 0 "Normal";
VAL_ 854 L_Pas_Val_Wdw_Opened 127 "Invalid";
VAL_ 854 L_Pas_Wdw_PositionSts 3 "Invalid" 2 "Complete Close" 1 "Complete Open" 0 "Middle position";
VAL_ 854 L_Pas_Wdw_LocalSwitch 7 "Error" 6 "Reserved" 5 "Reserved" 4 "Auto Down" 3 "Auto Up" 2 "Manual Down" 1 "Manual Up" 0 "Inactive";
VAL_ 854 L_Pas_Wdw_Running_Sts 7 "Reserved" 5 "Reserved" 4 "Auto Down" 3 "Auto Up" 2 "Manual Down" 1 "Manual Up" 0 "Window stop";
VAL_ 854 L_Power_Status 3 "??>16V" 2 "??<9V" 1 "9V????16V" 0 "Default";
VAL_ 854 FAPWL_01_LIN_Response_Error 1 "Error" 0 "Normal";
VAL_ 854 L_Drv_Wdw_Obs_InhibitSts 1 "Obs Inhibit status" 0 "Not Obs Inhibit status";
VAL_ 854 L_Drv_Wdw_OD_Sts 1 "In Anti-pinch status" 0 "Non anti-pinch status";
VAL_ 854 L_Drv_Wdw_Init 1 "Window init complete" 0 "Window init incomplete";
VAL_ 854 L_Drv_OverHeat_Protect 1 "Active" 0 "Inactive";
VAL_ 854 L_Drv_Motor_Relay_Error 1 "Error" 0 "Normal";
VAL_ 854 L_Drv_Motor_Ripple_Error 1 "Error" 0 "Normal";
VAL_ 854 L_Drv_Val_Wdw_Opened 127 "Invalid";
VAL_ 854 L_Drv_Wdw_PositionSts 3 "Invalid" 2 "Complete Close" 1 "Complete Open" 0 "Middle position";
VAL_ 854 L_Drv_Wdw_LocalSwitch 7 "Error" 6 "Reserved" 5 "Reserved" 4 "Auto Down" 3 "Auto Up" 2 "Manual Down" 1 "Manual Up" 0 "Inactive";
VAL_ 854 L_Drv_Wdw_Running_Sts 7 "Reserved" 5 "Reserved" 4 "Auto Down" 3 "Auto Up" 2 "Manual Down" 1 "Manual Up" 0 "Window stop";
VAL_ 856 DSEAT_Mode 7 "manual & heater & ventilate" 6 "manual & ventilate" 5 "manual & heater" 4 "power & heater & ventilate" 3 "power & ventilate" 2 "power & heater" 1 "power" 0 "manual";
VAL_ 856 DSEAT_Vent_Sta 4 "OFF" 3 "3(High)" 2 "2(Middle)" 1 "1(Low)" 0 "No Request";
VAL_ 856 DSEAT_AntiAct_Sta 1 "Antitheft is activate" 0 "Antitheft is deactivate";
VAL_ 856 DSEAT_Anti_Sta 1 "on" 0 "off";
VAL_ 856 DSEAT_EntryAct_Sta 1 "Entry Function is activate" 0 "Entry Function is deactivate,";
VAL_ 856 DSEAT_EntryFun_Sta 1 "on" 0 "off";
VAL_ 856 DSEAT_Error_Sta 1 "Warning Request(IVI POP UP)" 0 "Normal";
VAL_ 917 PSEAT_Vent_Sta 4 "OFF" 3 "3(High)" 2 "2(Middle)" 1 "1(Low)" 0 "No Request";
VAL_ 917 PSEAT_Mode 7 "manual & heater & ventilate" 6 "manual & ventilate" 5 "manual & heater" 4 "power & heater & ventilate" 3 "power & ventilate" 2 "power & heater" 1 "power" 0 "manual";
VAL_ 917 PSEAT_Error_Sta 1 "Warning Request (IVI POP UP)" 0 "Normal";
VAL_ 1080 OTA_Progress_Rate 102 "Invalid" 101 "Not in progress" 100 "100%" 99 "99%" 0 "~0x64 0%~100%";
VAL_ 1080 OTA_MDA_Status 14 "Undefine" 13 "OTA Task Finished" 12 "Vehicle Update Complete" 11 "Update Failed" 10 "Download Failed" 9 "Countdown" 8 "Download Suspend" 7 "Vehicle Roll-Back" 6 "Vehicle Updating" 5 "Wait Update" 4 "Campaign Downloading" 3 "Wait Download" 2 "Ask Campaign" 1 "Ready" 0 "Not Ready";
VAL_ 1080 OTA_Network_Type 3 "Undefine" 2 "WiFi" 1 "LTE" 0 "Network Not Available";
VAL_ 1080 OTA_Mode 1 "OTA mode" 0 "Normal mode";
VAL_ 1080 OTA_DL_Available 1 "Ready for Download" 0 "Not Ready";
VAL_ 1080 OTA_InVehicle_FW 2 "FW Need Update" 1 "FW Up to Date" 0 "Not Confirm";
VAL_ 1080 OTA_Update_Available 1 "Ready for Update" 0 "Not Ready";
VAL_ 1080 OTA_Updating_ECU 30 "Invalid" 29 "HMI" 28 "W_PTC" 27 "EBM" 26 "AIRPTC" 25 "E_Compressor" 24 "Shifter" 23 "TELLTALE" 22 "MRR" 21 "SRR_M" 20 "FCM" 19 "EPS" 18 "EOP_F" 17 "EOP_R" 16 "MCU_F" 15 "MCU_R" 14 "eBST" 13 "ESC" 12 "APM" 11 "PSEAT" 10 "DSEAT" 9 "PTG" 8 "CCU" 7 "BMS" 6 "DKC" 5 "Zone_Dr" 4 "Zone_Fr" 3 "T-Box" 2 "IVI" 1 "FDC" 0 "No action";
VAL_ 1080 OTA_Lock_Req 1 "Lock Request" 0 "No action";
VAL_ 1080 OTA_Up_Backcount 122 "Invalid" 121 "No action" 0 "~0x78 0s~120s";
VAL_ 1080 OTA_TBOXResetReq 1 "Request reset" 0 "No request";
VAL_ 1090 Re_DoorLock 10 "outside mirror release" 9 "outside mirror fold" 8 "seek mute(flash)" 7 "Handle unlock" 6 "Unlock via BT" 5 "Lock via BT" 4 "PTG open via 4G" 3 "Seek(flash+honk)" 2 "Unlock via 4G" 1 "Lock via 4G" 0 "Normal";
VAL_ 1090 Antitheft_Zero 15 "Invalid" 10 "KSN/TP Learn Fail" 9 "KSN/TP Learn Pass" 8 "legal Key in In/Out(identical)" 7 "legal Key in In/Out(different)" 6 "legal Key in Indoor" 5 "legal Key in Outdoor" 4 "Forced to lift anti-theft" 3 "Tailgate Open/Close" 2 "Unlock" 1 "Lock" 0 "Default";
VAL_ 1090 TBOX_Re_VehData 3 "the data upload is NG" 2 "the data upload is OK" 1 "Request" 0 "No Request";
VAL_ 1090 TBOX_RemoteOn 2 "Reserved" 1 "Remote on" 0 "No Request";
VAL_ 1090 Re_PwrReqTbox 6 "Request for PowerOff" 5 "Request for ON" 4 "Request for Radio" 3 "Request for DTC" 2 "Request for ACTemp" 1 "Request for VehChk" 0 "No Request";
VAL_ 1090 TBOX_Remote_PW 16 "App 4Door AutoDown" 15 "App 4Door AutoUp" 14 "Stop" 13 "App RR" 12 "App RL ManualDown" 11 "App FR MaualDown" 10 "App FL ManualDown" 9 "App 4Door ManualDown" 8 "App RR AutoDown" 7 "App RR AutoUp" 6 "App RL AutoDown" 5 "App RL AutoUp" 4 "App FR AutoDown" 3 "App FR AutoUp" 2 "App FL AutoDown" 1 "App FL AutoUp" 0 "release";
VAL_ 1090 Uncounting_Req 3 "Invalid" 2 "Reserved" 1 "Counting Stop" 0 "No action";
VAL_ 1090 CbnPreACEnaReq 3 "Reserved" 2 "Not Set" 1 "Enable A/C" 0 "Disable A/C";
VAL_ 1090 CbnPreReq 3 "Reserved" 2 "Estimated time required" 1 "Start preconditioning" 0 "Stop preconditioning";
VAL_ 1090 ReOutsideMirror 3 "Undefined" 2 "Unfold" 1 "Fold" 0 "No Command";
VAL_ 1090 TBOX_Re_DTCData 3 "the data upload is NG" 2 "the data upload is OK" 1 "Request" 0 "No Request";
VAL_ 1090 TBOX_NET_SIG_STR 8 "wifi comes back" 7 "wifi leaves home" 6 "Error" 5 "no signal" 4 "4 bars" 3 "3 bars" 2 "2 bars" 1 "1 bar" 0 "Invalid";
VAL_ 1090 TBOX_TEST_STATUS 15 "Invalid" 8 "OTA updating" 7 "RS-232 Transceiver Failure" 6 "CAN Controller Failure" 5 "3G Module Failure" 4 "Flash Error" 3 "SIM Card Failed" 2 "ECU Internal Error" 1 "WM Self Test OK" 0 "WM Self Testing";
VAL_ 1090 Re_Radio 1 "Radio turn on" 0 "Radio turn off";
VAL_ 1090 PowerOff_T_Set 99 "100 min (max.)" 0 "1 min (min.)";
VAL_ 1090 Remote_AutoReq 1 "ON" 0 "OFF";
VAL_ 1090 Remote_MidAutoReq 1 "ON" 0 "OFF";
VAL_ 1174 TimeSyncFromBS_Month 15 "Not Used" 14 "Not Used" 13 "Not Used" 0 "invalid";
VAL_ 1280 NM_FUSION_PNI 1 "NM PDU contains Partial Network request information" 0 "NM PDU contains no Partial Network request information";
VAL_ 1280 NM_FUSION_Active_WU 1 "Node has woken up the network (active Wakeup)" 0 "Node has not woken up the network (passive wakeup)";
VAL_ 1280 NM_FUSION_CSB 1 "Start of synchronized shutdown is requested by main coordinator" 0 "Start of synchronized shutdown is not requested by main coordinator";
VAL_ 1280 NM_FUSION_Rpt_Msg_Req 1 "Repeat Message State requested" 0 "Repeat Message State not requested";
VAL_ 1280 NM_FUSION_ERROR_State 8 "BUS OFF_L2" 4 "BUS OFF_L1" 2 "ERROR PASSIVE" 1 "ERROR ACTIVE" 0 "Inactive";
VAL_ 1284 NM_ZONE_FR_PNI 1 "NM PDU contains Partial Network request information" 0 "NM PDU contains no Partial Network request information";
VAL_ 1284 NM_ZONE_FR_Active_WU 1 "Node has woken up the network (active Wakeup)" 0 "Node has not woken up the network (passive wakeup)";
VAL_ 1284 NM_ZONE_FR_CSB 1 "Start of synchronized shutdown is requested by main coordinator" 0 "Start of synchronized shutdown is not requested by main coordinator";
VAL_ 1284 NM_ZONE_FR_Rpt_Msg_Req 1 "Repeat Message State requested" 0 "Repeat Message State not requested";
VAL_ 1284 NM_ZONE_FR_ERROR_State 8 "BUS OFF_L2" 4 "BUS OFF_L1" 2 "ERROR PASSIVE" 1 "ERROR ACTIVE" 0 "Inactive";
VAL_ 1285 NM_DKC_PNI 1 "NM PDU contains Partial Network request information" 0 "NM PDU contains no Partial Network request information";
VAL_ 1285 NM_DKC_Active_WU 1 "Node has woken up the network (active Wakeup)" 0 "Node has not woken up the network (passive wakeup)";
VAL_ 1285 NM_DKC_CSB 1 "Start of synchronized shutdown is requested by main coordinator" 0 "Start of synchronized shutdown is not requested by main coordinator";
VAL_ 1285 NM_DKC_Rpt_Msg_Req 1 "Repeat Message State requested" 0 "Repeat Message State not requested";
VAL_ 1285 NM_DKC_ERROR_State 8 "BUS OFF_L2" 4 "BUS OFF_L1" 2 "ERROR PASSIVE" 1 "ERROR ACTIVE" 0 "Inactive";
VAL_ 1344 NM_ZONE_DR_PNI 1 "NM PDU contains Partial Network request information" 0 "NM PDU contains no Partial Network request information";
VAL_ 1344 NM_ZONE_DR_Active_WU 1 "Node has woken up the network (active Wakeup)" 0 "Node has not woken up the network (passive wakeup)";
VAL_ 1344 NM_ZONE_DR_CSB 1 "Start of synchronized shutdown is requested by main coordinator" 0 "Start of synchronized shutdown is not requested by main coordinator";
VAL_ 1344 NM_ZONE_DR_Rpt_Msg_Req 1 "Repeat Message State requested" 0 "Repeat Message State not requested";
VAL_ 1344 NM_ZONE_DR_ERROR_State 8 "BUS OFF_L2" 4 "BUS OFF_L1" 2 "ERROR PASSIVE" 1 "ERROR ACTIVE" 0 "Inactive";
VAL_ 881 PTG_HW_Ver 31 "V31" 1 "V1" 0 "Invalid";
VAL_ 881 PTG_SW_Ver 31 "V31" 1 "V1" 0 "Invalid";
VAL_ 881 PTG_Is_Set_Height 1 "On" 0 "Off";
VAL_ 881 PTG_AutoStaus 1 "Auto mode" 0 "Manual mode";
VAL_ 881 PTG_Exist 1 "Exist" 0 "Not Exist";
VAL_ 881 PTG_RDIL_Sta 3 "Invalid" 2 "Flash 3 times" 1 "Flash twice" 0 "No request";
VAL_ 881 PTG_Inner_SW_1 3 "Stuck" 2 "Press&Hold" 1 "Push" 0 "Off";
VAL_ 881 PTG_Sys_Sta 3 "Invalid" 2 "Abnormality" 1 "Normal" 0 "Initializing";
VAL_ 881 PTG_Full_Lock 1 "On" 0 "Off";
VAL_ 881 PTG_Active_Sta 7 "Pinch Reverse" 6 "Hold" 5 "Pause" 4 "Auto Closing" 3 "Auto Opening" 2 "Idle Full Open" 1 "Idle Full Close" 0 "Invalid";
VAL_ 881 PTG_Warning_Sta 7 "Reserved" 6 "User Operation Denied" 5 "User Operation Accepted" 4 "Memory position" 3 "Warning" 2 "Forced stop" 1 "Antipinch reverse" 0 "Off";
VAL_ 881 PTG_Half_Lock 1 "On" 0 "Off";
VAL_ 881 PTG_Open_Ratio 127 "127% (Invalid)" 100 "100% (Max)" 0 "0% (Min)";
VAL_ 928 FDC_VCU_ReqHWReset_Cmd 25 "EBM power off" 24 "ECompressor power off" 23 "WPTC power off" 22 "HMI power off" 21 "TBox power off" 20 "IVI power off" 19 "AirPTC power off" 18 "PSEAT power off" 17 "DSEAT power off" 16 "ABM power off" 15 "EPS power off" 14 "BMS power off" 13 "EOP_F power off" 12 "EOP_R power off" 11 "CCU power off" 10 "DKC power off" 9 "MRR power off" 8 "SRR_M power off" 7 "FCM power off" 6 "MCU_F power off" 5 "MCU_R power off" 4 "Shifter power off" 3 "Telltale power off" 2 "EBST power off" 1 "ESC power off" 0 "No request";
